VERSION ""

NS_ :

BS_:

BU_: TCM_Diesel ECM_Diesel BECMB_EPM TCM ECM Generic_BCM GWM _delete APIM BCM DCDC_VQM PAM TSTR PCM

BO_ 753 Vehicle_Stat_HS1: 8 GWM
 SG_ Em_D_Stat_UB : 54|1@0+ (1,0) [0|1] "SED"  BCM
 SG_ Em_D_Stat : 40|2@0+ (1,0) [0|3] "SED"  BCM
 SG_ TrlrAidEnbl_D_Stat_UB : 62|1@0+ (1,0) [0|1] "SED"  PCM
 SG_ TrlrAidEnbl_D_Stat : 58|3@0+ (1,0) [0|7] "SED"  ECM_Diesel,ECM,PCM
 SG_ SeatOccDrv_B_Stat_UB : 34|1@0+ (1,0) [0|1] "SED" Vector__XXX
 SG_ SeatOccDrv_B_Stat : 35|1@0+ (1,0) [0|1] "SED" Vector__XXX
 SG_ TrlrAidSetup_D_Rq_UB : 59|1@0+ (1,0) [0|1] "SED"  PAM
 SG_ TrlrAidSetup_D_Rq : 61|2@0+ (1,0) [0|3] "SED"  PAM
 SG_ TurnLampRrOut_B_Stat_UB : 36|1@0+ (1,0) [0|1] "SED"  BCM
 SG_ TurnLampRrOut_B_Stat : 37|1@0+ (1,0) [0|1] "SED"  BCM
 SG_ TurnLampRlOut_B_Stat_UB : 38|1@0+ (1,0) [0|1] "SED"  BCM
 SG_ TurnLampRlOut_B_Stat : 39|1@0+ (1,0) [0|1] "SED"  BCM
 SG_ CnvtTopPos_Up_Stat_UB : 24|1@0+ (1,0) [0|1] "SED"  BCM
 SG_ IsaOffst_D_Rq_UB : 63|1@0+ (1,0) [0|1] "SED" Vector__XXX
 SG_ GlvBoxRleas_No_Actl : 31|3@0+ (1,0) [0|7] "unitless"  BCM
 SG_ GlvBoxRleas_No_Actl_UB : 28|1@0+ (1,0) [0|1] "SED"  BCM
 SG_ ValetMode_D_Stat_UB : 20|1@0+ (1,0) [0|1] "SED"  BCM
 SG_ RollCodeValet_UB : 21|1@0+ (1,0) [0|1] "SED"  BCM
 SG_ ApaMdeStat_D_RqDrv_UB : 16|1@0+ (1,0) [0|1] "SED"  PAM
 SG_ SlMde_D_Rq : 49|2@0+ (1,0) [0|3] "SED" Vector__XXX
 SG_ IsaOffst_D_Rq : 53|4@0+ (1,0) [0|15] "SED" Vector__XXX
 SG_ ApaMdeStat_D_RqDrv : 19|3@0+ (1,0) [0|7] "SED"  PAM
 SG_ ValetMode_D_Stat : 23|2@0+ (1,0) [0|3] "SED"  BCM
 SG_ RollCodeValet : 7|16@0+ (1,0) [0|65535] "Unitless"  BCM
 SG_ CnvtTopPos_Up_Stat : 25|1@0+ (1,0) [0|1] "SED"  BCM
 SG_ CnvtTopPos_Dn_Stat_UB : 26|1@0+ (1,0) [0|1] "SED"  BCM
 SG_ CnvtTopPos_Dn_Stat : 27|1@0+ (1,0) [0|1] "SED"  BCM

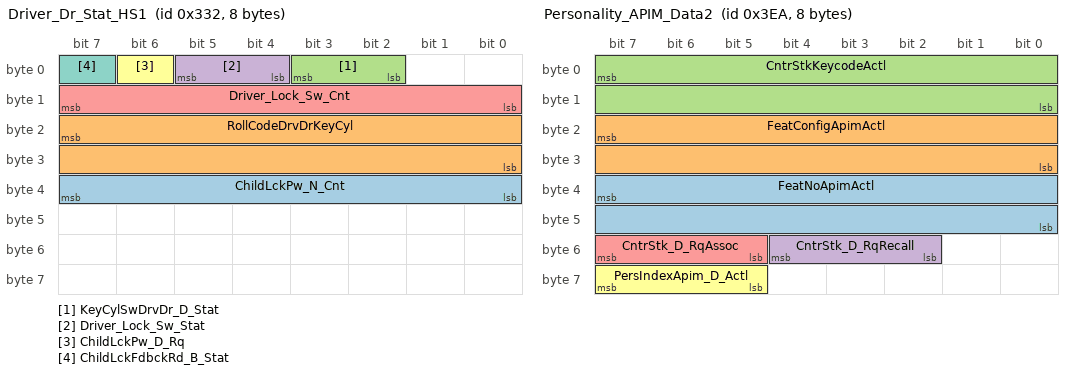
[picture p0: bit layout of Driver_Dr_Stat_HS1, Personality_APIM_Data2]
BO_ 818 Driver_Dr_Stat_HS1: 8 GWM
 SG_ ChildLckPw_N_Cnt : 39|8@0+ (1,0) [0|255] "unitless"  BCM
 SG_ RollCodeDrvDrKeyCyl : 23|16@0+ (1,0) [0|65535] "Unitless"  BCM
 SG_ KeyCylSwDrvDr_D_Stat : 3|2@0+ (1,0) [0|3] "SED"  BCM
 SG_ Driver_Lock_Sw_Stat : 5|2@0+ (1,0) [0|3] "SED"  BCM
 SG_ Driver_Lock_Sw_Cnt : 15|8@0+ (1,0) [0|255] "Cnt"  BCM
 SG_ ChildLckPw_D_Rq : 6|1@0+ (1,0) [0|1] "SED"  BCM
 SG_ ChildLckFdbckRd_B_Stat : 7|1@0+ (1,0) [0|1] "SED"  BCM

BO_ 817 Locking_Systems_2: 8 BCM
 SG_ ChildLckMde_B_Stat : 56|1@0+ (1,0) [0|1] "SED"  GWM
 SG_ VehLckInd_D_Rq : 58|2@0+ (1,0) [0|3] "SED"  GWM
 SG_ DrTgateOpen_B_Rq : 59|1@0+ (1,0) [0|1] "SED"  GWM
 SG_ DrTgateExtSwMde_B_Stat : 32|1@0+ (1,0) [0|1] "SED"  GWM
 SG_ Remote_Device_Feedback : 50|3@0+ (1,0) [0|7] "SED"  GWM
 SG_ Veh_Lock_Requestor : 55|5@0+ (1,0) [0|31] "SED"  GWM
 SG_ R_Pwr_Sliding_Dr_Rqst : 36|1@0+ (1,0) [0|1] "SED"  GWM
 SG_ Power_Liftgate_Rqst : 0|1@0+ (1,0) [0|1] "SED"  GWM
 SG_ Veh_Lock_EvNum : 47|8@0+ (1,0) [0|255] "unitless"  GWM
 SG_ Power_Decklid_Rqst : 1|1@0+ (1,0) [0|1] "SED"  GWM
 SG_ L_Pwr_Sliding_Dr_Rqst : 3|1@0+ (1,0) [0|1] "SED"  GWM
 SG_ Keyfob_Pad_Msg_Count : 15|8@0+ (1,0) [0|255] "Counts"  GWM
 SG_ Veh_Lock_Sub_Id : 63|4@0+ (1,0) [0|15] "SED"  GWM
 SG_ Veh_Lock_Status : 34|2@0+ (1,0) [0|3] "SED"  GWM
 SG_ ChildLck_D_Dsply : 7|2@0+ (1,0) [0|3] "SED"  GWM
 SG_ WindowLockout_B_Stat : 35|1@0+ (1,0) [0|1] "SED"  GWM
 SG_ RollCodeUnlock : 23|16@0+ (1,0) [0|65535] "Unitless"  GWM
 SG_ Lockmsgtxt_D_Rq : 39|3@0+ (1,0) [0|7] "SED"  GWM
 SG_ FobComm_D_Stat : 5|2@0+ (1,0) [0|3] "SED"  GWM
 SG_ LockInhibit : 2|1@0+ (1,0) [0|1] "SED"  GWM

BO_ 1002 Personality_APIM_Data2: 8 APIM
 SG_ FeatNoApimActl : 39|16@0+ (1,0) [0|65535] "Number"  GWM
 SG_ FeatConfigApimActl : 23|16@0+ (1,0) [0|65535] "Number"  GWM
 SG_ CntrStkKeycodeActl : 7|16@0+ (1,0) [0|65535] "Undefined"  GWM,BCM
 SG_ CntrStk_D_RqRecall : 52|3@0+ (1,0) [0|7] "SED"  GWM,BCM
 SG_ CntrStk_D_RqAssoc : 55|3@0+ (1,0) [0|7] "SED"  GWM,BCM
 SG_ PersIndexApim_D_Actl : 63|3@0+ (1,0) [0|7] "SED"  GWM

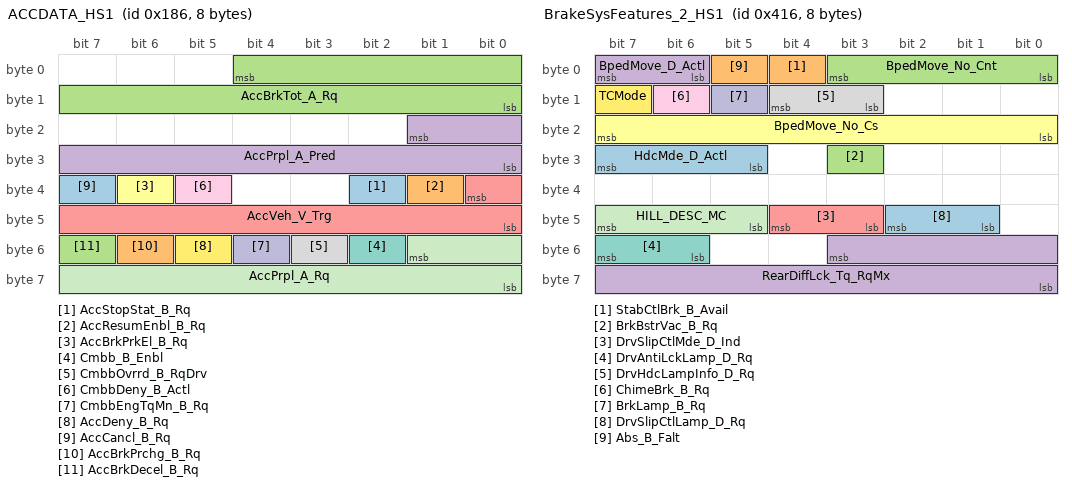
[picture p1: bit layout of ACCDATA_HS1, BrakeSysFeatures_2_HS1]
BO_ 390 ACCDATA_HS1: 8 GWM
 SG_ AccStopStat_B_Rq : 34|1@0+ (1,0) [0|1] "SED"  ECM,ECM_Diesel,PCM
 SG_ AccResumEnbl_B_Rq : 33|1@0+ (1,0) [0|1] "SED"  ECM,ECM_Diesel,PCM
 SG_ AccBrkTot_A_Rq : 4|13@0+ (0.0039,-20) [-20|11.9449] "m/s^2" Vector__XXX
 SG_ AccPrpl_A_Pred : 17|10@0+ (0.01,-5) [-5|5.23] "m/s^2"  ECM_Diesel,ECM,PCM
 SG_ AccVeh_V_Trg : 32|9@0+ (0.5,0) [0|255.5] "kph"  TCM_Diesel,ECM_Diesel,TCM,ECM,PCM
 SG_ AccBrkPrkEl_B_Rq : 38|1@0+ (1,0) [0|1] "SED" Vector__XXX
 SG_ Cmbb_B_Enbl : 50|1@0+ (1,0) [0|1] "SED" Vector__XXX
 SG_ CmbbOvrrd_B_RqDrv : 51|1@0+ (1,0) [0|1] "SED" Vector__XXX
 SG_ CmbbDeny_B_Actl : 37|1@0+ (1,0) [0|1] "SED" Vector__XXX
 SG_ CmbbEngTqMn_B_Rq : 52|1@0+ (1,0) [0|1] "SED"  ECM,ECM_Diesel,PCM
 SG_ AccPrpl_A_Rq : 49|10@0+ (0.01,-5) [-5|5.23] "m/s^2"  ECM_Diesel,ECM,PCM
 SG_ AccDeny_B_Rq : 53|1@0+ (1,0) [0|1] "SED"  ECM_Diesel,ECM,PCM
 SG_ AccCancl_B_Rq : 39|1@0+ (1,0) [0|1] "SED"  ECM_Diesel,ECM,PCM
 SG_ AccBrkPrchg_B_Rq : 54|1@0+ (1,0) [0|1] "SED" Vector__XXX
 SG_ AccBrkDecel_B_Rq : 55|1@0+ (1,0) [0|1] "SED" Vector__XXX

BO_ 1046 BrakeSysFeatures_2_HS1: 8 GWM
 SG_ HdcMde_D_Actl : 31|3@0+ (1,0) [0|7] "SED"  ECM
 SG_ StabCtlBrk_B_Avail : 4|1@0+ (1,0) [0|1] "SED" Vector__XXX
 SG_ BrkBstrVac_B_Rq : 27|1@0+ (1,0) [0|1] "Discrete"  ECM_Diesel,PCM
 SG_ RearDiffLck_Tq_RqMx : 51|12@0+ (1,0) [0|4095] "Nm"  ECM_Diesel
 SG_ DrvSlipCtlMde_D_Ind : 44|2@0+ (1,0) [0|3] "SED"  ECM_Diesel,ECM,PCM,PAM
 SG_ BpedMove_No_Cs : 23|8@0+ (1,0) [0|255] "Unitless"  ECM_Diesel,ECM,PCM
 SG_ DrvAntiLckLamp_D_Rq : 55|2@0+ (1,0) [0|3] "SED"  ECM_Diesel,PAM
 SG_ DrvHdcLampInfo_D_Rq : 12|2@0+ (1,0) [0|3] "SED" Vector__XXX
 SG_ ChimeBrk_B_Rq : 14|1@0+ (1,0) [0|1] "SED" Vector__XXX
 SG_ BrkLamp_B_Rq : 13|1@0+ (1,0) [0|1] "SED"  ECM_Diesel
 SG_ HILL_DESC_MC : 47|3@0+ (1,0) [0|7] "SED" Vector__XXX
 SG_ TCMode : 15|1@0+ (1,0) [0|1] "SED"  ECM_Diesel,ECM,PAM,PCM
 SG_ DrvSlipCtlLamp_D_Rq : 42|2@0+ (1,0) [0|3] "SED"  ECM_Diesel,ECM,PCM,PAM
 SG_ Abs_B_Falt : 5|1@0+ (1,0) [0|1] "SED"  ECM_Diesel,ECM,PCM
 SG_ BpedMove_No_Cnt : 3|4@0+ (1,0) [0|15] "Unitless"  ECM_Diesel,ECM,PCM
 SG_ BpedMove_D_Actl : 7|2@0+ (1,0) [0|3] "SED"  ECM_Diesel,ECM,PCM

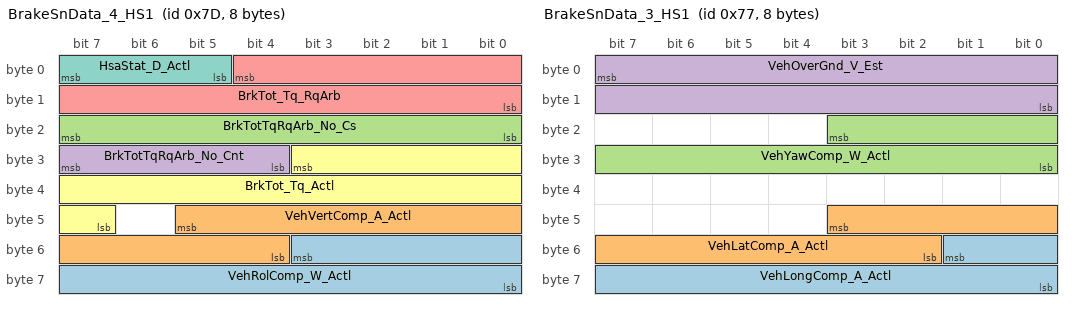
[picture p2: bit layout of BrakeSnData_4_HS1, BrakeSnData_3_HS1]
BO_ 125 BrakeSnData_4_HS1: 8 GWM
 SG_ VehRolComp_W_Actl : 51|12@0+ (0.03663,-75) [-75|74.92659] "degrees/sec" Vector__XXX
 SG_ VehVertComp_A_Actl : 45|10@0+ (0.035,-17.9) [-17.9|17.835] "m/s^2" Vector__XXX
 SG_ BrkTotTqRqArb_No_Cs : 23|8@0+ (1,0) [0|255] "Unitless"  ECM_Diesel,PCM,ECM
 SG_ BrkTotTqRqArb_No_Cnt : 31|4@0+ (1,0) [0|15] "Unitless"  ECM_Diesel,PCM,ECM
 SG_ BrkTot_Tq_RqArb : 4|13@0+ (4,0) [0|32756] "Nm"  TCM_Diesel,ECM_Diesel,TCM,ECM,PCM
 SG_ BrkTot_Tq_Actl : 27|13@0+ (4,0) [0|32756] "Nm"  ECM_Diesel,ECM,PCM
 SG_ HsaStat_D_Actl : 7|3@0+ (1,0) [0|7] "SED"  ECM_Diesel,ECM,PCM

BO_ 119 BrakeSnData_3_HS1: 8 GWM
 SG_ VehLongComp_A_Actl : 49|10@0+ (0.035,-17.9) [-17.9|17.835] "m/s^2"  TCM_Diesel,ECM_Diesel,TCM,ECM,PCM
 SG_ VehLatComp_A_Actl : 43|10@0+ (0.035,-17.9) [-17.9|17.835] "m/s^2"  TCM_Diesel,ECM_Diesel,TCM,ECM,PCM
 SG_ VehYawComp_W_Actl : 19|12@0+ (0.03663,-75) [-75|74.92659] "deg/s"  TCM_Diesel,ECM_Diesel,TCM,ECM,PAM,PCM
 SG_ VehOverGnd_V_Est : 7|16@0+ (0.01,0) [0|655.33] "kph"  BCM

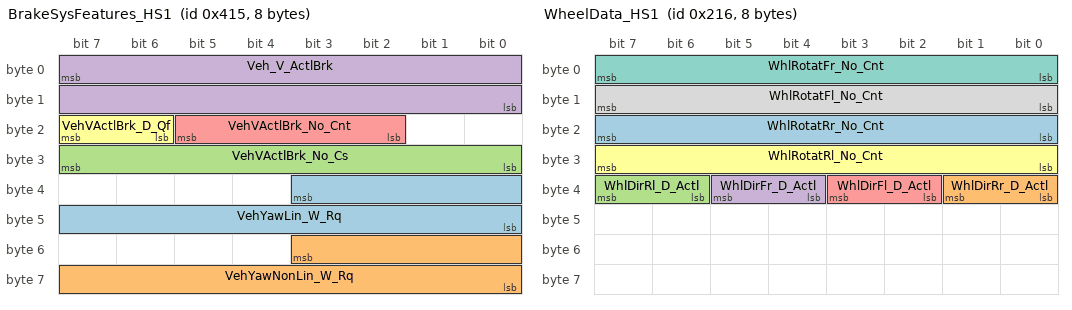
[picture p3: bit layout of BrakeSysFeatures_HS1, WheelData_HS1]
BO_ 1045 BrakeSysFeatures_HS1: 8 GWM
 SG_ VehYawLin_W_Rq : 35|12@0+ (0.03663,-75) [-75|74.92659] "deg/s" Vector__XXX
 SG_ VehYawNonLin_W_Rq : 51|12@0+ (0.03663,-75) [-75|74.92659] "deg/s" Vector__XXX
 SG_ VehVActlBrk_No_Cs : 31|8@0+ (1,0) [0|255] "Unitless"  TCM,TCM_Diesel,ECM_Diesel,ECM,PCM,BCM
 SG_ Veh_V_ActlBrk : 7|16@0+ (0.01,0) [0|655.35] "kph"  TCM,TCM_Diesel,ECM_Diesel,ECM,PCM,PAM,BCM
 SG_ VehVActlBrk_No_Cnt : 21|4@0+ (1,0) [0|15] "Unitless"  TCM,TCM_Diesel,ECM_Diesel,ECM,PCM,BCM
 SG_ VehVActlBrk_D_Qf : 23|2@0+ (1,0) [0|3] "SED"  TCM,TCM_Diesel,ECM_Diesel,ECM,PCM,PAM,BCM

BO_ 534 WheelData_HS1: 8 GWM
 SG_ WhlRotatRr_No_Cnt : 23|8@0+ (1,0) [0|255] "Unitless"  BCM,PAM
 SG_ WhlDirRr_D_Actl : 33|2@0+ (1,0) [0|3] "SED"  PAM
 SG_ WhlDirRl_D_Actl : 39|2@0+ (1,0) [0|3] "SED"  PAM
 SG_ WhlDirFr_D_Actl : 37|2@0+ (1,0) [0|3] "SED"  PAM
 SG_ WhlDirFl_D_Actl : 35|2@0+ (1,0) [0|3] "SED"  PAM
 SG_ WhlRotatRl_No_Cnt : 31|8@0+ (1,0) [0|255] "Unitless"  BCM,PAM
 SG_ WhlRotatFr_No_Cnt : 7|8@0+ (1,0) [0|255] "Unitless"  BCM,PAM
 SG_ WhlRotatFl_No_Cnt : 15|8@0+ (1,0) [0|255] "Unitless"  BCM,PAM

BO_ 531 DesiredTorqBrk_HS1: 8 GWM
 SG_ AccStopActv_B_ActlBrk : 22|1@0+ (1,0) [0|1] "SED"  ECM,ECM_Diesel,PCM
 SG_ TracCtlPtActv_B_Actl : 31|1@0+ (1,0) [0|1] "SED"  TCM_Diesel,ECM_Diesel,TCM,ECM,PCM,PAM
 SG_ StabCtlBrkActv_B_Actl : 23|1@0+ (1,0) [0|1] "SED"  TCM_Diesel,ECM_Diesel,TCM,ECM,PCM,PAM
 SG_ CmbbBrkPrchg_B_Actl : 59|1@0+ (1,0) [0|1] "SED" Vector__XXX
 SG_ CmbbBrkDecel_B_Actl : 58|1@0+ (1,0) [0|1] "SED" Vector__XXX
 SG_ CmbbBaSensInc_B_Actl : 57|1@0+ (1,0) [0|1] "SED" Vector__XXX
 SG_ AccBrkWarm_B_Actl : 63|1@0+ (1,0) [0|1] "SED" Vector__XXX
 SG_ AccBrkTotTqMn_B_Actl : 62|1@0+ (1,0) [0|1] "SED" Vector__XXX
 SG_ AccBrkPrchgActv_B_Actl : 61|1@0+ (1,0) [0|1] "SED" Vector__XXX
 SG_ AccBrkDis_B_Actl : 44|1@0+ (1,0) [0|1] "SED" Vector__XXX
 SG_ AccBrkDeny_B_Actl : 42|1@0+ (1,0) [0|1] "SED"  ECM_Diesel,ECM,PCM
 SG_ AccBrkActv_B_Actl : 43|1@0+ (1,0) [0|1] "SED"  ECM_Diesel
 SG_ PrplDrgCtlActv_B_Actl : 46|1@0+ (1,0) [0|1] "SED"  TCM_Diesel,ECM_Diesel,TCM,ECM,PCM
 SG_ PrplWhlTot_Tq_RqMx : 7|16@0+ (4,-131072) [-131072|131068] "Nm"  ECM_Diesel,ECM,PCM
 SG_ AbsActv_B_Actl : 45|1@0+ (1,0) [0|1] "SED"  TCM_Diesel,ECM_Diesel,TCM,ECM,PCM,PAM
 SG_ CmbbBrkDis_B_Actl : 56|1@0+ (1,0) [0|1] "SED" Vector__XXX
 SG_ CmbbDeny_B_ActlBrk : 60|1@0+ (1,0) [0|1] "SED"  ECM,ECM_Diesel,PCM
 SG_ CcDis_B_Cmd : 47|1@0+ (1,0) [0|1] "SED"  ECM_Diesel,ECM,PCM
 SG_ VehLongOvrGnd_A_Est : 41|10@0+ (0.035,-17.9) [-17.9|17.835] "m/s^2" Vector__XXX
 SG_ PrkBrkStatus : 26|3@0+ (1,0) [0|7] "SED"  TCM,TCM_Diesel,ECM_Diesel,ECM,BCM,PCM

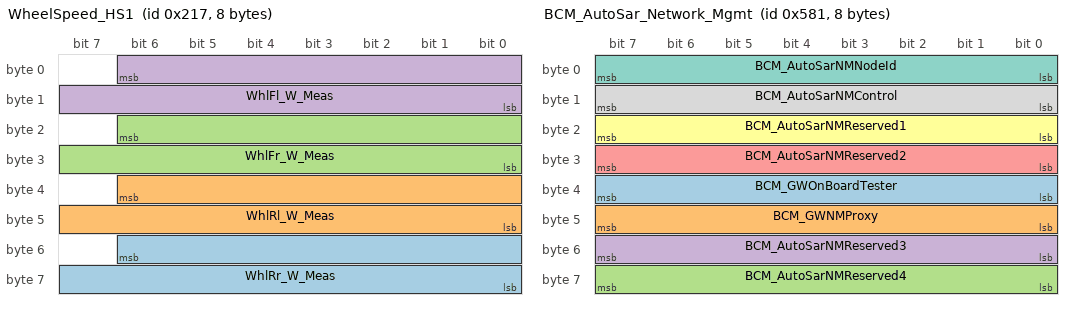
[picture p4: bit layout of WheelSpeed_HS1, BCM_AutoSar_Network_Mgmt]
BO_ 535 WheelSpeed_HS1: 8 GWM
 SG_ WhlRr_W_Meas : 54|15@0+ (0.01,0) [0|327.65] "rad/s"  TCM_Diesel,ECM_Diesel,TCM,ECM,PAM,BCM,PCM
 SG_ WhlRl_W_Meas : 38|15@0+ (0.01,0) [0|327.65] "rad/s"  TCM_Diesel,ECM_Diesel,TCM,ECM,BCM,PCM,PAM
 SG_ WhlFr_W_Meas : 22|15@0+ (0.01,0) [0|327.65] "rad/s"  TCM_Diesel,ECM_Diesel,TCM,ECM,BCM,PCM,PAM
 SG_ WhlFl_W_Meas : 6|15@0+ (0.01,0) [0|327.65] "rad/s"  TCM_Diesel,ECM_Diesel,TCM,ECM,BCM,PCM,PAM

BO_ 1409 BCM_AutoSar_Network_Mgmt: 8 BCM
 SG_ BCM_GWOnBoardTester : 39|8@0+ (1,0) [0|255] "unitless"  APIM,BECMB_EPM,ECM,ECM_Diesel,GWM,PCM,TCM,TCM_Diesel
 SG_ BCM_GWNMProxy : 47|8@0+ (1,0) [0|255] "unitless"  APIM,BECMB_EPM,ECM,ECM_Diesel,GWM,PCM,TCM,TCM_Diesel
 SG_ BCM_AutoSarNMReserved4 : 63|8@0+ (1,0) [0|255] "unitless"  APIM,BECMB_EPM,ECM,ECM_Diesel,GWM,PCM,TCM,TCM_Diesel
 SG_ BCM_AutoSarNMReserved3 : 55|8@0+ (1,0) [0|255] "unitless"  APIM,BECMB_EPM,ECM,ECM_Diesel,GWM,PCM,TCM,TCM_Diesel
 SG_ BCM_AutoSarNMReserved2 : 31|8@0+ (1,0) [0|255] "unitless"  APIM,BECMB_EPM,ECM,ECM_Diesel,GWM,PCM,TCM,TCM_Diesel
 SG_ BCM_AutoSarNMReserved1 : 23|8@0+ (1,0) [0|255] "unitless"  APIM,BECMB_EPM,ECM,ECM_Diesel,GWM,PCM,TCM,TCM_Diesel
 SG_ BCM_AutoSarNMNodeId : 7|8@0+ (1,0) [0|255] "unitless"  APIM,BECMB_EPM,ECM,ECM_Diesel,GWM,PCM,TCM,TCM_Diesel
 SG_ BCM_AutoSarNMControl : 15|8@0+ (1,0) [0|255] "unitless"  APIM,BECMB_EPM,ECM,ECM_Diesel,GWM,PCM,TCM,TCM_Diesel

BO_ 1846 TesterPhysicalReqPAM: 8 TSTR
 SG_ TesterPhysicalReqPAM : 7|64@0+ (1,0) [0|1.84467E+019] "unitless"  PAM

BO_ 1854 TesterPhysicalResPAM: 8 PAM
 SG_ TesterPhysicalResPAM : 7|64@0+ (1,0) [0|1.84467E+019] "unitless"  TSTR

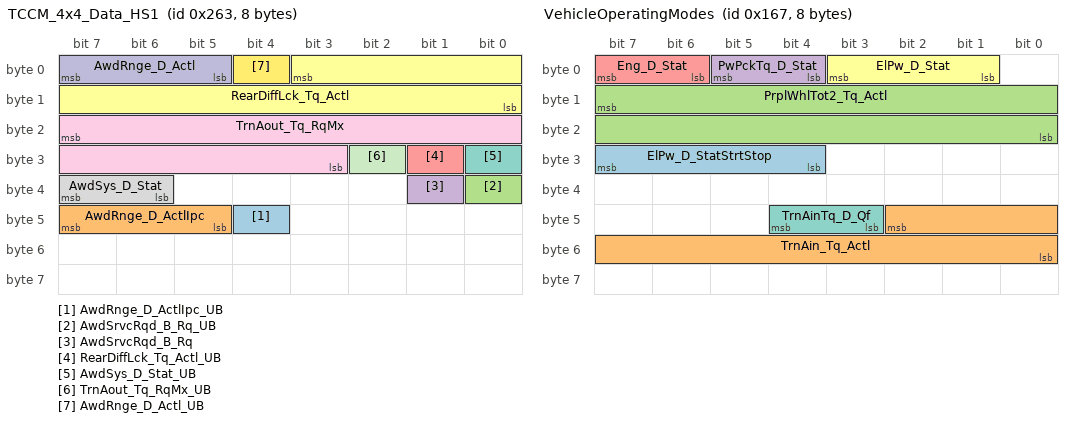
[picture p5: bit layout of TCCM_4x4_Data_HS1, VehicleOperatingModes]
BO_ 611 TCCM_4x4_Data_HS1: 8 GWM
 SG_ AwdRnge_D_ActlIpc_UB : 44|1@0+ (1,0) [0|1] "SED" Vector__XXX
 SG_ AwdRnge_D_ActlIpc : 47|3@0+ (1,0) [0|7] "SED"  ECM_Diesel
 SG_ AwdSrvcRqd_B_Rq_UB : 32|1@0+ (1,0) [0|1] "SED"  PCM,TCM_Diesel,TCM
 SG_ AwdSrvcRqd_B_Rq : 33|1@0+ (1,0) [0|1] "SED"  TCM_Diesel,TCM,PCM
 SG_ RearDiffLck_Tq_Actl_UB : 25|1@0+ (1,0) [0|1] "SED"  ECM_Diesel,ECM,PCM
 SG_ RearDiffLck_Tq_Actl : 3|12@0+ (1,0) [0|4093] "Nm"  ECM_Diesel,ECM,PCM
 SG_ AwdSys_D_Stat_UB : 24|1@0+ (1,0) [0|1] "SED" Vector__XXX
 SG_ AwdSys_D_Stat : 39|2@0+ (1,0) [0|3] "SED"  ECM_Diesel,ECM,PCM
 SG_ TrnAout_Tq_RqMx : 23|13@0+ (1,-1250) [-1250|6941] "Nm"  ECM_Diesel,ECM,PCM
 SG_ AwdRnge_D_Actl : 7|3@0+ (1,0) [0|7] "SED"  TCM_Diesel,ECM_Diesel,TCM,ECM,PCM
 SG_ TrnAout_Tq_RqMx_UB : 26|1@0+ (1,0) [0|1] "SED" Vector__XXX
 SG_ AwdRnge_D_Actl_UB : 4|1@0+ (1,0) [0|1] "SED"  TCM_Diesel,ECM_Diesel,TCM,ECM,PCM

BO_ 1109 eCall_Info_HS1: 8 APIM
 SG_ eCallConfirmation : 7|3@0+ (1,0) [0|7] "SED"  GWM,BCM

BO_ 359 VehicleOperatingModes: 8 PCM
 SG_ ElPw_D_StatStrtStop : 31|4@0+ (1,0) [0|15] "SED"  GWM
 SG_ TrnAin_Tq_Actl : 42|11@0+ (1,-500) [-500|1547] "Nm"  GWM
 SG_ PrplWhlTot2_Tq_Actl : 15|16@0+ (4,-131072) [-131072|131060] "Nm"  GWM
 SG_ PwPckTq_D_Stat : 5|2@0+ (1,0) [0|3] "SED"  TCM,TCM_Diesel,PAM,BCM,GWM
 SG_ Eng_D_Stat : 7|2@0+ (1,0) [0|3] "SED"  DCDC_VQM,BCM,GWM
 SG_ ElPw_D_Stat : 3|3@0+ (1,0) [0|7] "SED"  TCM,TCM_Diesel,PAM,BCM,GWM
 SG_ TrnAinTq_D_Qf : 44|2@0+ (1,0) [0|3] "SED"  GWM

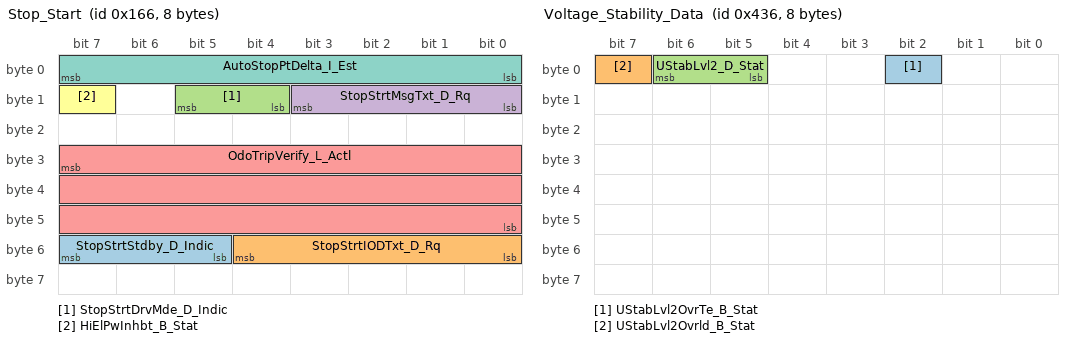
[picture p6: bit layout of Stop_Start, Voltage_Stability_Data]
BO_ 358 Stop_Start: 8 PCM
 SG_ StopStrtStdby_D_Indic : 55|3@0+ (1,0) [0|7] "SED"  GWM
 SG_ StopStrtIODTxt_D_Rq : 52|5@0+ (1,0) [0|31] "SED"  GWM
 SG_ StopStrtDrvMde_D_Indic : 13|2@0+ (1,0) [0|3] "SED"  BCM,GWM
 SG_ StopStrtMsgTxt_D_Rq : 11|4@0+ (1,0) [0|15] "SED"  GWM
 SG_ OdoTripVerify_L_Actl : 31|24@0+ (0.1,0) [0|1677721.4] "km"  GWM
 SG_ HiElPwInhbt_B_Stat : 15|1@0+ (1,0) [0|1] "SED"  GWM
 SG_ AutoStopPtDelta_I_Est : 7|8@0+ (1,-127) [-127|127] "Amps"  GWM,BCM

BO_ 1078 Voltage_Stability_Data: 8 DCDC_VQM
 SG_ UStabLvl2OvrTe_B_Stat : 2|1@0+ (1,0) [0|1] "SED"  ECM_Diesel,ECM,PCM
 SG_ UStabLvl2Ovrld_B_Stat : 7|1@0+ (1,0) [0|1] "SED"  ECM_Diesel,ECM,PCM
 SG_ UStabLvl2_D_Stat : 6|2@0+ (1,0) [0|3] "SED"  ECM_Diesel,ECM,PCM

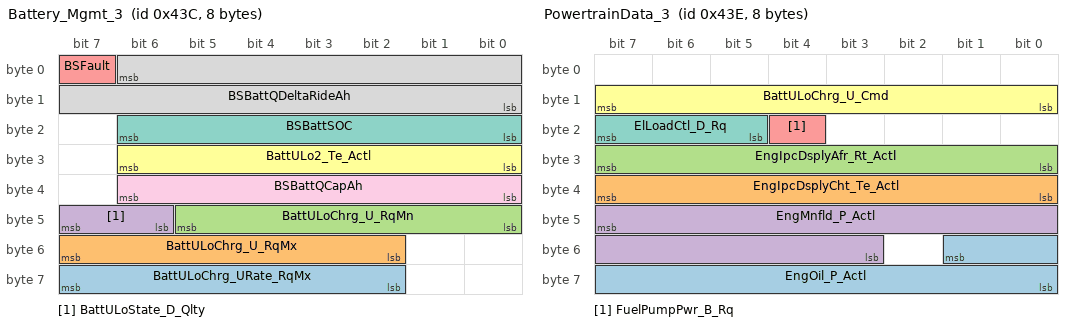
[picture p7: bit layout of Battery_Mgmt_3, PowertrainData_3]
BO_ 1084 Battery_Mgmt_3: 8 BCM
 SG_ BattULoChrg_URate_RqMx : 63|6@0+ (0.1,0) [0|6.3] "volts/second"  ECM_Diesel,ECM,PCM
 SG_ BattULoChrg_U_RqMx : 55|6@0+ (0.1,10.6) [10.6|16.9] "volt"  ECM_Diesel,ECM,PCM
 SG_ BattULoChrg_U_RqMn : 45|6@0+ (0.1,10.6) [10.6|16.9] "volt"  ECM_Diesel,ECM,PCM
 SG_ BattULoState_D_Qlty : 47|2@0+ (1,0) [0|3] "SED"  ECM_Diesel,ECM,GWM,PCM
 SG_ BSFault : 7|1@0+ (1,0) [0|1] "SED"  ECM_Diesel,ECM,PCM
 SG_ BattULo2_Te_Actl : 30|7@0+ (1,-40) [-40|86] "degC"  ECM_Diesel,ECM,PCM
 SG_ BSBattSOC : 22|7@0+ (1,0) [0|127] "%"  ECM_Diesel,ECM,GWM,PCM
 SG_ BSBattQDeltaRideAh : 6|15@0+ (0.0078125,-100) [-100|155.9921875] "ampere*hour"  ECM_Diesel,ECM,PCM
 SG_ BSBattQCapAh : 38|7@0+ (1,0) [0|127] "ampere*hour"  ECM_Diesel,ECM,PCM

BO_ 1086 PowertrainData_3: 8 PCM
 SG_ EngOil_P_Actl : 49|10@0+ (1,0) [0|1023] "kilopascal"  GWM
 SG_ EngIpcDsplyCht_Te_Actl : 39|8@0+ (1,-60) [-60|195] "degC"  GWM
 SG_ EngIpcDsplyAfr_Rt_Actl : 31|8@0+ (0.1,0) [0|25.5] "unitless"  GWM
 SG_ EngMnfld_P_Actl : 47|13@0+ (0.1,-206.8) [-206.8|612.3] "kilopascal"  GWM
 SG_ FuelPumpPwr_B_Rq : 20|1@0+ (1,0) [0|1] "SED"  GWM,BCM
 SG_ BattULoChrg_U_Cmd : 15|8@0+ (0.025,10.6) [10.6|16.975] "volt"  GWM,BCM
 SG_ ElLoadCtl_D_Rq : 23|3@0+ (1,0) [0|7] "SED"  GWM,BCM

BO_TX_BU_ 359 : ECM_Diesel,ECM,PCM;
BO_TX_BU_ 358 : ECM_Diesel,ECM,PCM;
BO_TX_BU_ 1086 : ECM_Diesel,ECM,PCM;
CM_ SG_ 753 TurnLampRrOut_B_Stat "Signal not transmitted on vehicles without a BCMB module.";
CM_ SG_ 753 TurnLampRlOut_B_Stat "Signal not transmitted on vehicles without a BCMB module.";
CM_ SG_ 753 CnvtTopPos_Up_Stat "Signal not transmitted on vehicles without convertible tops.";
CM_ SG_ 753 CnvtTopPos_Dn_Stat "Signal not transmitted on vehicles without convertible tops.";
CM_ SG_ 390 AccStopStat_B_Rq "ABSGenSigTimeoutTime=1000";
CM_ SG_ 390 AccBrkTot_A_Rq "ABSGenSigTimeoutTime=1000";
CM_ SG_ 390 AccBrkPrkEl_B_Rq "ABSGenSigTimeoutTime=1000";
CM_ SG_ 390 AccPrpl_A_Rq "PCMGenSigTimeoutTime=1000";
CM_ SG_ 390 AccBrkPrchg_B_Rq "ABSGenSigTimeoutTime=1000";
CM_ SG_ 390 AccBrkDecel_B_Rq "ABSGenSigTimeoutTime=1000";
CM_ SG_ 1046 DrvAntiLckLamp_D_Rq "update value table v8.34, not align w/GSDB, need etracker.  ABS & IPC implemented as updated.";
CM_ SG_ 1046 TCMode "Signal data set to 0x0 for ABS only vehicle option content";
CM_ SG_ 1046 BpedMove_D_Actl "CCMGenSigTimeoutTime=1000";
CM_ BO_ 531 "IC is NOT to use data in this message for displays, Used data from 415 instead.";
CM_ SG_ 531 VehLongOvrGnd_A_Est "CCMGenSigTimeoutTime=1000";
CM_ SG_ 1409 BCM_GWOnBoardTester "Signal not transmitted on gas, diesel and HEV.  Only supported on PHEV.";
CM_ SG_ 1409 BCM_GWNMProxy "Signal not transmitted on gas, diesel and HEV.  Only supported on PHEV.";
CM_ SG_ 1409 BCM_AutoSarNMReserved4 "Signal not transmitted on gas, diesel and HEV.  Only supported on PHEV.";
CM_ SG_ 1409 BCM_AutoSarNMReserved3 "Signal not transmitted on gas, diesel and HEV.  Only supported on PHEV.";
CM_ SG_ 1409 BCM_AutoSarNMReserved2 "Signal not transmitted on gas, diesel and HEV.  Only supported on PHEV.";
CM_ SG_ 1409 BCM_AutoSarNMReserved1 "Signal not transmitted on gas, diesel and HEV.  Only supported on PHEV.";
CM_ SG_ 1409 BCM_AutoSarNMNodeId "Signal not transmitted on gas, diesel and HEV.  Only supported on PHEV.";
CM_ SG_ 1409 BCM_AutoSarNMControl "Signal not transmitted on gas, diesel and HEV.  Only supported on PHEV.";
CM_ SG_ 611 AwdSrvcRqd_B_Rq "Signal not transmitted on programs that do not have AWD.";
CM_ SG_ 359 TrnAin_Tq_Actl "Signal not transmitted on HEV variances.";
CM_ SG_ 359 TrnAinTq_D_Qf "Signal not transmitted on HEV variances.";
CM_ SG_ 358 HiElPwInhbt_B_Stat "Signal not transmitted on HEV programs";
CM_ SG_ 358 AutoStopPtDelta_I_Est "Signal not transmitted on vehicles that do not have autostop/stop-start feature.";
CM_ SG_ 1086 EngOil_P_Actl "Tx by ECM_G only on P552
";
CM_ SG_ 1086 EngIpcDsplyCht_Te_Actl "ECM gas Tx, PCM and ECM_Diesel does not transmit
";
CM_ SG_ 1086 EngIpcDsplyAfr_Rt_Actl "Not transmitted by PCM or ECM Diesel";
CM_ SG_ 1086 EngMnfld_P_Actl "
";
CM_ SG_ 1086 ElLoadCtl_D_Rq "Signal not transmitted on HEV variants.";
BA_DEF_ SG_  "U_UP375_MY19_Gas_Rx" ENUM  "No","Yes";
BA_DEF_ SG_  "U_UP375_MY19_Diesel_Rx" ENUM  "No","Yes";
BA_DEF_ SG_  "U_CD4_MY19_Diesel_Rx" ENUM  "No","Yes";
BA_DEF_ SG_  "U_CD4_MY19_Gas_Rx" ENUM  "No","Yes";
BA_DEF_ SG_  "U_CD4_MY19_Hev_Rx" ENUM  "No","Yes";
BA_DEF_ SG_  "U_CD4_MY19_Phev_Rx" ENUM  "No","Yes";
BA_DEF_ SG_  "U_V36X_MY19_Rx" ENUM  "No","Yes";
BA_DEF_ SG_  "U_V36X_MY18_5_Gas_Tx" ENUM  "No","Yes";
BA_DEF_ SG_  "U_V36X_MY18_5_Hev_Tx" ENUM  "No","Yes";
BA_DEF_ SG_  "U_V363E_N_MY19_5_20_Gas_Rx" ENUM  "No","Yes";
BA_DEF_ SG_  "U_V363E_N_MY19_5_20_Diesel_Rx" ENUM  "No","Yes";
BA_DEF_ SG_  "U_V36X_MY19_5_Diesel_Tx" ENUM  "No","Yes";
BA_DEF_ SG_  "U_V363E_N_MY19_5_20_Gas_Tx" ENUM  "No","Yes";
BA_DEF_ SG_  "U_V363E_N_MY19_5_20_Diesel_Tx" ENUM  "No","Yes";
BA_DEF_ SG_  "U_S550_MY18_Gas_Rx" ENUM  "No","Yes";
BA_DEF_ SG_  "U_V408_MY18_Gas_Rx" ENUM  "No","Yes";
BA_DEF_ SG_  "U_V408_MY18_Diesel_Rx" ENUM  "No","Yes";
BA_DEF_ SG_  "U_P552_MY18_5_Gas_Rx" ENUM  "No","Yes";
BA_DEF_ SG_  "U_P552_MY18_5_Diesel_Rx" ENUM  "No","Yes";
BA_DEF_ SG_  "U_U502_MY17_Gas_Tx" ENUM  "No","Yes";
BA_DEF_ SG_  "U_CD4_MY18_Diesel_Tx" ENUM  "No","Yes";
BA_DEF_ SG_  "U_CD4_MY18_Gas_Tx" ENUM  "No","Yes";
BA_DEF_ SG_  "U_CD4_MY18_Hev_Tx" ENUM  "No","Yes";
BA_DEF_ SG_  "U_CD4_MY18_Phev_Tx" ENUM  "No","Yes";
BA_DEF_ SG_  "U_S550_MY18_Gas_Tx" ENUM  "No","Yes";
BA_DEF_ SG_  "U_V408_MY18_Gas_Tx" ENUM  "No","Yes";
BA_DEF_ SG_  "U_V408_MY18_Diesel_Tx" ENUM  "No","Yes";
BA_DEF_ SG_  "U_V36X_MY18_5_Diesel_Tx" ENUM  "No","Yes";
BA_DEF_ SG_  "U_P552_MY18_5_Gas_Tx" ENUM  "No","Yes";
BA_DEF_ SG_  "U_P552_MY18_5_Diesel_Tx" ENUM  "No","Yes";
BA_DEF_ SG_  "U_P552_MY18_Gas_Rx" ENUM  "No","Yes";
BA_DEF_ SG_  "U_U55x_MY18_Gas_Rx" ENUM  "No","Yes";
BA_DEF_ SG_  "U_P552_MY18_Gas_Tx" ENUM  "No","Yes";
BA_DEF_ SG_  "U_U55x_MY18_Gas_Tx" ENUM  "No","Yes";
BA_DEF_ BO_  "FrameGatewayNetwork" STRING ;
BA_DEF_ SG_  "U_C489_MY17_Gas_Rx" ENUM  "No","Yes";
BA_DEF_ SG_  "U_CD43_MY17_Gas_Rx" ENUM  "No","Yes";
BA_DEF_ SG_  "U_B515_MCA_MY17_Diesel_Rx" ENUM  "No","Yes";
BA_DEF_ SG_  "U_CD43_MY17_Gas_Tx" ENUM  "No","Yes";
BA_DEF_ SG_  "U_P552_MY17_Gas_Tx" ENUM  "No","Yes";
BA_DEF_ SG_  "U_CD4_MY17_Diesel_Rx" ENUM  "No","Yes";
BA_DEF_ SG_  "U_CD4_MY17_Gas_Rx" ENUM  "No","Yes";
BA_DEF_ SG_  "U_CD4_MY17_Hev_Rx" ENUM  "No","Yes";
BA_DEF_ SG_  "U_CD4_MY17_Phev_Rx" ENUM  "No","Yes";
BA_DEF_ SG_  "U_CD42_MY16_Diesel_Rx" ENUM  "No","Yes";
BA_DEF_ SG_  "U_CD42_MY16_Gas_Rx" ENUM  "No","Yes";
BA_DEF_ SG_  "U_CD4_MY17_Gas_Tx" ENUM  "No","Yes";
BA_DEF_ SG_  "U_C489_MY16_Gas_Tx" ENUM  "No","Yes";
BA_DEF_ SG_  "U_CD42_MY16_Diesel_Tx" ENUM  "No","Yes";
BA_DEF_ SG_  "U_CD42_MY16_Gas_Tx" ENUM  "No","Yes";
BA_DEF_ SG_  "U_CD42_MY15_Diesel_Rx" ENUM  "No","Yes";
BA_DEF_ SG_  "U_U502_MY16_Gas_Rx" ENUM  "No","Yes";
BA_DEF_ SG_  "U_P558_MY17_Gas_Rx" ENUM  "No","Yes";
BA_DEF_ SG_  "U_P558_MY17_Diesel_Rx" ENUM  "No","Yes";
BA_DEF_ SG_  "U_V36X_MY16_5_Diesel_Rx" ENUM  "No","Yes";
BA_DEF_ SG_  "U_CD42_MY15_Diesel_Tx" ENUM  "No","Yes";
BA_DEF_ SG_  "U_U502_MY16_Gas_Tx" ENUM  "No","Yes";
BA_DEF_ SG_  "U_P558_MY17_Gas_Tx" ENUM  "No","Yes";
BA_DEF_ SG_  "U_P558_MY17_Diesel_Tx" ENUM  "No","Yes";
BA_DEF_ SG_  "GenSigTimeoutTime_TCM" INT 0 100000;
BA_DEF_ SG_  "GenSigTimeoutTime_ECM" INT 0 100000;
BA_DEF_ SG_  "GenSigTimeoutTime_ECM_HEV" INT 0 100000;
BA_DEF_ SG_  "GenSigTimeoutTime_PCM" INT 0 100000;
BA_DEF_ BO_  "FrameGatewayMS1" HEX 0 1407;
BA_DEF_ BO_  "FrameGatewayHS2" HEX 0 1407;
BA_DEF_ BO_  "NetworkInitialization" ENUM  "No","Yes";
BA_DEF_ BO_  "FrameGatewayId" HEX 0 1407;
BA_DEF_ BO_  "GenMsgStartDelayTime" INT 0 10000;
BA_DEF_ BO_  "GenMsgDelayTime" INT 0 1000;
BA_DEF_ BO_  "GenMsgCycleTime" INT 0 100000;
BA_DEF_ BO_  "GenMsgSendType" ENUM  "FixedPeriodic","Event","EnabledPeriodic","NotUsed","NotUsed","EventPeriodic","NotUsed","NotUsed","NoMsgSendType";
BA_DEF_ SG_  "U_CD4_MY14_Phev_Tx" ENUM  "No","Yes";
BA_DEF_ SG_  "U_CD4_MY14_Hev_Tx" ENUM  "No","Yes";
BA_DEF_ SG_  "U_CD4_MY14_Gas_Tx" ENUM  "No","Yes";
BA_DEF_ SG_  "U_CD4_MY14_Diesel_Tx" ENUM  "No","Yes";
BA_DEF_ SG_  "U_CD43_MY16_Gas_Tx" ENUM  "No","Yes";
BA_DEF_ SG_  "U_UP375_MY15_Diesel_Tx" ENUM  "No","Yes";
BA_DEF_ SG_  "U_UP375_MY15_Gas_Tx" ENUM  "No","Yes";
BA_DEF_ SG_  "U_U502_MY15_Gas_Tx" ENUM  "No","Yes";
BA_DEF_ SG_  "U_C489_MY14_Gas_Tx" ENUM  "No","Yes";
BA_DEF_ SG_  "U_S550_MY15_Gas_Tx" ENUM  "No","Yes";
BA_DEF_ SG_  "U_P552_MY15_Gas_Tx" ENUM  "No","Yes";
BA_DEF_ SG_  "U_CD42_MY14_Gas_Tx" ENUM  "No","Yes";
BA_DEF_ SG_  "U_CD42_MY14_Diesel_Tx" ENUM  "No","Yes";
BA_DEF_ SG_  "U_CD4_MY13_Phev_Tx" ENUM  "No","Yes";
BA_DEF_ SG_  "U_CD4_MY13_Hev_Tx" ENUM  "No","Yes";
BA_DEF_ SG_  "U_CD4_MY13_Gas_Tx" ENUM  "No","Yes";
BA_DEF_ SG_  "U_CD4_MY13_Diesel_Tx" ENUM  "No","Yes";
BA_DEF_ SG_  "U_CD4_MY14_Phev_Rx" ENUM  "No","Yes";
BA_DEF_ SG_  "U_CD4_MY14_Hev_Rx" ENUM  "No","Yes";
BA_DEF_ SG_  "U_CD4_MY14_Gas_Rx" ENUM  "No","Yes";
BA_DEF_ SG_  "U_CD4_MY14_Diesel_Rx" ENUM  "No","Yes";
BA_DEF_ SG_  "U_CD43_MY16_Gas_Rx" ENUM  "No","Yes";
BA_DEF_ SG_  "U_UP375_MY15_Diesel_Rx" ENUM  "No","Yes";
BA_DEF_ SG_  "U_UP375_MY15_Gas_Rx" ENUM  "No","Yes";
BA_DEF_ SG_  "U_B479_MY15_Gas_Rx" ENUM  "No","Yes";
BA_DEF_ SG_  "U_U502_MY15_Gas_Rx" ENUM  "No","Yes";
BA_DEF_ SG_  "U_C489_MY14_Gas_Rx" ENUM  "No","Yes";
BA_DEF_ SG_  "U_S550_MY15_Gas_Rx" ENUM  "No","Yes";
BA_DEF_ SG_  "U_P552_MY15_Gas_Rx" ENUM  "No","Yes";
BA_DEF_ SG_  "U_CD42_MY14_Gas_Rx" ENUM  "No","Yes";
BA_DEF_ SG_  "U_CD42_MY14_Diesel_Rx" ENUM  "No","Yes";
BA_DEF_ SG_  "U_CD4_MY13_Phev_Rx" ENUM  "No","Yes";
BA_DEF_ SG_  "U_CD4_MY13_Hev_Rx" ENUM  "No","Yes";
BA_DEF_ SG_  "U_CD4_MY13_Gas_Rx" ENUM  "No","Yes";
BA_DEF_ SG_  "U_CD4_MY13_Diesel_Rx" ENUM  "No","Yes";
BA_DEF_ SG_  "ContentDependant" ENUM  "No","Yes";
BA_DEF_ SG_  "GenSigStartValue" INT 0 1000000000;
BA_DEF_ SG_  "CrossOver_InfoCAN" ENUM  "No","Yes";
BA_DEF_ SG_  "WakeupSignal" ENUM  "No","Yes";
BA_DEF_ SG_  "GenSigSendType" ENUM  "Cyclic","OnWrite","vector_leerstring","OnChange","vector_leerstring","IfActive","vector_leerstring","NoSigSendType";
BA_DEF_ BO_  "NmAsrMessage" ENUM  "No","Yes";
BA_DEF_ BO_  "DiagRequest" ENUM  "No","Yes";
BA_DEF_ BO_  "DiagResponse" ENUM  "No","Yes";
BA_DEF_ BO_  "GenMsgILSupport" ENUM  "No","Yes";
BA_DEF_DEF_  "U_UP375_MY19_Gas_Rx" "No";
BA_DEF_DEF_  "U_UP375_MY19_Diesel_Rx" "No";
BA_DEF_DEF_  "U_CD4_MY19_Diesel_Rx" "No";
BA_DEF_DEF_  "U_CD4_MY19_Gas_Rx" "No";
BA_DEF_DEF_  "U_CD4_MY19_Hev_Rx" "No";
BA_DEF_DEF_  "U_CD4_MY19_Phev_Rx" "No";
BA_DEF_DEF_  "U_V36X_MY19_Rx" "No";
BA_DEF_DEF_  "U_V36X_MY18_5_Gas_Tx" "No";
BA_DEF_DEF_  "U_V36X_MY18_5_Hev_Tx" "No";
BA_DEF_DEF_  "U_V363E_N_MY19_5_20_Gas_Rx" "No";
BA_DEF_DEF_  "U_V363E_N_MY19_5_20_Diesel_Rx" "No";
BA_DEF_DEF_  "U_V36X_MY19_5_Diesel_Tx" "No";
BA_DEF_DEF_  "U_V363E_N_MY19_5_20_Gas_Tx" "No";
BA_DEF_DEF_  "U_V363E_N_MY19_5_20_Diesel_Tx" "No";
BA_DEF_DEF_  "U_S550_MY18_Gas_Rx" "No";
BA_DEF_DEF_  "U_V408_MY18_Gas_Rx" "No";
BA_DEF_DEF_  "U_V408_MY18_Diesel_Rx" "No";
BA_DEF_DEF_  "U_P552_MY18_5_Gas_Rx" "No";
BA_DEF_DEF_  "U_P552_MY18_5_Diesel_Rx" "No";
BA_DEF_DEF_  "U_U502_MY17_Gas_Tx" "No";
BA_DEF_DEF_  "U_CD4_MY18_Diesel_Tx" "No";
BA_DEF_DEF_  "U_CD4_MY18_Gas_Tx" "No";
BA_DEF_DEF_  "U_CD4_MY18_Hev_Tx" "No";
BA_DEF_DEF_  "U_CD4_MY18_Phev_Tx" "No";
BA_DEF_DEF_  "U_S550_MY18_Gas_Tx" "No";
BA_DEF_DEF_  "U_V408_MY18_Gas_Tx" "No";
BA_DEF_DEF_  "U_V408_MY18_Diesel_Tx" "No";
BA_DEF_DEF_  "U_V36X_MY18_5_Diesel_Tx" "No";
BA_DEF_DEF_  "U_P552_MY18_5_Gas_Tx" "No";
BA_DEF_DEF_  "U_P552_MY18_5_Diesel_Tx" "No";
BA_DEF_DEF_  "U_P552_MY18_Gas_Rx" "No";
BA_DEF_DEF_  "U_U55x_MY18_Gas_Rx" "No";
BA_DEF_DEF_  "U_P552_MY18_Gas_Tx" "No";
BA_DEF_DEF_  "U_U55x_MY18_Gas_Tx" "No";
BA_DEF_DEF_  "FrameGatewayNetwork" "NONE";
BA_DEF_DEF_  "U_C489_MY17_Gas_Rx" "No";
BA_DEF_DEF_  "U_CD43_MY17_Gas_Rx" "No";
BA_DEF_DEF_  "U_B515_MCA_MY17_Diesel_Rx" "No";
BA_DEF_DEF_  "U_CD43_MY17_Gas_Tx" "No";
BA_DEF_DEF_  "U_P552_MY17_Gas_Tx" "No";
BA_DEF_DEF_  "U_CD4_MY17_Diesel_Rx" "No";
BA_DEF_DEF_  "U_CD4_MY17_Gas_Rx" "No";
BA_DEF_DEF_  "U_CD4_MY17_Hev_Rx" "No";
BA_DEF_DEF_  "U_CD4_MY17_Phev_Rx" "No";
BA_DEF_DEF_  "U_CD42_MY16_Diesel_Rx" "No";
BA_DEF_DEF_  "U_CD42_MY16_Gas_Rx" "No";
BA_DEF_DEF_  "U_CD4_MY17_Gas_Tx" "No";
BA_DEF_DEF_  "U_C489_MY16_Gas_Tx" "No";
BA_DEF_DEF_  "U_CD42_MY16_Diesel_Tx" "No";
BA_DEF_DEF_  "U_CD42_MY16_Gas_Tx" "No";
BA_DEF_DEF_  "U_CD42_MY15_Diesel_Rx" "No";
BA_DEF_DEF_  "U_U502_MY16_Gas_Rx" "No";
BA_DEF_DEF_  "U_P558_MY17_Gas_Rx" "No";
BA_DEF_DEF_  "U_P558_MY17_Diesel_Rx" "No";
BA_DEF_DEF_  "U_V36X_MY16_5_Diesel_Rx" "No";
BA_DEF_DEF_  "U_CD42_MY15_Diesel_Tx" "No";
BA_DEF_DEF_  "U_U502_MY16_Gas_Tx" "No";
BA_DEF_DEF_  "U_P558_MY17_Gas_Tx" "No";
BA_DEF_DEF_  "U_P558_MY17_Diesel_Tx" "No";
BA_DEF_DEF_  "GenSigTimeoutTime_TCM" 5000;
BA_DEF_DEF_  "GenSigTimeoutTime_ECM" 5000;
BA_DEF_DEF_  "GenSigTimeoutTime_ECM_HEV" 5000;
BA_DEF_DEF_  "GenSigTimeoutTime_PCM" 5000;
BA_DEF_DEF_  "FrameGatewayMS1" 0;
BA_DEF_DEF_  "FrameGatewayHS2" 0;
BA_DEF_DEF_  "NetworkInitialization" "No";
BA_DEF_DEF_  "FrameGatewayId" 0;
BA_DEF_DEF_  "GenMsgStartDelayTime" 0;
BA_DEF_DEF_  "GenMsgDelayTime" 20;
BA_DEF_DEF_  "GenMsgCycleTime" 0;
BA_DEF_DEF_  "GenMsgSendType" "NoMsgSendType";
BA_DEF_DEF_  "U_CD4_MY14_Phev_Tx" "No";
BA_DEF_DEF_  "U_CD4_MY14_Hev_Tx" "No";
BA_DEF_DEF_  "U_CD4_MY14_Gas_Tx" "No";
BA_DEF_DEF_  "U_CD4_MY14_Diesel_Tx" "No";
BA_DEF_DEF_  "U_CD43_MY16_Gas_Tx" "No";
BA_DEF_DEF_  "U_UP375_MY15_Diesel_Tx" "No";
BA_DEF_DEF_  "U_UP375_MY15_Gas_Tx" "No";
BA_DEF_DEF_  "U_U502_MY15_Gas_Tx" "No";
BA_DEF_DEF_  "U_C489_MY14_Gas_Tx" "No";
BA_DEF_DEF_  "U_S550_MY15_Gas_Tx" "No";
BA_DEF_DEF_  "U_P552_MY15_Gas_Tx" "No";
BA_DEF_DEF_  "U_CD42_MY14_Gas_Tx" "No";
BA_DEF_DEF_  "U_CD42_MY14_Diesel_Tx" "No";
BA_DEF_DEF_  "U_CD4_MY13_Phev_Tx" "No";
BA_DEF_DEF_  "U_CD4_MY13_Hev_Tx" "No";
BA_DEF_DEF_  "U_CD4_MY13_Gas_Tx" "No";
BA_DEF_DEF_  "U_CD4_MY13_Diesel_Tx" "No";
BA_DEF_DEF_  "U_CD4_MY14_Phev_Rx" "No";
BA_DEF_DEF_  "U_CD4_MY14_Hev_Rx" "No";
BA_DEF_DEF_  "U_CD4_MY14_Gas_Rx" "No";
BA_DEF_DEF_  "U_CD4_MY14_Diesel_Rx" "No";
BA_DEF_DEF_  "U_CD43_MY16_Gas_Rx" "No";
BA_DEF_DEF_  "U_UP375_MY15_Diesel_Rx" "No";
BA_DEF_DEF_  "U_UP375_MY15_Gas_Rx" "No";
BA_DEF_DEF_  "U_B479_MY15_Gas_Rx" "No";
BA_DEF_DEF_  "U_U502_MY15_Gas_Rx" "No";
BA_DEF_DEF_  "U_C489_MY14_Gas_Rx" "No";
BA_DEF_DEF_  "U_S550_MY15_Gas_Rx" "No";
BA_DEF_DEF_  "U_P552_MY15_Gas_Rx" "No";
BA_DEF_DEF_  "U_CD42_MY14_Gas_Rx" "No";
BA_DEF_DEF_  "U_CD42_MY14_Diesel_Rx" "No";
BA_DEF_DEF_  "U_CD4_MY13_Phev_Rx" "No";
BA_DEF_DEF_  "U_CD4_MY13_Hev_Rx" "No";
BA_DEF_DEF_  "U_CD4_MY13_Gas_Rx" "No";
BA_DEF_DEF_  "U_CD4_MY13_Diesel_Rx" "No";
BA_DEF_DEF_  "ContentDependant" "No";
BA_DEF_DEF_  "GenSigStartValue" 0;
BA_DEF_DEF_  "CrossOver_InfoCAN" "No";
BA_DEF_DEF_  "WakeupSignal" "No";
BA_DEF_DEF_  "GenSigSendType" "NoSigSendType";
BA_DEF_DEF_  "NmAsrMessage" "No";
BA_DEF_DEF_  "DiagRequest" "No";
BA_DEF_DEF_  "DiagResponse" "No";
BA_DEF_DEF_  "GenMsgILSupport" "Yes";
BA_ "NetworkInitialization" BO_ 753 1;
BA_ "GenMsgSendType" BO_ 753 5;
BA_ "GenMsgCycleTime" BO_ 753 1000;
BA_ "FrameGatewayNetwork" BO_ 818 "MS1_CAN";
BA_ "FrameGatewayId" BO_ 818 818;
BA_ "FrameGatewayMS1" BO_ 818 818;
BA_ "GenMsgSendType" BO_ 817 5;
BA_ "GenMsgCycleTime" BO_ 817 1000;
BA_ "GenMsgStartDelayTime" BO_ 817 250;
BA_ "NetworkInitialization" BO_ 817 1;
BA_ "GenMsgSendType" BO_ 1002 5;
BA_ "GenMsgCycleTime" BO_ 1002 1000;
BA_ "NetworkInitialization" BO_ 390 1;
BA_ "FrameGatewayNetwork" BO_ 390 "HS2_CAN";
BA_ "GenMsgDelayTime" BO_ 390 10;
BA_ "FrameGatewayId" BO_ 390 390;
BA_ "FrameGatewayHS2" BO_ 390 390;
BA_ "FrameGatewayNetwork" BO_ 1046 "HS2_CAN";
BA_ "FrameGatewayId" BO_ 1046 1046;
BA_ "FrameGatewayHS2" BO_ 1046 1046;
BA_ "NetworkInitialization" BO_ 1046 1;
BA_ "FrameGatewayNetwork" BO_ 125 "HS2_CAN";
BA_ "GenMsgDelayTime" BO_ 125 10;
BA_ "FrameGatewayId" BO_ 125 125;
BA_ "FrameGatewayHS2" BO_ 125 125;
BA_ "FrameGatewayNetwork" BO_ 119 "HS2_CAN";
BA_ "GenMsgDelayTime" BO_ 119 10;
BA_ "FrameGatewayId" BO_ 119 119;
BA_ "FrameGatewayHS2" BO_ 119 119;
BA_ "NetworkInitialization" BO_ 1045 1;
BA_ "FrameGatewayNetwork" BO_ 1045 "HS2_CAN";
BA_ "FrameGatewayId" BO_ 1045 1045;
BA_ "FrameGatewayHS2" BO_ 1045 1045;
BA_ "FrameGatewayNetwork" BO_ 534 "HS2_CAN";
BA_ "GenMsgDelayTime" BO_ 534 10;
BA_ "FrameGatewayId" BO_ 534 534;
BA_ "FrameGatewayHS2" BO_ 534 534;
BA_ "FrameGatewayNetwork" BO_ 531 "HS2_CAN";
BA_ "NetworkInitialization" BO_ 531 1;
BA_ "GenMsgDelayTime" BO_ 531 10;
BA_ "FrameGatewayId" BO_ 531 531;
BA_ "FrameGatewayHS2" BO_ 531 531;
BA_ "FrameGatewayNetwork" BO_ 535 "HS2_CAN";
BA_ "GenMsgDelayTime" BO_ 535 5;
BA_ "FrameGatewayId" BO_ 535 535;
BA_ "FrameGatewayHS2" BO_ 535 535;
BA_ "GenMsgILSupport" BO_ 1409 0;
BA_ "NmAsrMessage" BO_ 1409 1;
BA_ "GenMsgSendType" BO_ 1409 0;
BA_ "GenMsgCycleTime" BO_ 1409 1000;
BA_ "GenMsgILSupport" BO_ 1846 0;
BA_ "DiagRequest" BO_ 1846 1;
BA_ "GenMsgSendType" BO_ 1846 1;
BA_ "GenMsgDelayTime" BO_ 1846 0;
BA_ "GenMsgILSupport" BO_ 1854 0;
BA_ "DiagResponse" BO_ 1854 1;
BA_ "GenMsgSendType" BO_ 1854 1;
BA_ "GenMsgDelayTime" BO_ 1854 0;
BA_ "GenMsgSendType" BO_ 611 0;
BA_ "GenMsgCycleTime" BO_ 611 100;
BA_ "NetworkInitialization" BO_ 611 1;
BA_ "GenMsgSendType" BO_ 1109 5;
BA_ "GenMsgCycleTime" BO_ 1109 100;
BA_ "GenMsgSendType" BO_ 359 0;
BA_ "GenMsgCycleTime" BO_ 359 10;
BA_ "GenMsgDelayTime" BO_ 359 0;
BA_ "GenMsgSendType" BO_ 358 0;
BA_ "GenMsgCycleTime" BO_ 358 100;
BA_ "GenMsgSendType" BO_ 1078 0;
BA_ "GenMsgCycleTime" BO_ 1078 100;
BA_ "GenMsgSendType" BO_ 1084 0;
BA_ "GenMsgCycleTime" BO_ 1084 1000;
BA_ "GenMsgSendType" BO_ 1086 0;
BA_ "GenMsgCycleTime" BO_ 1086 50;
BA_ "NetworkInitialization" BO_ 1086 1;
BA_ "U_V363E_N_MY19_5_20_Diesel_Rx" SG_ 753 Em_D_Stat_UB 1;
BA_ "U_V363E_N_MY19_5_20_Gas_Rx" SG_ 753 Em_D_Stat_UB 1;
BA_ "U_P552_MY18_5_Diesel_Rx" SG_ 753 Em_D_Stat_UB 1;
BA_ "U_P552_MY18_5_Gas_Rx" SG_ 753 Em_D_Stat_UB 1;
BA_ "U_V36X_MY19_Rx" SG_ 753 Em_D_Stat_UB 1;
BA_ "U_V408_MY18_Diesel_Rx" SG_ 753 Em_D_Stat_UB 1;
BA_ "U_V408_MY18_Gas_Rx" SG_ 753 Em_D_Stat_UB 1;
BA_ "U_S550_MY18_Gas_Rx" SG_ 753 Em_D_Stat_UB 1;
BA_ "U_CD4_MY19_Phev_Rx" SG_ 753 Em_D_Stat_UB 1;
BA_ "U_CD4_MY19_Hev_Rx" SG_ 753 Em_D_Stat_UB 1;
BA_ "U_CD4_MY19_Gas_Rx" SG_ 753 Em_D_Stat_UB 1;
BA_ "U_CD4_MY19_Diesel_Rx" SG_ 753 Em_D_Stat_UB 1;
BA_ "U_U55x_MY18_Gas_Rx" SG_ 753 Em_D_Stat_UB 1;
BA_ "U_V363E_N_MY19_5_20_Diesel_Rx" SG_ 753 Em_D_Stat 1;
BA_ "U_V363E_N_MY19_5_20_Gas_Rx" SG_ 753 Em_D_Stat 1;
BA_ "U_P552_MY18_5_Diesel_Rx" SG_ 753 Em_D_Stat 1;
BA_ "U_P552_MY18_5_Gas_Rx" SG_ 753 Em_D_Stat 1;
BA_ "U_V36X_MY19_Rx" SG_ 753 Em_D_Stat 1;
BA_ "U_V408_MY18_Diesel_Rx" SG_ 753 Em_D_Stat 1;
BA_ "U_V408_MY18_Gas_Rx" SG_ 753 Em_D_Stat 1;
BA_ "U_S550_MY18_Gas_Rx" SG_ 753 Em_D_Stat 1;
BA_ "U_CD4_MY19_Phev_Rx" SG_ 753 Em_D_Stat 1;
BA_ "U_CD4_MY19_Hev_Rx" SG_ 753 Em_D_Stat 1;
BA_ "U_CD4_MY19_Gas_Rx" SG_ 753 Em_D_Stat 1;
BA_ "U_CD4_MY19_Diesel_Rx" SG_ 753 Em_D_Stat 1;
BA_ "U_U55x_MY18_Gas_Rx" SG_ 753 Em_D_Stat 1;
BA_ "GenSigSendType" SG_ 753 Em_D_Stat 3;
BA_ "GenSigSendType" SG_ 753 TrlrAidEnbl_D_Stat 3;
BA_ "GenSigSendType" SG_ 753 SeatOccDrv_B_Stat 3;
BA_ "GenSigSendType" SG_ 753 TrlrAidSetup_D_Rq 3;
BA_ "U_P552_MY15_Gas_Rx" SG_ 753 TurnLampRrOut_B_Stat_UB 1;
BA_ "U_S550_MY15_Gas_Rx" SG_ 753 TurnLampRrOut_B_Stat_UB 1;
BA_ "U_C489_MY14_Gas_Rx" SG_ 753 TurnLampRrOut_B_Stat_UB 1;
BA_ "U_CD43_MY16_Gas_Rx" SG_ 753 TurnLampRrOut_B_Stat_UB 1;
BA_ "WakeupSignal" SG_ 753 TurnLampRrOut_B_Stat 1;
BA_ "ContentDependant" SG_ 753 TurnLampRrOut_B_Stat 1;
BA_ "GenSigSendType" SG_ 753 TurnLampRrOut_B_Stat 3;
BA_ "U_P552_MY15_Gas_Rx" SG_ 753 TurnLampRrOut_B_Stat 1;
BA_ "U_S550_MY15_Gas_Rx" SG_ 753 TurnLampRrOut_B_Stat 1;
BA_ "U_C489_MY14_Gas_Rx" SG_ 753 TurnLampRrOut_B_Stat 1;
BA_ "U_CD43_MY16_Gas_Rx" SG_ 753 TurnLampRrOut_B_Stat 1;
BA_ "U_P552_MY15_Gas_Rx" SG_ 753 TurnLampRlOut_B_Stat_UB 1;
BA_ "U_S550_MY15_Gas_Rx" SG_ 753 TurnLampRlOut_B_Stat_UB 1;
BA_ "U_C489_MY14_Gas_Rx" SG_ 753 TurnLampRlOut_B_Stat_UB 1;
BA_ "U_CD43_MY16_Gas_Rx" SG_ 753 TurnLampRlOut_B_Stat_UB 1;
BA_ "WakeupSignal" SG_ 753 TurnLampRlOut_B_Stat 1;
BA_ "ContentDependant" SG_ 753 TurnLampRlOut_B_Stat 1;
BA_ "GenSigSendType" SG_ 753 TurnLampRlOut_B_Stat 3;
BA_ "U_P552_MY15_Gas_Rx" SG_ 753 TurnLampRlOut_B_Stat 1;
BA_ "U_S550_MY15_Gas_Rx" SG_ 753 TurnLampRlOut_B_Stat 1;
BA_ "U_C489_MY14_Gas_Rx" SG_ 753 TurnLampRlOut_B_Stat 1;
BA_ "U_CD43_MY16_Gas_Rx" SG_ 753 TurnLampRlOut_B_Stat 1;
BA_ "U_P552_MY15_Gas_Rx" SG_ 753 CnvtTopPos_Up_Stat_UB 1;
BA_ "U_S550_MY15_Gas_Rx" SG_ 753 CnvtTopPos_Up_Stat_UB 1;
BA_ "U_C489_MY14_Gas_Rx" SG_ 753 CnvtTopPos_Up_Stat_UB 1;
BA_ "U_CD43_MY16_Gas_Rx" SG_ 753 CnvtTopPos_Up_Stat_UB 1;
BA_ "WakeupSignal" SG_ 753 GlvBoxRleas_No_Actl 1;
BA_ "GenSigSendType" SG_ 753 GlvBoxRleas_No_Actl 3;
BA_ "U_CD42_MY14_Diesel_Rx" SG_ 753 GlvBoxRleas_No_Actl 1;
BA_ "U_CD42_MY14_Gas_Rx" SG_ 753 GlvBoxRleas_No_Actl 1;
BA_ "U_P552_MY15_Gas_Rx" SG_ 753 GlvBoxRleas_No_Actl 1;
BA_ "U_S550_MY15_Gas_Rx" SG_ 753 GlvBoxRleas_No_Actl 1;
BA_ "U_C489_MY14_Gas_Rx" SG_ 753 GlvBoxRleas_No_Actl 1;
BA_ "U_U502_MY15_Gas_Rx" SG_ 753 GlvBoxRleas_No_Actl 1;
BA_ "U_UP375_MY15_Gas_Rx" SG_ 753 GlvBoxRleas_No_Actl 1;
BA_ "U_UP375_MY15_Diesel_Rx" SG_ 753 GlvBoxRleas_No_Actl 1;
BA_ "U_CD43_MY16_Gas_Rx" SG_ 753 GlvBoxRleas_No_Actl 1;
BA_ "U_CD4_MY14_Diesel_Rx" SG_ 753 GlvBoxRleas_No_Actl 1;
BA_ "U_CD4_MY14_Gas_Rx" SG_ 753 GlvBoxRleas_No_Actl 1;
BA_ "U_CD4_MY14_Hev_Rx" SG_ 753 GlvBoxRleas_No_Actl 1;
BA_ "U_CD4_MY14_Phev_Rx" SG_ 753 GlvBoxRleas_No_Actl 1;
BA_ "U_CD42_MY14_Diesel_Rx" SG_ 753 GlvBoxRleas_No_Actl_UB 1;
BA_ "U_CD42_MY14_Gas_Rx" SG_ 753 GlvBoxRleas_No_Actl_UB 1;
BA_ "U_P552_MY15_Gas_Rx" SG_ 753 GlvBoxRleas_No_Actl_UB 1;
BA_ "U_S550_MY15_Gas_Rx" SG_ 753 GlvBoxRleas_No_Actl_UB 1;
BA_ "U_C489_MY14_Gas_Rx" SG_ 753 GlvBoxRleas_No_Actl_UB 1;
BA_ "U_U502_MY15_Gas_Rx" SG_ 753 GlvBoxRleas_No_Actl_UB 1;
BA_ "U_UP375_MY15_Gas_Rx" SG_ 753 GlvBoxRleas_No_Actl_UB 1;
BA_ "U_UP375_MY15_Diesel_Rx" SG_ 753 GlvBoxRleas_No_Actl_UB 1;
BA_ "U_CD43_MY16_Gas_Rx" SG_ 753 GlvBoxRleas_No_Actl_UB 1;
BA_ "U_CD4_MY14_Diesel_Rx" SG_ 753 GlvBoxRleas_No_Actl_UB 1;
BA_ "U_CD4_MY14_Gas_Rx" SG_ 753 GlvBoxRleas_No_Actl_UB 1;
BA_ "U_CD4_MY14_Hev_Rx" SG_ 753 GlvBoxRleas_No_Actl_UB 1;
BA_ "U_CD4_MY14_Phev_Rx" SG_ 753 GlvBoxRleas_No_Actl_UB 1;
BA_ "U_CD4_MY13_Diesel_Rx" SG_ 753 ValetMode_D_Stat_UB 1;
BA_ "U_CD4_MY13_Gas_Rx" SG_ 753 ValetMode_D_Stat_UB 1;
BA_ "U_CD4_MY13_Hev_Rx" SG_ 753 ValetMode_D_Stat_UB 1;
BA_ "U_CD4_MY13_Phev_Rx" SG_ 753 ValetMode_D_Stat_UB 1;
BA_ "U_CD42_MY14_Diesel_Rx" SG_ 753 ValetMode_D_Stat_UB 1;
BA_ "U_CD42_MY14_Gas_Rx" SG_ 753 ValetMode_D_Stat_UB 1;
BA_ "U_P552_MY15_Gas_Rx" SG_ 753 ValetMode_D_Stat_UB 1;
BA_ "U_S550_MY15_Gas_Rx" SG_ 753 ValetMode_D_Stat_UB 1;
BA_ "U_C489_MY14_Gas_Rx" SG_ 753 ValetMode_D_Stat_UB 1;
BA_ "U_U502_MY15_Gas_Rx" SG_ 753 ValetMode_D_Stat_UB 1;
BA_ "U_UP375_MY15_Gas_Rx" SG_ 753 ValetMode_D_Stat_UB 1;
BA_ "U_UP375_MY15_Diesel_Rx" SG_ 753 ValetMode_D_Stat_UB 1;
BA_ "U_CD43_MY16_Gas_Rx" SG_ 753 ValetMode_D_Stat_UB 1;
BA_ "U_CD4_MY14_Diesel_Rx" SG_ 753 ValetMode_D_Stat_UB 1;
BA_ "U_CD4_MY14_Gas_Rx" SG_ 753 ValetMode_D_Stat_UB 1;
BA_ "U_CD4_MY14_Hev_Rx" SG_ 753 ValetMode_D_Stat_UB 1;
BA_ "U_CD4_MY14_Phev_Rx" SG_ 753 ValetMode_D_Stat_UB 1;
BA_ "U_CD4_MY13_Diesel_Rx" SG_ 753 RollCodeValet_UB 1;
BA_ "U_CD4_MY13_Gas_Rx" SG_ 753 RollCodeValet_UB 1;
BA_ "U_CD4_MY13_Hev_Rx" SG_ 753 RollCodeValet_UB 1;
BA_ "U_CD4_MY13_Phev_Rx" SG_ 753 RollCodeValet_UB 1;
BA_ "U_CD42_MY14_Diesel_Rx" SG_ 753 RollCodeValet_UB 1;
BA_ "U_CD42_MY14_Gas_Rx" SG_ 753 RollCodeValet_UB 1;
BA_ "U_P552_MY15_Gas_Rx" SG_ 753 RollCodeValet_UB 1;
BA_ "U_S550_MY15_Gas_Rx" SG_ 753 RollCodeValet_UB 1;
BA_ "U_C489_MY14_Gas_Rx" SG_ 753 RollCodeValet_UB 1;
BA_ "U_U502_MY15_Gas_Rx" SG_ 753 RollCodeValet_UB 1;
BA_ "U_UP375_MY15_Gas_Rx" SG_ 753 RollCodeValet_UB 1;
BA_ "U_UP375_MY15_Diesel_Rx" SG_ 753 RollCodeValet_UB 1;
BA_ "U_CD43_MY16_Gas_Rx" SG_ 753 RollCodeValet_UB 1;
BA_ "U_CD4_MY14_Diesel_Rx" SG_ 753 RollCodeValet_UB 1;
BA_ "U_CD4_MY14_Gas_Rx" SG_ 753 RollCodeValet_UB 1;
BA_ "U_CD4_MY14_Hev_Rx" SG_ 753 RollCodeValet_UB 1;
BA_ "U_CD4_MY14_Phev_Rx" SG_ 753 RollCodeValet_UB 1;
BA_ "U_CD42_MY14_Diesel_Rx" SG_ 753 ApaMdeStat_D_RqDrv_UB 1;
BA_ "U_CD42_MY14_Gas_Rx" SG_ 753 ApaMdeStat_D_RqDrv_UB 1;
BA_ "U_P552_MY15_Gas_Rx" SG_ 753 ApaMdeStat_D_RqDrv_UB 1;
BA_ "U_C489_MY14_Gas_Rx" SG_ 753 ApaMdeStat_D_RqDrv_UB 1;
BA_ "U_U502_MY15_Gas_Rx" SG_ 753 ApaMdeStat_D_RqDrv_UB 1;
BA_ "U_UP375_MY15_Gas_Rx" SG_ 753 ApaMdeStat_D_RqDrv_UB 1;
BA_ "U_UP375_MY15_Diesel_Rx" SG_ 753 ApaMdeStat_D_RqDrv_UB 1;
BA_ "U_CD43_MY16_Gas_Rx" SG_ 753 ApaMdeStat_D_RqDrv_UB 1;
BA_ "GenSigStartValue" SG_ 753 SlMde_D_Rq 2;
BA_ "GenSigSendType" SG_ 753 SlMde_D_Rq 3;
BA_ "GenSigStartValue" SG_ 753 IsaOffst_D_Rq 14;
BA_ "GenSigSendType" SG_ 753 IsaOffst_D_Rq 3;
BA_ "CrossOver_InfoCAN" SG_ 753 ApaMdeStat_D_RqDrv 1;
BA_ "GenSigSendType" SG_ 753 ApaMdeStat_D_RqDrv 3;
BA_ "U_CD4_MY13_Diesel_Rx" SG_ 753 ApaMdeStat_D_RqDrv 1;
BA_ "U_CD4_MY13_Gas_Rx" SG_ 753 ApaMdeStat_D_RqDrv 1;
BA_ "U_CD4_MY13_Hev_Rx" SG_ 753 ApaMdeStat_D_RqDrv 1;
BA_ "U_CD4_MY13_Phev_Rx" SG_ 753 ApaMdeStat_D_RqDrv 1;
BA_ "U_CD42_MY14_Diesel_Rx" SG_ 753 ApaMdeStat_D_RqDrv 1;
BA_ "U_CD42_MY14_Gas_Rx" SG_ 753 ApaMdeStat_D_RqDrv 1;
BA_ "U_P552_MY15_Gas_Rx" SG_ 753 ApaMdeStat_D_RqDrv 1;
BA_ "U_C489_MY14_Gas_Rx" SG_ 753 ApaMdeStat_D_RqDrv 1;
BA_ "U_U502_MY15_Gas_Rx" SG_ 753 ApaMdeStat_D_RqDrv 1;
BA_ "U_UP375_MY15_Gas_Rx" SG_ 753 ApaMdeStat_D_RqDrv 1;
BA_ "U_UP375_MY15_Diesel_Rx" SG_ 753 ApaMdeStat_D_RqDrv 1;
BA_ "U_CD43_MY16_Gas_Rx" SG_ 753 ApaMdeStat_D_RqDrv 1;
BA_ "U_CD4_MY14_Diesel_Rx" SG_ 753 ApaMdeStat_D_RqDrv 1;
BA_ "U_CD4_MY14_Gas_Rx" SG_ 753 ApaMdeStat_D_RqDrv 1;
BA_ "U_CD4_MY14_Hev_Rx" SG_ 753 ApaMdeStat_D_RqDrv 1;
BA_ "U_CD4_MY14_Phev_Rx" SG_ 753 ApaMdeStat_D_RqDrv 1;
BA_ "CrossOver_InfoCAN" SG_ 753 ValetMode_D_Stat 1;
BA_ "GenSigSendType" SG_ 753 ValetMode_D_Stat 3;
BA_ "U_CD4_MY13_Diesel_Rx" SG_ 753 ValetMode_D_Stat 1;
BA_ "U_CD4_MY13_Gas_Rx" SG_ 753 ValetMode_D_Stat 1;
BA_ "U_CD4_MY13_Hev_Rx" SG_ 753 ValetMode_D_Stat 1;
BA_ "U_CD4_MY13_Phev_Rx" SG_ 753 ValetMode_D_Stat 1;
BA_ "U_CD42_MY14_Diesel_Rx" SG_ 753 ValetMode_D_Stat 1;
BA_ "U_CD42_MY14_Gas_Rx" SG_ 753 ValetMode_D_Stat 1;
BA_ "U_P552_MY15_Gas_Rx" SG_ 753 ValetMode_D_Stat 1;
BA_ "U_S550_MY15_Gas_Rx" SG_ 753 ValetMode_D_Stat 1;
BA_ "U_C489_MY14_Gas_Rx" SG_ 753 ValetMode_D_Stat 1;
BA_ "U_U502_MY15_Gas_Rx" SG_ 753 ValetMode_D_Stat 1;
BA_ "U_UP375_MY15_Gas_Rx" SG_ 753 ValetMode_D_Stat 1;
BA_ "U_UP375_MY15_Diesel_Rx" SG_ 753 ValetMode_D_Stat 1;
BA_ "U_CD43_MY16_Gas_Rx" SG_ 753 ValetMode_D_Stat 1;
BA_ "U_CD4_MY14_Diesel_Rx" SG_ 753 ValetMode_D_Stat 1;
BA_ "U_CD4_MY14_Gas_Rx" SG_ 753 ValetMode_D_Stat 1;
BA_ "U_CD4_MY14_Hev_Rx" SG_ 753 ValetMode_D_Stat 1;
BA_ "U_CD4_MY14_Phev_Rx" SG_ 753 ValetMode_D_Stat 1;
BA_ "CrossOver_InfoCAN" SG_ 753 RollCodeValet 1;
BA_ "GenSigSendType" SG_ 753 RollCodeValet 3;
BA_ "U_CD4_MY13_Diesel_Rx" SG_ 753 RollCodeValet 1;
BA_ "U_CD4_MY13_Gas_Rx" SG_ 753 RollCodeValet 1;
BA_ "U_CD4_MY13_Hev_Rx" SG_ 753 RollCodeValet 1;
BA_ "U_CD4_MY13_Phev_Rx" SG_ 753 RollCodeValet 1;
BA_ "U_CD42_MY14_Diesel_Rx" SG_ 753 RollCodeValet 1;
BA_ "U_CD42_MY14_Gas_Rx" SG_ 753 RollCodeValet 1;
BA_ "U_P552_MY15_Gas_Rx" SG_ 753 RollCodeValet 1;
BA_ "U_S550_MY15_Gas_Rx" SG_ 753 RollCodeValet 1;
BA_ "U_C489_MY14_Gas_Rx" SG_ 753 RollCodeValet 1;
BA_ "U_U502_MY15_Gas_Rx" SG_ 753 RollCodeValet 1;
BA_ "U_UP375_MY15_Gas_Rx" SG_ 753 RollCodeValet 1;
BA_ "U_UP375_MY15_Diesel_Rx" SG_ 753 RollCodeValet 1;
BA_ "U_CD43_MY16_Gas_Rx" SG_ 753 RollCodeValet 1;
BA_ "U_CD4_MY14_Diesel_Rx" SG_ 753 RollCodeValet 1;
BA_ "U_CD4_MY14_Gas_Rx" SG_ 753 RollCodeValet 1;
BA_ "U_CD4_MY14_Hev_Rx" SG_ 753 RollCodeValet 1;
BA_ "U_CD4_MY14_Phev_Rx" SG_ 753 RollCodeValet 1;
BA_ "WakeupSignal" SG_ 753 CnvtTopPos_Up_Stat 1;
BA_ "ContentDependant" SG_ 753 CnvtTopPos_Up_Stat 1;
BA_ "GenSigSendType" SG_ 753 CnvtTopPos_Up_Stat 3;
BA_ "U_P552_MY15_Gas_Rx" SG_ 753 CnvtTopPos_Up_Stat 1;
BA_ "U_S550_MY15_Gas_Rx" SG_ 753 CnvtTopPos_Up_Stat 1;
BA_ "U_C489_MY14_Gas_Rx" SG_ 753 CnvtTopPos_Up_Stat 1;
BA_ "U_CD43_MY16_Gas_Rx" SG_ 753 CnvtTopPos_Up_Stat 1;
BA_ "U_P552_MY15_Gas_Rx" SG_ 753 CnvtTopPos_Dn_Stat_UB 1;
BA_ "U_S550_MY15_Gas_Rx" SG_ 753 CnvtTopPos_Dn_Stat_UB 1;
BA_ "U_C489_MY14_Gas_Rx" SG_ 753 CnvtTopPos_Dn_Stat_UB 1;
BA_ "U_CD43_MY16_Gas_Rx" SG_ 753 CnvtTopPos_Dn_Stat_UB 1;
BA_ "WakeupSignal" SG_ 753 CnvtTopPos_Dn_Stat 1;
BA_ "ContentDependant" SG_ 753 CnvtTopPos_Dn_Stat 1;
BA_ "GenSigSendType" SG_ 753 CnvtTopPos_Dn_Stat 3;
BA_ "U_P552_MY15_Gas_Rx" SG_ 753 CnvtTopPos_Dn_Stat 1;
BA_ "U_S550_MY15_Gas_Rx" SG_ 753 CnvtTopPos_Dn_Stat 1;
BA_ "U_C489_MY14_Gas_Rx" SG_ 753 CnvtTopPos_Dn_Stat 1;
BA_ "U_CD43_MY16_Gas_Rx" SG_ 753 CnvtTopPos_Dn_Stat 1;
BA_ "WakeupSignal" SG_ 818 ChildLckPw_N_Cnt 1;
BA_ "U_CD4_MY13_Diesel_Rx" SG_ 818 ChildLckPw_N_Cnt 1;
BA_ "U_CD4_MY13_Gas_Rx" SG_ 818 ChildLckPw_N_Cnt 1;
BA_ "U_CD4_MY13_Hev_Rx" SG_ 818 ChildLckPw_N_Cnt 1;
BA_ "U_CD4_MY13_Phev_Rx" SG_ 818 ChildLckPw_N_Cnt 1;
BA_ "U_CD42_MY14_Diesel_Rx" SG_ 818 ChildLckPw_N_Cnt 1;
BA_ "U_CD42_MY14_Gas_Rx" SG_ 818 ChildLckPw_N_Cnt 1;
BA_ "U_P552_MY15_Gas_Rx" SG_ 818 ChildLckPw_N_Cnt 1;
BA_ "U_S550_MY15_Gas_Rx" SG_ 818 ChildLckPw_N_Cnt 1;
BA_ "U_C489_MY14_Gas_Rx" SG_ 818 ChildLckPw_N_Cnt 1;
BA_ "U_U502_MY15_Gas_Rx" SG_ 818 ChildLckPw_N_Cnt 1;
BA_ "U_UP375_MY15_Gas_Rx" SG_ 818 ChildLckPw_N_Cnt 1;
BA_ "U_UP375_MY15_Diesel_Rx" SG_ 818 ChildLckPw_N_Cnt 1;
BA_ "U_CD43_MY16_Gas_Rx" SG_ 818 ChildLckPw_N_Cnt 1;
BA_ "U_CD4_MY14_Diesel_Rx" SG_ 818 ChildLckPw_N_Cnt 1;
BA_ "U_CD4_MY14_Gas_Rx" SG_ 818 ChildLckPw_N_Cnt 1;
BA_ "U_CD4_MY14_Hev_Rx" SG_ 818 ChildLckPw_N_Cnt 1;
BA_ "U_CD4_MY14_Phev_Rx" SG_ 818 ChildLckPw_N_Cnt 1;
BA_ "U_CD4_MY13_Diesel_Rx" SG_ 818 RollCodeDrvDrKeyCyl 1;
BA_ "U_CD4_MY13_Gas_Rx" SG_ 818 RollCodeDrvDrKeyCyl 1;
BA_ "U_CD4_MY13_Hev_Rx" SG_ 818 RollCodeDrvDrKeyCyl 1;
BA_ "U_CD4_MY13_Phev_Rx" SG_ 818 RollCodeDrvDrKeyCyl 1;
BA_ "U_CD42_MY14_Diesel_Rx" SG_ 818 RollCodeDrvDrKeyCyl 1;
BA_ "U_CD42_MY14_Gas_Rx" SG_ 818 RollCodeDrvDrKeyCyl 1;
BA_ "U_P552_MY15_Gas_Rx" SG_ 818 RollCodeDrvDrKeyCyl 1;
BA_ "U_S550_MY15_Gas_Rx" SG_ 818 RollCodeDrvDrKeyCyl 1;
BA_ "U_C489_MY14_Gas_Rx" SG_ 818 RollCodeDrvDrKeyCyl 1;
BA_ "U_U502_MY15_Gas_Rx" SG_ 818 RollCodeDrvDrKeyCyl 1;
BA_ "U_UP375_MY15_Gas_Rx" SG_ 818 RollCodeDrvDrKeyCyl 1;
BA_ "U_UP375_MY15_Diesel_Rx" SG_ 818 RollCodeDrvDrKeyCyl 1;
BA_ "U_CD43_MY16_Gas_Rx" SG_ 818 RollCodeDrvDrKeyCyl 1;
BA_ "U_CD4_MY14_Diesel_Rx" SG_ 818 RollCodeDrvDrKeyCyl 1;
BA_ "U_CD4_MY14_Gas_Rx" SG_ 818 RollCodeDrvDrKeyCyl 1;
BA_ "U_CD4_MY14_Hev_Rx" SG_ 818 RollCodeDrvDrKeyCyl 1;
BA_ "U_CD4_MY14_Phev_Rx" SG_ 818 RollCodeDrvDrKeyCyl 1;
BA_ "WakeupSignal" SG_ 818 KeyCylSwDrvDr_D_Stat 1;
BA_ "U_CD4_MY13_Diesel_Rx" SG_ 818 KeyCylSwDrvDr_D_Stat 1;
BA_ "U_CD4_MY13_Gas_Rx" SG_ 818 KeyCylSwDrvDr_D_Stat 1;
BA_ "U_CD4_MY13_Hev_Rx" SG_ 818 KeyCylSwDrvDr_D_Stat 1;
BA_ "U_CD4_MY13_Phev_Rx" SG_ 818 KeyCylSwDrvDr_D_Stat 1;
BA_ "U_CD42_MY14_Diesel_Rx" SG_ 818 KeyCylSwDrvDr_D_Stat 1;
BA_ "U_CD42_MY14_Gas_Rx" SG_ 818 KeyCylSwDrvDr_D_Stat 1;
BA_ "U_P552_MY15_Gas_Rx" SG_ 818 KeyCylSwDrvDr_D_Stat 1;
BA_ "U_S550_MY15_Gas_Rx" SG_ 818 KeyCylSwDrvDr_D_Stat 1;
BA_ "U_C489_MY14_Gas_Rx" SG_ 818 KeyCylSwDrvDr_D_Stat 1;
BA_ "U_U502_MY15_Gas_Rx" SG_ 818 KeyCylSwDrvDr_D_Stat 1;
BA_ "U_UP375_MY15_Gas_Rx" SG_ 818 KeyCylSwDrvDr_D_Stat 1;
BA_ "U_UP375_MY15_Diesel_Rx" SG_ 818 KeyCylSwDrvDr_D_Stat 1;
BA_ "U_CD43_MY16_Gas_Rx" SG_ 818 KeyCylSwDrvDr_D_Stat 1;
BA_ "U_CD4_MY14_Diesel_Rx" SG_ 818 KeyCylSwDrvDr_D_Stat 1;
BA_ "U_CD4_MY14_Gas_Rx" SG_ 818 KeyCylSwDrvDr_D_Stat 1;
BA_ "U_CD4_MY14_Hev_Rx" SG_ 818 KeyCylSwDrvDr_D_Stat 1;
BA_ "U_CD4_MY14_Phev_Rx" SG_ 818 KeyCylSwDrvDr_D_Stat 1;
BA_ "WakeupSignal" SG_ 818 Driver_Lock_Sw_Stat 1;
BA_ "U_CD4_MY13_Diesel_Rx" SG_ 818 Driver_Lock_Sw_Stat 1;
BA_ "U_CD4_MY13_Gas_Rx" SG_ 818 Driver_Lock_Sw_Stat 1;
BA_ "U_CD4_MY13_Hev_Rx" SG_ 818 Driver_Lock_Sw_Stat 1;
BA_ "U_CD4_MY13_Phev_Rx" SG_ 818 Driver_Lock_Sw_Stat 1;
BA_ "U_CD42_MY14_Diesel_Rx" SG_ 818 Driver_Lock_Sw_Stat 1;
BA_ "U_CD42_MY14_Gas_Rx" SG_ 818 Driver_Lock_Sw_Stat 1;
BA_ "U_P552_MY15_Gas_Rx" SG_ 818 Driver_Lock_Sw_Stat 1;
BA_ "U_S550_MY15_Gas_Rx" SG_ 818 Driver_Lock_Sw_Stat 1;
BA_ "U_C489_MY14_Gas_Rx" SG_ 818 Driver_Lock_Sw_Stat 1;
BA_ "U_U502_MY15_Gas_Rx" SG_ 818 Driver_Lock_Sw_Stat 1;
BA_ "U_UP375_MY15_Gas_Rx" SG_ 818 Driver_Lock_Sw_Stat 1;
BA_ "U_UP375_MY15_Diesel_Rx" SG_ 818 Driver_Lock_Sw_Stat 1;
BA_ "U_CD43_MY16_Gas_Rx" SG_ 818 Driver_Lock_Sw_Stat 1;
BA_ "U_CD4_MY14_Diesel_Rx" SG_ 818 Driver_Lock_Sw_Stat 1;
BA_ "U_CD4_MY14_Gas_Rx" SG_ 818 Driver_Lock_Sw_Stat 1;
BA_ "U_CD4_MY14_Hev_Rx" SG_ 818 Driver_Lock_Sw_Stat 1;
BA_ "U_CD4_MY14_Phev_Rx" SG_ 818 Driver_Lock_Sw_Stat 1;
BA_ "WakeupSignal" SG_ 818 Driver_Lock_Sw_Cnt 1;
BA_ "U_CD4_MY13_Diesel_Rx" SG_ 818 Driver_Lock_Sw_Cnt 1;
BA_ "U_CD4_MY13_Gas_Rx" SG_ 818 Driver_Lock_Sw_Cnt 1;
BA_ "U_CD4_MY13_Hev_Rx" SG_ 818 Driver_Lock_Sw_Cnt 1;
BA_ "U_CD4_MY13_Phev_Rx" SG_ 818 Driver_Lock_Sw_Cnt 1;
BA_ "U_CD42_MY14_Diesel_Rx" SG_ 818 Driver_Lock_Sw_Cnt 1;
BA_ "U_CD42_MY14_Gas_Rx" SG_ 818 Driver_Lock_Sw_Cnt 1;
BA_ "U_P552_MY15_Gas_Rx" SG_ 818 Driver_Lock_Sw_Cnt 1;
BA_ "U_S550_MY15_Gas_Rx" SG_ 818 Driver_Lock_Sw_Cnt 1;
BA_ "U_C489_MY14_Gas_Rx" SG_ 818 Driver_Lock_Sw_Cnt 1;
BA_ "U_U502_MY15_Gas_Rx" SG_ 818 Driver_Lock_Sw_Cnt 1;
BA_ "U_UP375_MY15_Gas_Rx" SG_ 818 Driver_Lock_Sw_Cnt 1;
BA_ "U_UP375_MY15_Diesel_Rx" SG_ 818 Driver_Lock_Sw_Cnt 1;
BA_ "U_CD43_MY16_Gas_Rx" SG_ 818 Driver_Lock_Sw_Cnt 1;
BA_ "U_CD4_MY14_Diesel_Rx" SG_ 818 Driver_Lock_Sw_Cnt 1;
BA_ "U_CD4_MY14_Gas_Rx" SG_ 818 Driver_Lock_Sw_Cnt 1;
BA_ "U_CD4_MY14_Hev_Rx" SG_ 818 Driver_Lock_Sw_Cnt 1;
BA_ "U_CD4_MY14_Phev_Rx" SG_ 818 Driver_Lock_Sw_Cnt 1;
BA_ "WakeupSignal" SG_ 818 ChildLckPw_D_Rq 1;
BA_ "U_CD4_MY13_Diesel_Rx" SG_ 818 ChildLckPw_D_Rq 1;
BA_ "U_CD4_MY13_Gas_Rx" SG_ 818 ChildLckPw_D_Rq 1;
BA_ "U_CD4_MY13_Hev_Rx" SG_ 818 ChildLckPw_D_Rq 1;
BA_ "U_CD4_MY13_Phev_Rx" SG_ 818 ChildLckPw_D_Rq 1;
BA_ "U_CD42_MY14_Diesel_Rx" SG_ 818 ChildLckPw_D_Rq 1;
BA_ "U_CD42_MY14_Gas_Rx" SG_ 818 ChildLckPw_D_Rq 1;
BA_ "U_P552_MY15_Gas_Rx" SG_ 818 ChildLckPw_D_Rq 1;
BA_ "U_S550_MY15_Gas_Rx" SG_ 818 ChildLckPw_D_Rq 1;
BA_ "U_C489_MY14_Gas_Rx" SG_ 818 ChildLckPw_D_Rq 1;
BA_ "U_U502_MY15_Gas_Rx" SG_ 818 ChildLckPw_D_Rq 1;
BA_ "U_UP375_MY15_Gas_Rx" SG_ 818 ChildLckPw_D_Rq 1;
BA_ "U_UP375_MY15_Diesel_Rx" SG_ 818 ChildLckPw_D_Rq 1;
BA_ "U_CD43_MY16_Gas_Rx" SG_ 818 ChildLckPw_D_Rq 1;
BA_ "U_CD4_MY14_Diesel_Rx" SG_ 818 ChildLckPw_D_Rq 1;
BA_ "U_CD4_MY14_Gas_Rx" SG_ 818 ChildLckPw_D_Rq 1;
BA_ "U_CD4_MY14_Hev_Rx" SG_ 818 ChildLckPw_D_Rq 1;
BA_ "U_CD4_MY14_Phev_Rx" SG_ 818 ChildLckPw_D_Rq 1;
BA_ "WakeupSignal" SG_ 818 ChildLckFdbckRd_B_Stat 1;
BA_ "U_CD4_MY13_Diesel_Rx" SG_ 818 ChildLckFdbckRd_B_Stat 1;
BA_ "U_CD4_MY13_Gas_Rx" SG_ 818 ChildLckFdbckRd_B_Stat 1;
BA_ "U_CD4_MY13_Hev_Rx" SG_ 818 ChildLckFdbckRd_B_Stat 1;
BA_ "U_CD4_MY13_Phev_Rx" SG_ 818 ChildLckFdbckRd_B_Stat 1;
BA_ "U_CD42_MY14_Diesel_Rx" SG_ 818 ChildLckFdbckRd_B_Stat 1;
BA_ "U_CD42_MY14_Gas_Rx" SG_ 818 ChildLckFdbckRd_B_Stat 1;
BA_ "U_P552_MY15_Gas_Rx" SG_ 818 ChildLckFdbckRd_B_Stat 1;
BA_ "U_S550_MY15_Gas_Rx" SG_ 818 ChildLckFdbckRd_B_Stat 1;
BA_ "U_C489_MY14_Gas_Rx" SG_ 818 ChildLckFdbckRd_B_Stat 1;
BA_ "U_U502_MY15_Gas_Rx" SG_ 818 ChildLckFdbckRd_B_Stat 1;
BA_ "U_UP375_MY15_Gas_Rx" SG_ 818 ChildLckFdbckRd_B_Stat 1;
BA_ "U_UP375_MY15_Diesel_Rx" SG_ 818 ChildLckFdbckRd_B_Stat 1;
BA_ "U_CD43_MY16_Gas_Rx" SG_ 818 ChildLckFdbckRd_B_Stat 1;
BA_ "U_CD4_MY14_Diesel_Rx" SG_ 818 ChildLckFdbckRd_B_Stat 1;
BA_ "U_CD4_MY14_Gas_Rx" SG_ 818 ChildLckFdbckRd_B_Stat 1;
BA_ "U_CD4_MY14_Hev_Rx" SG_ 818 ChildLckFdbckRd_B_Stat 1;
BA_ "U_CD4_MY14_Phev_Rx" SG_ 818 ChildLckFdbckRd_B_Stat 1;
BA_ "U_V36X_MY18_5_Hev_Tx" SG_ 817 ChildLckMde_B_Stat 1;
BA_ "U_V36X_MY18_5_Gas_Tx" SG_ 817 ChildLckMde_B_Stat 1;
BA_ "U_V363E_N_MY19_5_20_Diesel_Tx" SG_ 817 ChildLckMde_B_Stat 1;
BA_ "U_V363E_N_MY19_5_20_Gas_Tx" SG_ 817 ChildLckMde_B_Stat 1;
BA_ "U_V36X_MY19_5_Diesel_Tx" SG_ 817 ChildLckMde_B_Stat 1;
BA_ "U_P552_MY18_5_Diesel_Tx" SG_ 817 ChildLckMde_B_Stat 1;
BA_ "U_P552_MY18_5_Gas_Tx" SG_ 817 ChildLckMde_B_Stat 1;
BA_ "U_V36X_MY18_5_Diesel_Tx" SG_ 817 ChildLckMde_B_Stat 1;
BA_ "U_V408_MY18_Diesel_Tx" SG_ 817 ChildLckMde_B_Stat 1;
BA_ "U_V408_MY18_Gas_Tx" SG_ 817 ChildLckMde_B_Stat 1;
BA_ "U_S550_MY18_Gas_Tx" SG_ 817 ChildLckMde_B_Stat 1;
BA_ "U_CD4_MY18_Phev_Tx" SG_ 817 ChildLckMde_B_Stat 1;
BA_ "U_CD4_MY18_Hev_Tx" SG_ 817 ChildLckMde_B_Stat 1;
BA_ "U_CD4_MY18_Gas_Tx" SG_ 817 ChildLckMde_B_Stat 1;
BA_ "U_CD4_MY18_Diesel_Tx" SG_ 817 ChildLckMde_B_Stat 1;
BA_ "U_U502_MY17_Gas_Tx" SG_ 817 ChildLckMde_B_Stat 1;
BA_ "U_U55x_MY18_Gas_Tx" SG_ 817 ChildLckMde_B_Stat 1;
BA_ "U_P552_MY18_Gas_Tx" SG_ 817 ChildLckMde_B_Stat 1;
BA_ "U_P552_MY17_Gas_Tx" SG_ 817 ChildLckMde_B_Stat 1;
BA_ "U_CD43_MY17_Gas_Tx" SG_ 817 ChildLckMde_B_Stat 1;
BA_ "U_P558_MY17_Diesel_Tx" SG_ 817 ChildLckMde_B_Stat 1;
BA_ "U_P558_MY17_Gas_Tx" SG_ 817 ChildLckMde_B_Stat 1;
BA_ "WakeupSignal" SG_ 817 ChildLckMde_B_Stat 1;
BA_ "GenSigSendType" SG_ 817 ChildLckMde_B_Stat 3;
BA_ "GenSigSendType" SG_ 817 VehLckInd_D_Rq 3;
BA_ "U_P552_MY15_Gas_Tx" SG_ 817 VehLckInd_D_Rq 1;
BA_ "U_S550_MY15_Gas_Tx" SG_ 817 VehLckInd_D_Rq 1;
BA_ "U_C489_MY14_Gas_Tx" SG_ 817 VehLckInd_D_Rq 1;
BA_ "U_CD43_MY16_Gas_Tx" SG_ 817 VehLckInd_D_Rq 1;
BA_ "U_CD4_MY14_Diesel_Tx" SG_ 817 VehLckInd_D_Rq 1;
BA_ "U_CD4_MY14_Gas_Tx" SG_ 817 VehLckInd_D_Rq 1;
BA_ "U_CD4_MY14_Hev_Tx" SG_ 817 VehLckInd_D_Rq 1;
BA_ "U_CD4_MY14_Phev_Tx" SG_ 817 VehLckInd_D_Rq 1;
BA_ "WakeupSignal" SG_ 817 DrTgateOpen_B_Rq 1;
BA_ "GenSigSendType" SG_ 817 DrTgateOpen_B_Rq 3;
BA_ "U_CD4_MY13_Diesel_Tx" SG_ 817 DrTgateOpen_B_Rq 1;
BA_ "U_CD4_MY13_Gas_Tx" SG_ 817 DrTgateOpen_B_Rq 1;
BA_ "U_CD4_MY13_Hev_Tx" SG_ 817 DrTgateOpen_B_Rq 1;
BA_ "U_CD4_MY13_Phev_Tx" SG_ 817 DrTgateOpen_B_Rq 1;
BA_ "U_CD42_MY14_Diesel_Tx" SG_ 817 DrTgateOpen_B_Rq 1;
BA_ "U_CD42_MY14_Gas_Tx" SG_ 817 DrTgateOpen_B_Rq 1;
BA_ "U_P552_MY15_Gas_Tx" SG_ 817 DrTgateOpen_B_Rq 1;
BA_ "U_S550_MY15_Gas_Tx" SG_ 817 DrTgateOpen_B_Rq 1;
BA_ "U_C489_MY14_Gas_Tx" SG_ 817 DrTgateOpen_B_Rq 1;
BA_ "U_U502_MY15_Gas_Tx" SG_ 817 DrTgateOpen_B_Rq 1;
BA_ "U_UP375_MY15_Gas_Tx" SG_ 817 DrTgateOpen_B_Rq 1;
BA_ "U_UP375_MY15_Diesel_Tx" SG_ 817 DrTgateOpen_B_Rq 1;
BA_ "U_CD43_MY16_Gas_Tx" SG_ 817 DrTgateOpen_B_Rq 1;
BA_ "U_CD4_MY14_Diesel_Tx" SG_ 817 DrTgateOpen_B_Rq 1;
BA_ "U_CD4_MY14_Gas_Tx" SG_ 817 DrTgateOpen_B_Rq 1;
BA_ "U_CD4_MY14_Hev_Tx" SG_ 817 DrTgateOpen_B_Rq 1;
BA_ "U_CD4_MY14_Phev_Tx" SG_ 817 DrTgateOpen_B_Rq 1;
BA_ "WakeupSignal" SG_ 817 DrTgateExtSwMde_B_Stat 1;
BA_ "GenSigSendType" SG_ 817 DrTgateExtSwMde_B_Stat 3;
BA_ "U_CD4_MY13_Diesel_Rx" SG_ 817 DrTgateExtSwMde_B_Stat 1;
BA_ "U_CD4_MY13_Gas_Rx" SG_ 817 DrTgateExtSwMde_B_Stat 1;
BA_ "U_CD4_MY13_Hev_Rx" SG_ 817 DrTgateExtSwMde_B_Stat 1;
BA_ "U_CD4_MY13_Phev_Rx" SG_ 817 DrTgateExtSwMde_B_Stat 1;
BA_ "U_CD42_MY14_Diesel_Rx" SG_ 817 DrTgateExtSwMde_B_Stat 1;
BA_ "U_CD42_MY14_Gas_Rx" SG_ 817 DrTgateExtSwMde_B_Stat 1;
BA_ "U_P552_MY15_Gas_Rx" SG_ 817 DrTgateExtSwMde_B_Stat 1;
BA_ "U_S550_MY15_Gas_Rx" SG_ 817 DrTgateExtSwMde_B_Stat 1;
BA_ "U_C489_MY14_Gas_Rx" SG_ 817 DrTgateExtSwMde_B_Stat 1;
BA_ "U_U502_MY15_Gas_Rx" SG_ 817 DrTgateExtSwMde_B_Stat 1;
BA_ "U_B479_MY15_Gas_Rx" SG_ 817 DrTgateExtSwMde_B_Stat 1;
BA_ "U_UP375_MY15_Gas_Rx" SG_ 817 DrTgateExtSwMde_B_Stat 1;
BA_ "U_UP375_MY15_Diesel_Rx" SG_ 817 DrTgateExtSwMde_B_Stat 1;
BA_ "U_CD4_MY13_Diesel_Tx" SG_ 817 DrTgateExtSwMde_B_Stat 1;
BA_ "U_CD4_MY13_Gas_Tx" SG_ 817 DrTgateExtSwMde_B_Stat 1;
BA_ "U_CD4_MY13_Hev_Tx" SG_ 817 DrTgateExtSwMde_B_Stat 1;
BA_ "U_CD4_MY13_Phev_Tx" SG_ 817 DrTgateExtSwMde_B_Stat 1;
BA_ "U_CD42_MY14_Diesel_Tx" SG_ 817 DrTgateExtSwMde_B_Stat 1;
BA_ "U_CD42_MY14_Gas_Tx" SG_ 817 DrTgateExtSwMde_B_Stat 1;
BA_ "U_P552_MY15_Gas_Tx" SG_ 817 DrTgateExtSwMde_B_Stat 1;
BA_ "U_S550_MY15_Gas_Tx" SG_ 817 DrTgateExtSwMde_B_Stat 1;
BA_ "U_C489_MY14_Gas_Tx" SG_ 817 DrTgateExtSwMde_B_Stat 1;
BA_ "U_U502_MY15_Gas_Tx" SG_ 817 DrTgateExtSwMde_B_Stat 1;
BA_ "U_UP375_MY15_Gas_Tx" SG_ 817 DrTgateExtSwMde_B_Stat 1;
BA_ "U_UP375_MY15_Diesel_Tx" SG_ 817 DrTgateExtSwMde_B_Stat 1;
BA_ "U_CD43_MY16_Gas_Tx" SG_ 817 DrTgateExtSwMde_B_Stat 1;
BA_ "U_CD4_MY14_Diesel_Tx" SG_ 817 DrTgateExtSwMde_B_Stat 1;
BA_ "U_CD4_MY14_Gas_Tx" SG_ 817 DrTgateExtSwMde_B_Stat 1;
BA_ "U_CD4_MY14_Hev_Tx" SG_ 817 DrTgateExtSwMde_B_Stat 1;
BA_ "U_CD4_MY14_Phev_Tx" SG_ 817 DrTgateExtSwMde_B_Stat 1;
BA_ "WakeupSignal" SG_ 817 Remote_Device_Feedback 1;
BA_ "GenSigSendType" SG_ 817 Remote_Device_Feedback 3;
BA_ "U_CD4_MY13_Diesel_Tx" SG_ 817 Remote_Device_Feedback 1;
BA_ "U_CD4_MY13_Gas_Tx" SG_ 817 Remote_Device_Feedback 1;
BA_ "U_CD4_MY13_Hev_Tx" SG_ 817 Remote_Device_Feedback 1;
BA_ "U_CD4_MY13_Phev_Tx" SG_ 817 Remote_Device_Feedback 1;
BA_ "U_CD42_MY14_Diesel_Tx" SG_ 817 Remote_Device_Feedback 1;
BA_ "U_CD42_MY14_Gas_Tx" SG_ 817 Remote_Device_Feedback 1;
BA_ "U_P552_MY15_Gas_Tx" SG_ 817 Remote_Device_Feedback 1;
BA_ "U_S550_MY15_Gas_Tx" SG_ 817 Remote_Device_Feedback 1;
BA_ "U_C489_MY14_Gas_Tx" SG_ 817 Remote_Device_Feedback 1;
BA_ "U_U502_MY15_Gas_Tx" SG_ 817 Remote_Device_Feedback 1;
BA_ "U_UP375_MY15_Gas_Tx" SG_ 817 Remote_Device_Feedback 1;
BA_ "U_UP375_MY15_Diesel_Tx" SG_ 817 Remote_Device_Feedback 1;
BA_ "U_CD43_MY16_Gas_Tx" SG_ 817 Remote_Device_Feedback 1;
BA_ "U_CD4_MY14_Diesel_Tx" SG_ 817 Remote_Device_Feedback 1;
BA_ "U_CD4_MY14_Gas_Tx" SG_ 817 Remote_Device_Feedback 1;
BA_ "U_CD4_MY14_Hev_Tx" SG_ 817 Remote_Device_Feedback 1;
BA_ "U_CD4_MY14_Phev_Tx" SG_ 817 Remote_Device_Feedback 1;
BA_ "WakeupSignal" SG_ 817 Veh_Lock_Requestor 1;
BA_ "GenSigSendType" SG_ 817 Veh_Lock_Requestor 3;
BA_ "U_CD4_MY13_Diesel_Rx" SG_ 817 Veh_Lock_Requestor 1;
BA_ "U_CD4_MY13_Gas_Rx" SG_ 817 Veh_Lock_Requestor 1;
BA_ "U_CD4_MY13_Hev_Rx" SG_ 817 Veh_Lock_Requestor 1;
BA_ "U_CD4_MY13_Phev_Rx" SG_ 817 Veh_Lock_Requestor 1;
BA_ "U_CD42_MY14_Diesel_Rx" SG_ 817 Veh_Lock_Requestor 1;
BA_ "U_CD42_MY14_Gas_Rx" SG_ 817 Veh_Lock_Requestor 1;
BA_ "U_P552_MY15_Gas_Rx" SG_ 817 Veh_Lock_Requestor 1;
BA_ "U_S550_MY15_Gas_Rx" SG_ 817 Veh_Lock_Requestor 1;
BA_ "U_C489_MY14_Gas_Rx" SG_ 817 Veh_Lock_Requestor 1;
BA_ "U_U502_MY15_Gas_Rx" SG_ 817 Veh_Lock_Requestor 1;
BA_ "U_B479_MY15_Gas_Rx" SG_ 817 Veh_Lock_Requestor 1;
BA_ "U_UP375_MY15_Gas_Rx" SG_ 817 Veh_Lock_Requestor 1;
BA_ "U_UP375_MY15_Diesel_Rx" SG_ 817 Veh_Lock_Requestor 1;
BA_ "U_CD4_MY13_Diesel_Tx" SG_ 817 Veh_Lock_Requestor 1;
BA_ "U_CD4_MY13_Gas_Tx" SG_ 817 Veh_Lock_Requestor 1;
BA_ "U_CD4_MY13_Hev_Tx" SG_ 817 Veh_Lock_Requestor 1;
BA_ "U_CD4_MY13_Phev_Tx" SG_ 817 Veh_Lock_Requestor 1;
BA_ "U_CD42_MY14_Diesel_Tx" SG_ 817 Veh_Lock_Requestor 1;
BA_ "U_CD42_MY14_Gas_Tx" SG_ 817 Veh_Lock_Requestor 1;
BA_ "U_P552_MY15_Gas_Tx" SG_ 817 Veh_Lock_Requestor 1;
BA_ "U_S550_MY15_Gas_Tx" SG_ 817 Veh_Lock_Requestor 1;
BA_ "U_C489_MY14_Gas_Tx" SG_ 817 Veh_Lock_Requestor 1;
BA_ "U_U502_MY15_Gas_Tx" SG_ 817 Veh_Lock_Requestor 1;
BA_ "U_UP375_MY15_Gas_Tx" SG_ 817 Veh_Lock_Requestor 1;
BA_ "U_UP375_MY15_Diesel_Tx" SG_ 817 Veh_Lock_Requestor 1;
BA_ "U_CD43_MY16_Gas_Tx" SG_ 817 Veh_Lock_Requestor 1;
BA_ "U_CD4_MY14_Diesel_Tx" SG_ 817 Veh_Lock_Requestor 1;
BA_ "U_CD4_MY14_Gas_Tx" SG_ 817 Veh_Lock_Requestor 1;
BA_ "U_CD4_MY14_Hev_Tx" SG_ 817 Veh_Lock_Requestor 1;
BA_ "U_CD4_MY14_Phev_Tx" SG_ 817 Veh_Lock_Requestor 1;
BA_ "WakeupSignal" SG_ 817 R_Pwr_Sliding_Dr_Rqst 1;
BA_ "GenSigSendType" SG_ 817 R_Pwr_Sliding_Dr_Rqst 3;
BA_ "U_CD4_MY13_Diesel_Tx" SG_ 817 R_Pwr_Sliding_Dr_Rqst 1;
BA_ "U_CD4_MY13_Gas_Tx" SG_ 817 R_Pwr_Sliding_Dr_Rqst 1;
BA_ "U_CD4_MY13_Hev_Tx" SG_ 817 R_Pwr_Sliding_Dr_Rqst 1;
BA_ "U_CD4_MY13_Phev_Tx" SG_ 817 R_Pwr_Sliding_Dr_Rqst 1;
BA_ "U_CD42_MY14_Diesel_Tx" SG_ 817 R_Pwr_Sliding_Dr_Rqst 1;
BA_ "U_CD42_MY14_Gas_Tx" SG_ 817 R_Pwr_Sliding_Dr_Rqst 1;
BA_ "U_P552_MY15_Gas_Tx" SG_ 817 R_Pwr_Sliding_Dr_Rqst 1;
BA_ "U_S550_MY15_Gas_Tx" SG_ 817 R_Pwr_Sliding_Dr_Rqst 1;
BA_ "U_C489_MY14_Gas_Tx" SG_ 817 R_Pwr_Sliding_Dr_Rqst 1;
BA_ "U_U502_MY15_Gas_Tx" SG_ 817 R_Pwr_Sliding_Dr_Rqst 1;
BA_ "U_UP375_MY15_Gas_Tx" SG_ 817 R_Pwr_Sliding_Dr_Rqst 1;
BA_ "U_UP375_MY15_Diesel_Tx" SG_ 817 R_Pwr_Sliding_Dr_Rqst 1;
BA_ "U_CD43_MY16_Gas_Tx" SG_ 817 R_Pwr_Sliding_Dr_Rqst 1;
BA_ "U_CD4_MY14_Diesel_Tx" SG_ 817 R_Pwr_Sliding_Dr_Rqst 1;
BA_ "U_CD4_MY14_Gas_Tx" SG_ 817 R_Pwr_Sliding_Dr_Rqst 1;
BA_ "U_CD4_MY14_Hev_Tx" SG_ 817 R_Pwr_Sliding_Dr_Rqst 1;
BA_ "U_CD4_MY14_Phev_Tx" SG_ 817 R_Pwr_Sliding_Dr_Rqst 1;
BA_ "WakeupSignal" SG_ 817 Power_Liftgate_Rqst 1;
BA_ "GenSigSendType" SG_ 817 Power_Liftgate_Rqst 3;
BA_ "U_CD4_MY13_Diesel_Rx" SG_ 817 Power_Liftgate_Rqst 1;
BA_ "U_CD4_MY13_Gas_Rx" SG_ 817 Power_Liftgate_Rqst 1;
BA_ "U_CD4_MY13_Hev_Rx" SG_ 817 Power_Liftgate_Rqst 1;
BA_ "U_CD4_MY13_Phev_Rx" SG_ 817 Power_Liftgate_Rqst 1;
BA_ "U_CD42_MY14_Diesel_Rx" SG_ 817 Power_Liftgate_Rqst 1;
BA_ "U_CD42_MY14_Gas_Rx" SG_ 817 Power_Liftgate_Rqst 1;
BA_ "U_P552_MY15_Gas_Rx" SG_ 817 Power_Liftgate_Rqst 1;
BA_ "U_S550_MY15_Gas_Rx" SG_ 817 Power_Liftgate_Rqst 1;
BA_ "U_C489_MY14_Gas_Rx" SG_ 817 Power_Liftgate_Rqst 1;
BA_ "U_U502_MY15_Gas_Rx" SG_ 817 Power_Liftgate_Rqst 1;
BA_ "U_B479_MY15_Gas_Rx" SG_ 817 Power_Liftgate_Rqst 1;
BA_ "U_UP375_MY15_Gas_Rx" SG_ 817 Power_Liftgate_Rqst 1;
BA_ "U_UP375_MY15_Diesel_Rx" SG_ 817 Power_Liftgate_Rqst 1;
BA_ "U_CD4_MY13_Diesel_Tx" SG_ 817 Power_Liftgate_Rqst 1;
BA_ "U_CD4_MY13_Gas_Tx" SG_ 817 Power_Liftgate_Rqst 1;
BA_ "U_CD4_MY13_Hev_Tx" SG_ 817 Power_Liftgate_Rqst 1;
BA_ "U_CD4_MY13_Phev_Tx" SG_ 817 Power_Liftgate_Rqst 1;
BA_ "U_CD42_MY14_Diesel_Tx" SG_ 817 Power_Liftgate_Rqst 1;
BA_ "U_CD42_MY14_Gas_Tx" SG_ 817 Power_Liftgate_Rqst 1;
BA_ "U_P552_MY15_Gas_Tx" SG_ 817 Power_Liftgate_Rqst 1;
BA_ "U_S550_MY15_Gas_Tx" SG_ 817 Power_Liftgate_Rqst 1;
BA_ "U_C489_MY14_Gas_Tx" SG_ 817 Power_Liftgate_Rqst 1;
BA_ "U_U502_MY15_Gas_Tx" SG_ 817 Power_Liftgate_Rqst 1;
BA_ "U_UP375_MY15_Gas_Tx" SG_ 817 Power_Liftgate_Rqst 1;
BA_ "U_UP375_MY15_Diesel_Tx" SG_ 817 Power_Liftgate_Rqst 1;
BA_ "U_CD43_MY16_Gas_Tx" SG_ 817 Power_Liftgate_Rqst 1;
BA_ "U_CD4_MY14_Diesel_Tx" SG_ 817 Power_Liftgate_Rqst 1;
BA_ "U_CD4_MY14_Gas_Tx" SG_ 817 Power_Liftgate_Rqst 1;
BA_ "U_CD4_MY14_Hev_Tx" SG_ 817 Power_Liftgate_Rqst 1;
BA_ "U_CD4_MY14_Phev_Tx" SG_ 817 Power_Liftgate_Rqst 1;
BA_ "WakeupSignal" SG_ 817 Veh_Lock_EvNum 1;
BA_ "GenSigSendType" SG_ 817 Veh_Lock_EvNum 3;
BA_ "U_CD4_MY13_Diesel_Tx" SG_ 817 Veh_Lock_EvNum 1;
BA_ "U_CD4_MY13_Gas_Tx" SG_ 817 Veh_Lock_EvNum 1;
BA_ "U_CD4_MY13_Hev_Tx" SG_ 817 Veh_Lock_EvNum 1;
BA_ "U_CD4_MY13_Phev_Tx" SG_ 817 Veh_Lock_EvNum 1;
BA_ "U_CD42_MY14_Diesel_Tx" SG_ 817 Veh_Lock_EvNum 1;
BA_ "U_CD42_MY14_Gas_Tx" SG_ 817 Veh_Lock_EvNum 1;
BA_ "U_P552_MY15_Gas_Tx" SG_ 817 Veh_Lock_EvNum 1;
BA_ "U_S550_MY15_Gas_Tx" SG_ 817 Veh_Lock_EvNum 1;
BA_ "U_C489_MY14_Gas_Tx" SG_ 817 Veh_Lock_EvNum 1;
BA_ "U_U502_MY15_Gas_Tx" SG_ 817 Veh_Lock_EvNum 1;
BA_ "U_UP375_MY15_Gas_Tx" SG_ 817 Veh_Lock_EvNum 1;
BA_ "U_UP375_MY15_Diesel_Tx" SG_ 817 Veh_Lock_EvNum 1;
BA_ "U_CD43_MY16_Gas_Tx" SG_ 817 Veh_Lock_EvNum 1;
BA_ "U_CD4_MY14_Diesel_Tx" SG_ 817 Veh_Lock_EvNum 1;
BA_ "U_CD4_MY14_Gas_Tx" SG_ 817 Veh_Lock_EvNum 1;
BA_ "U_CD4_MY14_Hev_Tx" SG_ 817 Veh_Lock_EvNum 1;
BA_ "U_CD4_MY14_Phev_Tx" SG_ 817 Veh_Lock_EvNum 1;
BA_ "WakeupSignal" SG_ 817 Power_Decklid_Rqst 1;
BA_ "GenSigSendType" SG_ 817 Power_Decklid_Rqst 3;
BA_ "U_CD4_MY13_Diesel_Rx" SG_ 817 Power_Decklid_Rqst 1;
BA_ "U_CD4_MY13_Gas_Rx" SG_ 817 Power_Decklid_Rqst 1;
BA_ "U_CD4_MY13_Hev_Rx" SG_ 817 Power_Decklid_Rqst 1;
BA_ "U_CD4_MY13_Phev_Rx" SG_ 817 Power_Decklid_Rqst 1;
BA_ "U_CD42_MY14_Diesel_Rx" SG_ 817 Power_Decklid_Rqst 1;
BA_ "U_CD42_MY14_Gas_Rx" SG_ 817 Power_Decklid_Rqst 1;
BA_ "U_P552_MY15_Gas_Rx" SG_ 817 Power_Decklid_Rqst 1;
BA_ "U_S550_MY15_Gas_Rx" SG_ 817 Power_Decklid_Rqst 1;
BA_ "U_C489_MY14_Gas_Rx" SG_ 817 Power_Decklid_Rqst 1;
BA_ "U_U502_MY15_Gas_Rx" SG_ 817 Power_Decklid_Rqst 1;
BA_ "U_B479_MY15_Gas_Rx" SG_ 817 Power_Decklid_Rqst 1;
BA_ "U_UP375_MY15_Gas_Rx" SG_ 817 Power_Decklid_Rqst 1;
BA_ "U_UP375_MY15_Diesel_Rx" SG_ 817 Power_Decklid_Rqst 1;
BA_ "U_CD4_MY13_Diesel_Tx" SG_ 817 Power_Decklid_Rqst 1;
BA_ "U_CD4_MY13_Gas_Tx" SG_ 817 Power_Decklid_Rqst 1;
BA_ "U_CD4_MY13_Hev_Tx" SG_ 817 Power_Decklid_Rqst 1;
BA_ "U_CD4_MY13_Phev_Tx" SG_ 817 Power_Decklid_Rqst 1;
BA_ "U_CD42_MY14_Diesel_Tx" SG_ 817 Power_Decklid_Rqst 1;
BA_ "U_CD42_MY14_Gas_Tx" SG_ 817 Power_Decklid_Rqst 1;
BA_ "U_P552_MY15_Gas_Tx" SG_ 817 Power_Decklid_Rqst 1;
BA_ "U_S550_MY15_Gas_Tx" SG_ 817 Power_Decklid_Rqst 1;
BA_ "U_C489_MY14_Gas_Tx" SG_ 817 Power_Decklid_Rqst 1;
BA_ "U_U502_MY15_Gas_Tx" SG_ 817 Power_Decklid_Rqst 1;
BA_ "U_UP375_MY15_Gas_Tx" SG_ 817 Power_Decklid_Rqst 1;
BA_ "U_UP375_MY15_Diesel_Tx" SG_ 817 Power_Decklid_Rqst 1;
BA_ "U_CD43_MY16_Gas_Tx" SG_ 817 Power_Decklid_Rqst 1;
BA_ "U_CD4_MY14_Diesel_Tx" SG_ 817 Power_Decklid_Rqst 1;
BA_ "U_CD4_MY14_Gas_Tx" SG_ 817 Power_Decklid_Rqst 1;
BA_ "U_CD4_MY14_Hev_Tx" SG_ 817 Power_Decklid_Rqst 1;
BA_ "U_CD4_MY14_Phev_Tx" SG_ 817 Power_Decklid_Rqst 1;
BA_ "WakeupSignal" SG_ 817 L_Pwr_Sliding_Dr_Rqst 1;
BA_ "GenSigSendType" SG_ 817 L_Pwr_Sliding_Dr_Rqst 3;
BA_ "U_CD4_MY13_Diesel_Tx" SG_ 817 L_Pwr_Sliding_Dr_Rqst 1;
BA_ "U_CD4_MY13_Gas_Tx" SG_ 817 L_Pwr_Sliding_Dr_Rqst 1;
BA_ "U_CD4_MY13_Hev_Tx" SG_ 817 L_Pwr_Sliding_Dr_Rqst 1;
BA_ "U_CD4_MY13_Phev_Tx" SG_ 817 L_Pwr_Sliding_Dr_Rqst 1;
BA_ "U_CD42_MY14_Diesel_Tx" SG_ 817 L_Pwr_Sliding_Dr_Rqst 1;
BA_ "U_CD42_MY14_Gas_Tx" SG_ 817 L_Pwr_Sliding_Dr_Rqst 1;
BA_ "U_P552_MY15_Gas_Tx" SG_ 817 L_Pwr_Sliding_Dr_Rqst 1;
BA_ "U_S550_MY15_Gas_Tx" SG_ 817 L_Pwr_Sliding_Dr_Rqst 1;
BA_ "U_C489_MY14_Gas_Tx" SG_ 817 L_Pwr_Sliding_Dr_Rqst 1;
BA_ "U_U502_MY15_Gas_Tx" SG_ 817 L_Pwr_Sliding_Dr_Rqst 1;
BA_ "U_UP375_MY15_Gas_Tx" SG_ 817 L_Pwr_Sliding_Dr_Rqst 1;
BA_ "U_UP375_MY15_Diesel_Tx" SG_ 817 L_Pwr_Sliding_Dr_Rqst 1;
BA_ "U_CD43_MY16_Gas_Tx" SG_ 817 L_Pwr_Sliding_Dr_Rqst 1;
BA_ "U_CD4_MY14_Diesel_Tx" SG_ 817 L_Pwr_Sliding_Dr_Rqst 1;
BA_ "U_CD4_MY14_Gas_Tx" SG_ 817 L_Pwr_Sliding_Dr_Rqst 1;
BA_ "U_CD4_MY14_Hev_Tx" SG_ 817 L_Pwr_Sliding_Dr_Rqst 1;
BA_ "U_CD4_MY14_Phev_Tx" SG_ 817 L_Pwr_Sliding_Dr_Rqst 1;
BA_ "WakeupSignal" SG_ 817 Keyfob_Pad_Msg_Count 1;
BA_ "GenSigSendType" SG_ 817 Keyfob_Pad_Msg_Count 3;
BA_ "U_CD4_MY13_Diesel_Tx" SG_ 817 Keyfob_Pad_Msg_Count 1;
BA_ "U_CD4_MY13_Gas_Tx" SG_ 817 Keyfob_Pad_Msg_Count 1;
BA_ "U_CD4_MY13_Hev_Tx" SG_ 817 Keyfob_Pad_Msg_Count 1;
BA_ "U_CD4_MY13_Phev_Tx" SG_ 817 Keyfob_Pad_Msg_Count 1;
BA_ "U_CD42_MY14_Diesel_Tx" SG_ 817 Keyfob_Pad_Msg_Count 1;
BA_ "U_CD42_MY14_Gas_Tx" SG_ 817 Keyfob_Pad_Msg_Count 1;
BA_ "U_P552_MY15_Gas_Tx" SG_ 817 Keyfob_Pad_Msg_Count 1;
BA_ "U_S550_MY15_Gas_Tx" SG_ 817 Keyfob_Pad_Msg_Count 1;
BA_ "U_C489_MY14_Gas_Tx" SG_ 817 Keyfob_Pad_Msg_Count 1;
BA_ "U_U502_MY15_Gas_Tx" SG_ 817 Keyfob_Pad_Msg_Count 1;
BA_ "U_UP375_MY15_Gas_Tx" SG_ 817 Keyfob_Pad_Msg_Count 1;
BA_ "U_UP375_MY15_Diesel_Tx" SG_ 817 Keyfob_Pad_Msg_Count 1;
BA_ "U_CD43_MY16_Gas_Tx" SG_ 817 Keyfob_Pad_Msg_Count 1;
BA_ "U_CD4_MY14_Diesel_Tx" SG_ 817 Keyfob_Pad_Msg_Count 1;
BA_ "U_CD4_MY14_Gas_Tx" SG_ 817 Keyfob_Pad_Msg_Count 1;
BA_ "U_CD4_MY14_Hev_Tx" SG_ 817 Keyfob_Pad_Msg_Count 1;
BA_ "U_CD4_MY14_Phev_Tx" SG_ 817 Keyfob_Pad_Msg_Count 1;
BA_ "GenSigSendType" SG_ 817 Veh_Lock_Sub_Id 3;
BA_ "U_CD4_MY13_Diesel_Tx" SG_ 817 Veh_Lock_Sub_Id 1;
BA_ "U_CD4_MY13_Gas_Tx" SG_ 817 Veh_Lock_Sub_Id 1;
BA_ "U_CD4_MY13_Hev_Tx" SG_ 817 Veh_Lock_Sub_Id 1;
BA_ "U_CD4_MY13_Phev_Tx" SG_ 817 Veh_Lock_Sub_Id 1;
BA_ "U_CD42_MY14_Diesel_Tx" SG_ 817 Veh_Lock_Sub_Id 1;
BA_ "U_CD42_MY14_Gas_Tx" SG_ 817 Veh_Lock_Sub_Id 1;
BA_ "U_P552_MY15_Gas_Tx" SG_ 817 Veh_Lock_Sub_Id 1;
BA_ "U_S550_MY15_Gas_Tx" SG_ 817 Veh_Lock_Sub_Id 1;
BA_ "U_C489_MY14_Gas_Tx" SG_ 817 Veh_Lock_Sub_Id 1;
BA_ "U_U502_MY15_Gas_Tx" SG_ 817 Veh_Lock_Sub_Id 1;
BA_ "U_UP375_MY15_Gas_Tx" SG_ 817 Veh_Lock_Sub_Id 1;
BA_ "U_UP375_MY15_Diesel_Tx" SG_ 817 Veh_Lock_Sub_Id 1;
BA_ "U_CD43_MY16_Gas_Tx" SG_ 817 Veh_Lock_Sub_Id 1;
BA_ "U_CD4_MY14_Diesel_Tx" SG_ 817 Veh_Lock_Sub_Id 1;
BA_ "U_CD4_MY14_Gas_Tx" SG_ 817 Veh_Lock_Sub_Id 1;
BA_ "U_CD4_MY14_Hev_Tx" SG_ 817 Veh_Lock_Sub_Id 1;
BA_ "U_CD4_MY14_Phev_Tx" SG_ 817 Veh_Lock_Sub_Id 1;
BA_ "WakeupSignal" SG_ 817 Veh_Lock_Status 1;
BA_ "GenSigStartValue" SG_ 817 Veh_Lock_Status 1;
BA_ "GenSigSendType" SG_ 817 Veh_Lock_Status 3;
BA_ "U_CD4_MY13_Diesel_Rx" SG_ 817 Veh_Lock_Status 1;
BA_ "U_CD4_MY13_Gas_Rx" SG_ 817 Veh_Lock_Status 1;
BA_ "U_CD4_MY13_Hev_Rx" SG_ 817 Veh_Lock_Status 1;
BA_ "U_CD4_MY13_Phev_Rx" SG_ 817 Veh_Lock_Status 1;
BA_ "U_CD42_MY14_Diesel_Rx" SG_ 817 Veh_Lock_Status 1;
BA_ "U_CD42_MY14_Gas_Rx" SG_ 817 Veh_Lock_Status 1;
BA_ "U_P552_MY15_Gas_Rx" SG_ 817 Veh_Lock_Status 1;
BA_ "U_S550_MY15_Gas_Rx" SG_ 817 Veh_Lock_Status 1;
BA_ "U_C489_MY14_Gas_Rx" SG_ 817 Veh_Lock_Status 1;
BA_ "U_U502_MY15_Gas_Rx" SG_ 817 Veh_Lock_Status 1;
BA_ "U_B479_MY15_Gas_Rx" SG_ 817 Veh_Lock_Status 1;
BA_ "U_UP375_MY15_Gas_Rx" SG_ 817 Veh_Lock_Status 1;
BA_ "U_UP375_MY15_Diesel_Rx" SG_ 817 Veh_Lock_Status 1;
BA_ "U_CD4_MY13_Diesel_Tx" SG_ 817 Veh_Lock_Status 1;
BA_ "U_CD4_MY13_Gas_Tx" SG_ 817 Veh_Lock_Status 1;
BA_ "U_CD4_MY13_Hev_Tx" SG_ 817 Veh_Lock_Status 1;
BA_ "U_CD4_MY13_Phev_Tx" SG_ 817 Veh_Lock_Status 1;
BA_ "U_CD42_MY14_Diesel_Tx" SG_ 817 Veh_Lock_Status 1;
BA_ "U_CD42_MY14_Gas_Tx" SG_ 817 Veh_Lock_Status 1;
BA_ "U_P552_MY15_Gas_Tx" SG_ 817 Veh_Lock_Status 1;
BA_ "U_S550_MY15_Gas_Tx" SG_ 817 Veh_Lock_Status 1;
BA_ "U_C489_MY14_Gas_Tx" SG_ 817 Veh_Lock_Status 1;
BA_ "U_U502_MY15_Gas_Tx" SG_ 817 Veh_Lock_Status 1;
BA_ "U_UP375_MY15_Gas_Tx" SG_ 817 Veh_Lock_Status 1;
BA_ "U_UP375_MY15_Diesel_Tx" SG_ 817 Veh_Lock_Status 1;
BA_ "U_CD43_MY16_Gas_Tx" SG_ 817 Veh_Lock_Status 1;
BA_ "U_CD4_MY14_Diesel_Tx" SG_ 817 Veh_Lock_Status 1;
BA_ "U_CD4_MY14_Gas_Tx" SG_ 817 Veh_Lock_Status 1;
BA_ "U_CD4_MY14_Hev_Tx" SG_ 817 Veh_Lock_Status 1;
BA_ "U_CD4_MY14_Phev_Tx" SG_ 817 Veh_Lock_Status 1;
BA_ "WakeupSignal" SG_ 817 ChildLck_D_Dsply 1;
BA_ "GenSigStartValue" SG_ 817 ChildLck_D_Dsply 1;
BA_ "GenSigSendType" SG_ 817 ChildLck_D_Dsply 3;
BA_ "U_CD4_MY13_Diesel_Tx" SG_ 817 ChildLck_D_Dsply 1;
BA_ "U_CD4_MY13_Gas_Tx" SG_ 817 ChildLck_D_Dsply 1;
BA_ "U_CD4_MY13_Hev_Tx" SG_ 817 ChildLck_D_Dsply 1;
BA_ "U_CD4_MY13_Phev_Tx" SG_ 817 ChildLck_D_Dsply 1;
BA_ "U_CD42_MY14_Diesel_Tx" SG_ 817 ChildLck_D_Dsply 1;
BA_ "U_CD42_MY14_Gas_Tx" SG_ 817 ChildLck_D_Dsply 1;
BA_ "U_P552_MY15_Gas_Tx" SG_ 817 ChildLck_D_Dsply 1;
BA_ "U_S550_MY15_Gas_Tx" SG_ 817 ChildLck_D_Dsply 1;
BA_ "U_C489_MY14_Gas_Tx" SG_ 817 ChildLck_D_Dsply 1;
BA_ "U_U502_MY15_Gas_Tx" SG_ 817 ChildLck_D_Dsply 1;
BA_ "U_UP375_MY15_Gas_Tx" SG_ 817 ChildLck_D_Dsply 1;
BA_ "U_UP375_MY15_Diesel_Tx" SG_ 817 ChildLck_D_Dsply 1;
BA_ "U_CD43_MY16_Gas_Tx" SG_ 817 ChildLck_D_Dsply 1;
BA_ "U_CD4_MY14_Diesel_Tx" SG_ 817 ChildLck_D_Dsply 1;
BA_ "U_CD4_MY14_Gas_Tx" SG_ 817 ChildLck_D_Dsply 1;
BA_ "U_CD4_MY14_Hev_Tx" SG_ 817 ChildLck_D_Dsply 1;
BA_ "U_CD4_MY14_Phev_Tx" SG_ 817 ChildLck_D_Dsply 1;
BA_ "GenSigSendType" SG_ 817 WindowLockout_B_Stat 3;
BA_ "U_CD4_MY13_Diesel_Tx" SG_ 817 WindowLockout_B_Stat 1;
BA_ "U_CD4_MY13_Gas_Tx" SG_ 817 WindowLockout_B_Stat 1;
BA_ "U_CD4_MY13_Hev_Tx" SG_ 817 WindowLockout_B_Stat 1;
BA_ "U_CD4_MY13_Phev_Tx" SG_ 817 WindowLockout_B_Stat 1;
BA_ "U_CD42_MY14_Diesel_Tx" SG_ 817 WindowLockout_B_Stat 1;
BA_ "U_CD42_MY14_Gas_Tx" SG_ 817 WindowLockout_B_Stat 1;
BA_ "U_P552_MY15_Gas_Tx" SG_ 817 WindowLockout_B_Stat 1;
BA_ "U_S550_MY15_Gas_Tx" SG_ 817 WindowLockout_B_Stat 1;
BA_ "U_C489_MY14_Gas_Tx" SG_ 817 WindowLockout_B_Stat 1;
BA_ "U_U502_MY15_Gas_Tx" SG_ 817 WindowLockout_B_Stat 1;
BA_ "U_UP375_MY15_Gas_Tx" SG_ 817 WindowLockout_B_Stat 1;
BA_ "U_UP375_MY15_Diesel_Tx" SG_ 817 WindowLockout_B_Stat 1;
BA_ "U_CD43_MY16_Gas_Tx" SG_ 817 WindowLockout_B_Stat 1;
BA_ "U_CD4_MY14_Diesel_Tx" SG_ 817 WindowLockout_B_Stat 1;
BA_ "U_CD4_MY14_Gas_Tx" SG_ 817 WindowLockout_B_Stat 1;
BA_ "U_CD4_MY14_Hev_Tx" SG_ 817 WindowLockout_B_Stat 1;
BA_ "U_CD4_MY14_Phev_Tx" SG_ 817 WindowLockout_B_Stat 1;
BA_ "CrossOver_InfoCAN" SG_ 817 RollCodeUnlock 1;
BA_ "GenSigSendType" SG_ 817 RollCodeUnlock 3;
BA_ "U_CD4_MY13_Diesel_Tx" SG_ 817 RollCodeUnlock 1;
BA_ "U_CD4_MY13_Gas_Tx" SG_ 817 RollCodeUnlock 1;
BA_ "U_CD4_MY13_Hev_Tx" SG_ 817 RollCodeUnlock 1;
BA_ "U_CD4_MY13_Phev_Tx" SG_ 817 RollCodeUnlock 1;
BA_ "U_CD42_MY14_Diesel_Tx" SG_ 817 RollCodeUnlock 1;
BA_ "U_CD42_MY14_Gas_Tx" SG_ 817 RollCodeUnlock 1;
BA_ "U_P552_MY15_Gas_Tx" SG_ 817 RollCodeUnlock 1;
BA_ "U_S550_MY15_Gas_Tx" SG_ 817 RollCodeUnlock 1;
BA_ "U_C489_MY14_Gas_Tx" SG_ 817 RollCodeUnlock 1;
BA_ "U_U502_MY15_Gas_Tx" SG_ 817 RollCodeUnlock 1;
BA_ "U_UP375_MY15_Gas_Tx" SG_ 817 RollCodeUnlock 1;
BA_ "U_UP375_MY15_Diesel_Tx" SG_ 817 RollCodeUnlock 1;
BA_ "U_CD43_MY16_Gas_Tx" SG_ 817 RollCodeUnlock 1;
BA_ "U_CD4_MY14_Diesel_Tx" SG_ 817 RollCodeUnlock 1;
BA_ "U_CD4_MY14_Gas_Tx" SG_ 817 RollCodeUnlock 1;
BA_ "U_CD4_MY14_Hev_Tx" SG_ 817 RollCodeUnlock 1;
BA_ "U_CD4_MY14_Phev_Tx" SG_ 817 RollCodeUnlock 1;
BA_ "WakeupSignal" SG_ 817 Lockmsgtxt_D_Rq 1;
BA_ "CrossOver_InfoCAN" SG_ 817 Lockmsgtxt_D_Rq 1;
BA_ "GenSigSendType" SG_ 817 Lockmsgtxt_D_Rq 3;
BA_ "U_CD4_MY13_Diesel_Rx" SG_ 817 Lockmsgtxt_D_Rq 1;
BA_ "U_CD4_MY13_Gas_Rx" SG_ 817 Lockmsgtxt_D_Rq 1;
BA_ "U_CD4_MY13_Hev_Rx" SG_ 817 Lockmsgtxt_D_Rq 1;
BA_ "U_CD4_MY13_Phev_Rx" SG_ 817 Lockmsgtxt_D_Rq 1;
BA_ "U_CD42_MY14_Diesel_Rx" SG_ 817 Lockmsgtxt_D_Rq 1;
BA_ "U_CD42_MY14_Gas_Rx" SG_ 817 Lockmsgtxt_D_Rq 1;
BA_ "U_P552_MY15_Gas_Rx" SG_ 817 Lockmsgtxt_D_Rq 1;
BA_ "U_S550_MY15_Gas_Rx" SG_ 817 Lockmsgtxt_D_Rq 1;
BA_ "U_C489_MY14_Gas_Rx" SG_ 817 Lockmsgtxt_D_Rq 1;
BA_ "U_U502_MY15_Gas_Rx" SG_ 817 Lockmsgtxt_D_Rq 1;
BA_ "U_B479_MY15_Gas_Rx" SG_ 817 Lockmsgtxt_D_Rq 1;
BA_ "U_UP375_MY15_Gas_Rx" SG_ 817 Lockmsgtxt_D_Rq 1;
BA_ "U_UP375_MY15_Diesel_Rx" SG_ 817 Lockmsgtxt_D_Rq 1;
BA_ "U_CD4_MY13_Diesel_Tx" SG_ 817 Lockmsgtxt_D_Rq 1;
BA_ "U_CD4_MY13_Gas_Tx" SG_ 817 Lockmsgtxt_D_Rq 1;
BA_ "U_CD4_MY13_Hev_Tx" SG_ 817 Lockmsgtxt_D_Rq 1;
BA_ "U_CD4_MY13_Phev_Tx" SG_ 817 Lockmsgtxt_D_Rq 1;
BA_ "U_CD42_MY14_Diesel_Tx" SG_ 817 Lockmsgtxt_D_Rq 1;
BA_ "U_CD42_MY14_Gas_Tx" SG_ 817 Lockmsgtxt_D_Rq 1;
BA_ "U_P552_MY15_Gas_Tx" SG_ 817 Lockmsgtxt_D_Rq 1;
BA_ "U_S550_MY15_Gas_Tx" SG_ 817 Lockmsgtxt_D_Rq 1;
BA_ "U_C489_MY14_Gas_Tx" SG_ 817 Lockmsgtxt_D_Rq 1;
BA_ "U_U502_MY15_Gas_Tx" SG_ 817 Lockmsgtxt_D_Rq 1;
BA_ "U_UP375_MY15_Gas_Tx" SG_ 817 Lockmsgtxt_D_Rq 1;
BA_ "U_UP375_MY15_Diesel_Tx" SG_ 817 Lockmsgtxt_D_Rq 1;
BA_ "U_CD43_MY16_Gas_Tx" SG_ 817 Lockmsgtxt_D_Rq 1;
BA_ "U_CD4_MY14_Diesel_Tx" SG_ 817 Lockmsgtxt_D_Rq 1;
BA_ "U_CD4_MY14_Gas_Tx" SG_ 817 Lockmsgtxt_D_Rq 1;
BA_ "U_CD4_MY14_Hev_Tx" SG_ 817 Lockmsgtxt_D_Rq 1;
BA_ "U_CD4_MY14_Phev_Tx" SG_ 817 Lockmsgtxt_D_Rq 1;
BA_ "GenSigSendType" SG_ 817 FobComm_D_Stat 3;
BA_ "U_CD4_MY13_Diesel_Tx" SG_ 817 FobComm_D_Stat 1;
BA_ "U_CD4_MY13_Gas_Tx" SG_ 817 FobComm_D_Stat 1;
BA_ "U_CD4_MY13_Hev_Tx" SG_ 817 FobComm_D_Stat 1;
BA_ "U_CD4_MY13_Phev_Tx" SG_ 817 FobComm_D_Stat 1;
BA_ "U_CD42_MY14_Diesel_Tx" SG_ 817 FobComm_D_Stat 1;
BA_ "U_CD42_MY14_Gas_Tx" SG_ 817 FobComm_D_Stat 1;
BA_ "U_P552_MY15_Gas_Tx" SG_ 817 FobComm_D_Stat 1;
BA_ "U_S550_MY15_Gas_Tx" SG_ 817 FobComm_D_Stat 1;
BA_ "U_C489_MY14_Gas_Tx" SG_ 817 FobComm_D_Stat 1;
BA_ "U_U502_MY15_Gas_Tx" SG_ 817 FobComm_D_Stat 1;
BA_ "U_UP375_MY15_Gas_Tx" SG_ 817 FobComm_D_Stat 1;
BA_ "U_UP375_MY15_Diesel_Tx" SG_ 817 FobComm_D_Stat 1;
BA_ "U_CD43_MY16_Gas_Tx" SG_ 817 FobComm_D_Stat 1;
BA_ "U_CD4_MY14_Diesel_Tx" SG_ 817 FobComm_D_Stat 1;
BA_ "U_CD4_MY14_Gas_Tx" SG_ 817 FobComm_D_Stat 1;
BA_ "U_CD4_MY14_Hev_Tx" SG_ 817 FobComm_D_Stat 1;
BA_ "U_CD4_MY14_Phev_Tx" SG_ 817 FobComm_D_Stat 1;
BA_ "WakeupSignal" SG_ 817 LockInhibit 1;
BA_ "GenSigSendType" SG_ 817 LockInhibit 3;
BA_ "U_CD4_MY13_Diesel_Tx" SG_ 817 LockInhibit 1;
BA_ "U_CD4_MY13_Gas_Tx" SG_ 817 LockInhibit 1;
BA_ "U_CD4_MY13_Hev_Tx" SG_ 817 LockInhibit 1;
BA_ "U_CD4_MY13_Phev_Tx" SG_ 817 LockInhibit 1;
BA_ "U_CD42_MY14_Diesel_Tx" SG_ 817 LockInhibit 1;
BA_ "U_CD42_MY14_Gas_Tx" SG_ 817 LockInhibit 1;
BA_ "U_P552_MY15_Gas_Tx" SG_ 817 LockInhibit 1;
BA_ "U_S550_MY15_Gas_Tx" SG_ 817 LockInhibit 1;
BA_ "U_C489_MY14_Gas_Tx" SG_ 817 LockInhibit 1;
BA_ "U_U502_MY15_Gas_Tx" SG_ 817 LockInhibit 1;
BA_ "U_UP375_MY15_Gas_Tx" SG_ 817 LockInhibit 1;
BA_ "U_UP375_MY15_Diesel_Tx" SG_ 817 LockInhibit 1;
BA_ "U_CD43_MY16_Gas_Tx" SG_ 817 LockInhibit 1;
BA_ "U_CD4_MY14_Diesel_Tx" SG_ 817 LockInhibit 1;
BA_ "U_CD4_MY14_Gas_Tx" SG_ 817 LockInhibit 1;
BA_ "U_CD4_MY14_Hev_Tx" SG_ 817 LockInhibit 1;
BA_ "U_CD4_MY14_Phev_Tx" SG_ 817 LockInhibit 1;
BA_ "CrossOver_InfoCAN" SG_ 1002 FeatNoApimActl 1;
BA_ "GenSigSendType" SG_ 1002 FeatNoApimActl 3;
BA_ "U_CD4_MY13_Diesel_Tx" SG_ 1002 FeatNoApimActl 1;
BA_ "U_CD4_MY13_Gas_Tx" SG_ 1002 FeatNoApimActl 1;
BA_ "U_CD4_MY13_Hev_Tx" SG_ 1002 FeatNoApimActl 1;
BA_ "U_CD4_MY13_Phev_Tx" SG_ 1002 FeatNoApimActl 1;
BA_ "U_CD42_MY14_Diesel_Tx" SG_ 1002 FeatNoApimActl 1;
BA_ "U_CD42_MY14_Gas_Tx" SG_ 1002 FeatNoApimActl 1;
BA_ "U_P552_MY15_Gas_Tx" SG_ 1002 FeatNoApimActl 1;
BA_ "U_S550_MY15_Gas_Tx" SG_ 1002 FeatNoApimActl 1;
BA_ "U_C489_MY14_Gas_Tx" SG_ 1002 FeatNoApimActl 1;
BA_ "U_U502_MY15_Gas_Tx" SG_ 1002 FeatNoApimActl 1;
BA_ "U_CD43_MY16_Gas_Tx" SG_ 1002 FeatNoApimActl 1;
BA_ "U_CD4_MY14_Diesel_Tx" SG_ 1002 FeatNoApimActl 1;
BA_ "U_CD4_MY14_Gas_Tx" SG_ 1002 FeatNoApimActl 1;
BA_ "U_CD4_MY14_Hev_Tx" SG_ 1002 FeatNoApimActl 1;
BA_ "U_CD4_MY14_Phev_Tx" SG_ 1002 FeatNoApimActl 1;
BA_ "CrossOver_InfoCAN" SG_ 1002 FeatConfigApimActl 1;
BA_ "GenSigSendType" SG_ 1002 FeatConfigApimActl 3;
BA_ "U_CD4_MY13_Diesel_Tx" SG_ 1002 FeatConfigApimActl 1;
BA_ "U_CD4_MY13_Gas_Tx" SG_ 1002 FeatConfigApimActl 1;
BA_ "U_CD4_MY13_Hev_Tx" SG_ 1002 FeatConfigApimActl 1;
BA_ "U_CD4_MY13_Phev_Tx" SG_ 1002 FeatConfigApimActl 1;
BA_ "U_CD42_MY14_Diesel_Tx" SG_ 1002 FeatConfigApimActl 1;
BA_ "U_CD42_MY14_Gas_Tx" SG_ 1002 FeatConfigApimActl 1;
BA_ "U_P552_MY15_Gas_Tx" SG_ 1002 FeatConfigApimActl 1;
BA_ "U_S550_MY15_Gas_Tx" SG_ 1002 FeatConfigApimActl 1;
BA_ "U_C489_MY14_Gas_Tx" SG_ 1002 FeatConfigApimActl 1;
BA_ "U_U502_MY15_Gas_Tx" SG_ 1002 FeatConfigApimActl 1;
BA_ "U_CD43_MY16_Gas_Tx" SG_ 1002 FeatConfigApimActl 1;
BA_ "U_CD4_MY14_Diesel_Tx" SG_ 1002 FeatConfigApimActl 1;
BA_ "U_CD4_MY14_Gas_Tx" SG_ 1002 FeatConfigApimActl 1;
BA_ "U_CD4_MY14_Hev_Tx" SG_ 1002 FeatConfigApimActl 1;
BA_ "U_CD4_MY14_Phev_Tx" SG_ 1002 FeatConfigApimActl 1;
BA_ "CrossOver_InfoCAN" SG_ 1002 CntrStkKeycodeActl 1;
BA_ "GenSigSendType" SG_ 1002 CntrStkKeycodeActl 3;
BA_ "U_CD4_MY13_Diesel_Rx" SG_ 1002 CntrStkKeycodeActl 1;
BA_ "U_CD4_MY13_Gas_Rx" SG_ 1002 CntrStkKeycodeActl 1;
BA_ "U_CD4_MY13_Hev_Rx" SG_ 1002 CntrStkKeycodeActl 1;
BA_ "U_CD4_MY13_Phev_Rx" SG_ 1002 CntrStkKeycodeActl 1;
BA_ "U_CD42_MY14_Diesel_Rx" SG_ 1002 CntrStkKeycodeActl 1;
BA_ "U_CD42_MY14_Gas_Rx" SG_ 1002 CntrStkKeycodeActl 1;
BA_ "U_P552_MY15_Gas_Rx" SG_ 1002 CntrStkKeycodeActl 1;
BA_ "U_S550_MY15_Gas_Rx" SG_ 1002 CntrStkKeycodeActl 1;
BA_ "U_C489_MY14_Gas_Rx" SG_ 1002 CntrStkKeycodeActl 1;
BA_ "U_U502_MY15_Gas_Rx" SG_ 1002 CntrStkKeycodeActl 1;
BA_ "U_UP375_MY15_Gas_Rx" SG_ 1002 CntrStkKeycodeActl 1;
BA_ "U_UP375_MY15_Diesel_Rx" SG_ 1002 CntrStkKeycodeActl 1;
BA_ "U_CD43_MY16_Gas_Rx" SG_ 1002 CntrStkKeycodeActl 1;
BA_ "U_CD4_MY14_Diesel_Rx" SG_ 1002 CntrStkKeycodeActl 1;
BA_ "U_CD4_MY14_Gas_Rx" SG_ 1002 CntrStkKeycodeActl 1;
BA_ "U_CD4_MY14_Hev_Rx" SG_ 1002 CntrStkKeycodeActl 1;
BA_ "U_CD4_MY14_Phev_Rx" SG_ 1002 CntrStkKeycodeActl 1;
BA_ "U_CD4_MY13_Diesel_Tx" SG_ 1002 CntrStkKeycodeActl 1;
BA_ "U_CD4_MY13_Gas_Tx" SG_ 1002 CntrStkKeycodeActl 1;
BA_ "U_CD4_MY13_Hev_Tx" SG_ 1002 CntrStkKeycodeActl 1;
BA_ "U_CD4_MY13_Phev_Tx" SG_ 1002 CntrStkKeycodeActl 1;
BA_ "U_CD42_MY14_Diesel_Tx" SG_ 1002 CntrStkKeycodeActl 1;
BA_ "U_CD42_MY14_Gas_Tx" SG_ 1002 CntrStkKeycodeActl 1;
BA_ "U_P552_MY15_Gas_Tx" SG_ 1002 CntrStkKeycodeActl 1;
BA_ "U_S550_MY15_Gas_Tx" SG_ 1002 CntrStkKeycodeActl 1;
BA_ "U_C489_MY14_Gas_Tx" SG_ 1002 CntrStkKeycodeActl 1;
BA_ "U_U502_MY15_Gas_Tx" SG_ 1002 CntrStkKeycodeActl 1;
BA_ "U_CD43_MY16_Gas_Tx" SG_ 1002 CntrStkKeycodeActl 1;
BA_ "U_CD4_MY14_Diesel_Tx" SG_ 1002 CntrStkKeycodeActl 1;
BA_ "U_CD4_MY14_Gas_Tx" SG_ 1002 CntrStkKeycodeActl 1;
BA_ "U_CD4_MY14_Hev_Tx" SG_ 1002 CntrStkKeycodeActl 1;
BA_ "U_CD4_MY14_Phev_Tx" SG_ 1002 CntrStkKeycodeActl 1;
BA_ "CrossOver_InfoCAN" SG_ 1002 CntrStk_D_RqRecall 1;
BA_ "GenSigSendType" SG_ 1002 CntrStk_D_RqRecall 3;
BA_ "U_CD4_MY13_Diesel_Rx" SG_ 1002 CntrStk_D_RqRecall 1;
BA_ "U_CD4_MY13_Gas_Rx" SG_ 1002 CntrStk_D_RqRecall 1;
BA_ "U_CD4_MY13_Hev_Rx" SG_ 1002 CntrStk_D_RqRecall 1;
BA_ "U_CD4_MY13_Phev_Rx" SG_ 1002 CntrStk_D_RqRecall 1;
BA_ "U_CD42_MY14_Diesel_Rx" SG_ 1002 CntrStk_D_RqRecall 1;
BA_ "U_CD42_MY14_Gas_Rx" SG_ 1002 CntrStk_D_RqRecall 1;
BA_ "U_P552_MY15_Gas_Rx" SG_ 1002 CntrStk_D_RqRecall 1;
BA_ "U_S550_MY15_Gas_Rx" SG_ 1002 CntrStk_D_RqRecall 1;
BA_ "U_C489_MY14_Gas_Rx" SG_ 1002 CntrStk_D_RqRecall 1;
BA_ "U_U502_MY15_Gas_Rx" SG_ 1002 CntrStk_D_RqRecall 1;
BA_ "U_UP375_MY15_Gas_Rx" SG_ 1002 CntrStk_D_RqRecall 1;
BA_ "U_UP375_MY15_Diesel_Rx" SG_ 1002 CntrStk_D_RqRecall 1;
BA_ "U_CD43_MY16_Gas_Rx" SG_ 1002 CntrStk_D_RqRecall 1;
BA_ "U_CD4_MY14_Diesel_Rx" SG_ 1002 CntrStk_D_RqRecall 1;
BA_ "U_CD4_MY14_Gas_Rx" SG_ 1002 CntrStk_D_RqRecall 1;
BA_ "U_CD4_MY14_Hev_Rx" SG_ 1002 CntrStk_D_RqRecall 1;
BA_ "U_CD4_MY14_Phev_Rx" SG_ 1002 CntrStk_D_RqRecall 1;
BA_ "U_CD4_MY13_Diesel_Tx" SG_ 1002 CntrStk_D_RqRecall 1;
BA_ "U_CD4_MY13_Gas_Tx" SG_ 1002 CntrStk_D_RqRecall 1;
BA_ "U_CD4_MY13_Hev_Tx" SG_ 1002 CntrStk_D_RqRecall 1;
BA_ "U_CD4_MY13_Phev_Tx" SG_ 1002 CntrStk_D_RqRecall 1;
BA_ "U_CD42_MY14_Diesel_Tx" SG_ 1002 CntrStk_D_RqRecall 1;
BA_ "U_CD42_MY14_Gas_Tx" SG_ 1002 CntrStk_D_RqRecall 1;
BA_ "U_P552_MY15_Gas_Tx" SG_ 1002 CntrStk_D_RqRecall 1;
BA_ "U_S550_MY15_Gas_Tx" SG_ 1002 CntrStk_D_RqRecall 1;
BA_ "U_C489_MY14_Gas_Tx" SG_ 1002 CntrStk_D_RqRecall 1;
BA_ "U_U502_MY15_Gas_Tx" SG_ 1002 CntrStk_D_RqRecall 1;
BA_ "U_CD43_MY16_Gas_Tx" SG_ 1002 CntrStk_D_RqRecall 1;
BA_ "U_CD4_MY14_Diesel_Tx" SG_ 1002 CntrStk_D_RqRecall 1;
BA_ "U_CD4_MY14_Gas_Tx" SG_ 1002 CntrStk_D_RqRecall 1;
BA_ "U_CD4_MY14_Hev_Tx" SG_ 1002 CntrStk_D_RqRecall 1;
BA_ "U_CD4_MY14_Phev_Tx" SG_ 1002 CntrStk_D_RqRecall 1;
BA_ "CrossOver_InfoCAN" SG_ 1002 CntrStk_D_RqAssoc 1;
BA_ "GenSigStartValue" SG_ 1002 CntrStk_D_RqAssoc 3;
BA_ "GenSigSendType" SG_ 1002 CntrStk_D_RqAssoc 3;
BA_ "U_CD4_MY13_Diesel_Rx" SG_ 1002 CntrStk_D_RqAssoc 1;
BA_ "U_CD4_MY13_Gas_Rx" SG_ 1002 CntrStk_D_RqAssoc 1;
BA_ "U_CD4_MY13_Hev_Rx" SG_ 1002 CntrStk_D_RqAssoc 1;
BA_ "U_CD4_MY13_Phev_Rx" SG_ 1002 CntrStk_D_RqAssoc 1;
BA_ "U_CD42_MY14_Diesel_Rx" SG_ 1002 CntrStk_D_RqAssoc 1;
BA_ "U_CD42_MY14_Gas_Rx" SG_ 1002 CntrStk_D_RqAssoc 1;
BA_ "U_P552_MY15_Gas_Rx" SG_ 1002 CntrStk_D_RqAssoc 1;
BA_ "U_S550_MY15_Gas_Rx" SG_ 1002 CntrStk_D_RqAssoc 1;
BA_ "U_C489_MY14_Gas_Rx" SG_ 1002 CntrStk_D_RqAssoc 1;
BA_ "U_U502_MY15_Gas_Rx" SG_ 1002 CntrStk_D_RqAssoc 1;
BA_ "U_UP375_MY15_Gas_Rx" SG_ 1002 CntrStk_D_RqAssoc 1;
BA_ "U_UP375_MY15_Diesel_Rx" SG_ 1002 CntrStk_D_RqAssoc 1;
BA_ "U_CD43_MY16_Gas_Rx" SG_ 1002 CntrStk_D_RqAssoc 1;
BA_ "U_CD4_MY14_Diesel_Rx" SG_ 1002 CntrStk_D_RqAssoc 1;
BA_ "U_CD4_MY14_Gas_Rx" SG_ 1002 CntrStk_D_RqAssoc 1;
BA_ "U_CD4_MY14_Hev_Rx" SG_ 1002 CntrStk_D_RqAssoc 1;
BA_ "U_CD4_MY14_Phev_Rx" SG_ 1002 CntrStk_D_RqAssoc 1;
BA_ "U_CD4_MY13_Diesel_Tx" SG_ 1002 CntrStk_D_RqAssoc 1;
BA_ "U_CD4_MY13_Gas_Tx" SG_ 1002 CntrStk_D_RqAssoc 1;
BA_ "U_CD4_MY13_Hev_Tx" SG_ 1002 CntrStk_D_RqAssoc 1;
BA_ "U_CD4_MY13_Phev_Tx" SG_ 1002 CntrStk_D_RqAssoc 1;
BA_ "U_CD42_MY14_Diesel_Tx" SG_ 1002 CntrStk_D_RqAssoc 1;
BA_ "U_CD42_MY14_Gas_Tx" SG_ 1002 CntrStk_D_RqAssoc 1;
BA_ "U_P552_MY15_Gas_Tx" SG_ 1002 CntrStk_D_RqAssoc 1;
BA_ "U_S550_MY15_Gas_Tx" SG_ 1002 CntrStk_D_RqAssoc 1;
BA_ "U_C489_MY14_Gas_Tx" SG_ 1002 CntrStk_D_RqAssoc 1;
BA_ "U_U502_MY15_Gas_Tx" SG_ 1002 CntrStk_D_RqAssoc 1;
BA_ "U_CD43_MY16_Gas_Tx" SG_ 1002 CntrStk_D_RqAssoc 1;
BA_ "U_CD4_MY14_Diesel_Tx" SG_ 1002 CntrStk_D_RqAssoc 1;
BA_ "U_CD4_MY14_Gas_Tx" SG_ 1002 CntrStk_D_RqAssoc 1;
BA_ "U_CD4_MY14_Hev_Tx" SG_ 1002 CntrStk_D_RqAssoc 1;
BA_ "U_CD4_MY14_Phev_Tx" SG_ 1002 CntrStk_D_RqAssoc 1;
BA_ "CrossOver_InfoCAN" SG_ 1002 PersIndexApim_D_Actl 1;
BA_ "GenSigStartValue" SG_ 1002 PersIndexApim_D_Actl 4;
BA_ "GenSigSendType" SG_ 1002 PersIndexApim_D_Actl 3;
BA_ "U_CD4_MY13_Diesel_Tx" SG_ 1002 PersIndexApim_D_Actl 1;
BA_ "U_CD4_MY13_Gas_Tx" SG_ 1002 PersIndexApim_D_Actl 1;
BA_ "U_CD4_MY13_Hev_Tx" SG_ 1002 PersIndexApim_D_Actl 1;
BA_ "U_CD4_MY13_Phev_Tx" SG_ 1002 PersIndexApim_D_Actl 1;
BA_ "U_CD42_MY14_Diesel_Tx" SG_ 1002 PersIndexApim_D_Actl 1;
BA_ "U_CD42_MY14_Gas_Tx" SG_ 1002 PersIndexApim_D_Actl 1;
BA_ "U_P552_MY15_Gas_Tx" SG_ 1002 PersIndexApim_D_Actl 1;
BA_ "U_S550_MY15_Gas_Tx" SG_ 1002 PersIndexApim_D_Actl 1;
BA_ "U_C489_MY14_Gas_Tx" SG_ 1002 PersIndexApim_D_Actl 1;
BA_ "U_U502_MY15_Gas_Tx" SG_ 1002 PersIndexApim_D_Actl 1;
BA_ "U_CD43_MY16_Gas_Tx" SG_ 1002 PersIndexApim_D_Actl 1;
BA_ "U_CD4_MY14_Diesel_Tx" SG_ 1002 PersIndexApim_D_Actl 1;
BA_ "U_CD4_MY14_Gas_Tx" SG_ 1002 PersIndexApim_D_Actl 1;
BA_ "U_CD4_MY14_Hev_Tx" SG_ 1002 PersIndexApim_D_Actl 1;
BA_ "U_CD4_MY14_Phev_Tx" SG_ 1002 PersIndexApim_D_Actl 1;
BA_ "U_CD4_MY13_Diesel_Rx" SG_ 390 AccStopStat_B_Rq 1;
BA_ "U_CD42_MY15_Diesel_Rx" SG_ 390 AccStopStat_B_Rq 1;
BA_ "U_CD43_MY16_Gas_Rx" SG_ 390 AccStopStat_B_Rq 1;
BA_ "U_CD4_MY14_Diesel_Rx" SG_ 390 AccStopStat_B_Rq 1;
BA_ "U_CD4_MY14_Gas_Rx" SG_ 390 AccStopStat_B_Rq 1;
BA_ "U_CD4_MY14_Hev_Rx" SG_ 390 AccStopStat_B_Rq 1;
BA_ "U_CD4_MY14_Phev_Rx" SG_ 390 AccStopStat_B_Rq 1;
BA_ "U_CD4_MY17_Diesel_Rx" SG_ 390 AccStopStat_B_Rq 1;
BA_ "U_CD4_MY17_Gas_Rx" SG_ 390 AccStopStat_B_Rq 1;
BA_ "U_CD4_MY17_Hev_Rx" SG_ 390 AccStopStat_B_Rq 1;
BA_ "U_CD4_MY17_Phev_Rx" SG_ 390 AccStopStat_B_Rq 1;
BA_ "U_CD42_MY16_Diesel_Rx" SG_ 390 AccStopStat_B_Rq 1;
BA_ "U_CD43_MY17_Gas_Rx" SG_ 390 AccStopStat_B_Rq 1;
BA_ "U_U55x_MY18_Gas_Rx" SG_ 390 AccStopStat_B_Rq 1;
BA_ "GenSigTimeoutTime_ECM" SG_ 390 AccStopStat_B_Rq 1000;
BA_ "GenSigTimeoutTime_PCM" SG_ 390 AccStopStat_B_Rq 1000;
BA_ "GenSigTimeoutTime_ECM_HEV" SG_ 390 AccStopStat_B_Rq 1000;
BA_ "WakeupSignal" SG_ 390 AccResumEnbl_B_Rq 1;
BA_ "U_CD4_MY13_Diesel_Rx" SG_ 390 AccResumEnbl_B_Rq 1;
BA_ "U_CD42_MY15_Diesel_Rx" SG_ 390 AccResumEnbl_B_Rq 1;
BA_ "U_CD43_MY16_Gas_Rx" SG_ 390 AccResumEnbl_B_Rq 1;
BA_ "U_CD4_MY14_Diesel_Rx" SG_ 390 AccResumEnbl_B_Rq 1;
BA_ "U_CD4_MY14_Gas_Rx" SG_ 390 AccResumEnbl_B_Rq 1;
BA_ "U_CD4_MY14_Hev_Rx" SG_ 390 AccResumEnbl_B_Rq 1;
BA_ "U_CD4_MY14_Phev_Rx" SG_ 390 AccResumEnbl_B_Rq 1;
BA_ "U_CD4_MY17_Diesel_Rx" SG_ 390 AccResumEnbl_B_Rq 1;
BA_ "U_CD4_MY17_Gas_Rx" SG_ 390 AccResumEnbl_B_Rq 1;
BA_ "U_CD4_MY17_Hev_Rx" SG_ 390 AccResumEnbl_B_Rq 1;
BA_ "U_CD4_MY17_Phev_Rx" SG_ 390 AccResumEnbl_B_Rq 1;
BA_ "U_CD42_MY16_Diesel_Rx" SG_ 390 AccResumEnbl_B_Rq 1;
BA_ "U_CD43_MY17_Gas_Rx" SG_ 390 AccResumEnbl_B_Rq 1;
BA_ "U_U55x_MY18_Gas_Rx" SG_ 390 AccResumEnbl_B_Rq 1;
BA_ "GenSigStartValue" SG_ 390 AccBrkTot_A_Rq 5129;
BA_ "U_CD4_MY13_Gas_Rx" SG_ 390 AccPrpl_A_Pred 1;
BA_ "U_CD42_MY14_Gas_Rx" SG_ 390 AccPrpl_A_Pred 1;
BA_ "U_P552_MY15_Gas_Rx" SG_ 390 AccPrpl_A_Pred 1;
BA_ "U_S550_MY15_Gas_Rx" SG_ 390 AccPrpl_A_Pred 1;
BA_ "U_C489_MY14_Gas_Rx" SG_ 390 AccPrpl_A_Pred 1;
BA_ "U_U502_MY15_Gas_Rx" SG_ 390 AccPrpl_A_Pred 1;
BA_ "U_UP375_MY15_Gas_Rx" SG_ 390 AccPrpl_A_Pred 1;
BA_ "U_CD43_MY16_Gas_Rx" SG_ 390 AccPrpl_A_Pred 1;
BA_ "U_CD4_MY14_Gas_Rx" SG_ 390 AccPrpl_A_Pred 1;
BA_ "U_CD4_MY13_Gas_Rx" SG_ 390 AccVeh_V_Trg 1;
BA_ "U_CD42_MY14_Gas_Rx" SG_ 390 AccVeh_V_Trg 1;
BA_ "U_P552_MY15_Gas_Rx" SG_ 390 AccVeh_V_Trg 1;
BA_ "U_S550_MY15_Gas_Rx" SG_ 390 AccVeh_V_Trg 1;
BA_ "U_C489_MY14_Gas_Rx" SG_ 390 AccVeh_V_Trg 1;
BA_ "U_U502_MY15_Gas_Rx" SG_ 390 AccVeh_V_Trg 1;
BA_ "U_UP375_MY15_Gas_Rx" SG_ 390 AccVeh_V_Trg 1;
BA_ "U_CD43_MY16_Gas_Rx" SG_ 390 AccVeh_V_Trg 1;
BA_ "U_CD4_MY14_Gas_Rx" SG_ 390 AccVeh_V_Trg 1;
BA_ "GenSigTimeoutTime_TCM" SG_ 390 AccVeh_V_Trg 60;
BA_ "U_CD4_MY13_Gas_Rx" SG_ 390 AccPrpl_A_Rq 1;
BA_ "U_CD42_MY14_Gas_Rx" SG_ 390 AccPrpl_A_Rq 1;
BA_ "U_P552_MY15_Gas_Rx" SG_ 390 AccPrpl_A_Rq 1;
BA_ "U_S550_MY15_Gas_Rx" SG_ 390 AccPrpl_A_Rq 1;
BA_ "U_C489_MY14_Gas_Rx" SG_ 390 AccPrpl_A_Rq 1;
BA_ "U_U502_MY15_Gas_Rx" SG_ 390 AccPrpl_A_Rq 1;
BA_ "U_UP375_MY15_Gas_Rx" SG_ 390 AccPrpl_A_Rq 1;
BA_ "U_CD43_MY16_Gas_Rx" SG_ 390 AccPrpl_A_Rq 1;
BA_ "U_CD4_MY14_Gas_Rx" SG_ 390 AccPrpl_A_Rq 1;
BA_ "GenSigTimeoutTime_PCM" SG_ 390 AccPrpl_A_Rq 1000;
BA_ "U_CD4_MY13_Gas_Rx" SG_ 390 AccDeny_B_Rq 1;
BA_ "U_CD42_MY14_Gas_Rx" SG_ 390 AccDeny_B_Rq 1;
BA_ "U_P552_MY15_Gas_Rx" SG_ 390 AccDeny_B_Rq 1;
BA_ "U_S550_MY15_Gas_Rx" SG_ 390 AccDeny_B_Rq 1;
BA_ "U_C489_MY14_Gas_Rx" SG_ 390 AccDeny_B_Rq 1;
BA_ "U_U502_MY15_Gas_Rx" SG_ 390 AccDeny_B_Rq 1;
BA_ "U_UP375_MY15_Gas_Rx" SG_ 390 AccDeny_B_Rq 1;
BA_ "U_CD43_MY16_Gas_Rx" SG_ 390 AccDeny_B_Rq 1;
BA_ "U_CD4_MY14_Gas_Rx" SG_ 390 AccDeny_B_Rq 1;
BA_ "U_CD4_MY13_Gas_Rx" SG_ 390 AccCancl_B_Rq 1;
BA_ "U_CD42_MY14_Gas_Rx" SG_ 390 AccCancl_B_Rq 1;
BA_ "U_P552_MY15_Gas_Rx" SG_ 390 AccCancl_B_Rq 1;
BA_ "U_S550_MY15_Gas_Rx" SG_ 390 AccCancl_B_Rq 1;
BA_ "U_C489_MY14_Gas_Rx" SG_ 390 AccCancl_B_Rq 1;
BA_ "U_U502_MY15_Gas_Rx" SG_ 390 AccCancl_B_Rq 1;
BA_ "U_UP375_MY15_Gas_Rx" SG_ 390 AccCancl_B_Rq 1;
BA_ "U_CD43_MY16_Gas_Rx" SG_ 390 AccCancl_B_Rq 1;
BA_ "U_CD4_MY14_Gas_Rx" SG_ 390 AccCancl_B_Rq 1;
BA_ "GenSigTimeoutTime_PCM" SG_ 390 AccCancl_B_Rq 1000;
BA_ "U_UP375_MY19_Diesel_Rx" SG_ 1046 HdcMde_D_Actl 1;
BA_ "U_UP375_MY19_Gas_Rx" SG_ 1046 HdcMde_D_Actl 1;
BA_ "U_U502_MY16_Gas_Rx" SG_ 1046 HdcMde_D_Actl 1;
BA_ "CrossOver_InfoCAN" SG_ 1046 HdcMde_D_Actl 1;
BA_ "U_CD42_MY16_Gas_Rx" SG_ 1046 StabCtlBrk_B_Avail 1;
BA_ "U_CD42_MY16_Diesel_Rx" SG_ 1046 StabCtlBrk_B_Avail 1;
BA_ "U_CD4_MY17_Gas_Rx" SG_ 1046 StabCtlBrk_B_Avail 1;
BA_ "U_CD4_MY17_Diesel_Rx" SG_ 1046 StabCtlBrk_B_Avail 1;
BA_ "U_CD4_MY14_Diesel_Rx" SG_ 1046 StabCtlBrk_B_Avail 1;
BA_ "U_CD43_MY16_Gas_Rx" SG_ 1046 StabCtlBrk_B_Avail 1;
BA_ "U_CD42_MY15_Diesel_Rx" SG_ 1046 StabCtlBrk_B_Avail 1;
BA_ "U_CD4_MY13_Diesel_Rx" SG_ 1046 StabCtlBrk_B_Avail 1;
BA_ "GenSigStartValue" SG_ 1046 StabCtlBrk_B_Avail 1;
BA_ "CrossOver_InfoCAN" SG_ 1046 StabCtlBrk_B_Avail 1;
BA_ "CrossOver_InfoCAN" SG_ 1046 BrkBstrVac_B_Rq 1;
BA_ "U_CD4_MY13_Diesel_Rx" SG_ 1046 BrkBstrVac_B_Rq 1;
BA_ "U_CD42_MY15_Diesel_Rx" SG_ 1046 BrkBstrVac_B_Rq 1;
BA_ "U_U502_MY16_Gas_Rx" SG_ 1046 BrkBstrVac_B_Rq 1;
BA_ "U_UP375_MY15_Diesel_Rx" SG_ 1046 BrkBstrVac_B_Rq 1;
BA_ "U_CD4_MY14_Diesel_Rx" SG_ 1046 BrkBstrVac_B_Rq 1;
BA_ "U_CD4_MY14_Gas_Rx" SG_ 1046 BrkBstrVac_B_Rq 1;
BA_ "U_CD4_MY14_Hev_Rx" SG_ 1046 BrkBstrVac_B_Rq 1;
BA_ "U_CD4_MY14_Phev_Rx" SG_ 1046 BrkBstrVac_B_Rq 1;
BA_ "U_CD4_MY17_Diesel_Rx" SG_ 1046 BrkBstrVac_B_Rq 1;
BA_ "U_CD4_MY17_Hev_Rx" SG_ 1046 BrkBstrVac_B_Rq 1;
BA_ "U_CD4_MY17_Phev_Rx" SG_ 1046 BrkBstrVac_B_Rq 1;
BA_ "U_V36X_MY16_5_Diesel_Rx" SG_ 1046 BrkBstrVac_B_Rq 1;
BA_ "U_CD42_MY16_Diesel_Rx" SG_ 1046 BrkBstrVac_B_Rq 1;
BA_ "U_CD42_MY16_Gas_Rx" SG_ 1046 BrkBstrVac_B_Rq 1;
BA_ "U_U55x_MY18_Gas_Rx" SG_ 1046 BrkBstrVac_B_Rq 1;
BA_ "CrossOver_InfoCAN" SG_ 1046 DrvSlipCtlMde_D_Ind 1;
BA_ "U_CD4_MY13_Diesel_Rx" SG_ 1046 DrvSlipCtlMde_D_Ind 1;
BA_ "U_CD4_MY13_Gas_Rx" SG_ 1046 DrvSlipCtlMde_D_Ind 1;
BA_ "U_CD4_MY13_Hev_Rx" SG_ 1046 DrvSlipCtlMde_D_Ind 1;
BA_ "U_CD4_MY13_Phev_Rx" SG_ 1046 DrvSlipCtlMde_D_Ind 1;
BA_ "U_CD42_MY14_Diesel_Rx" SG_ 1046 DrvSlipCtlMde_D_Ind 1;
BA_ "U_CD42_MY14_Gas_Rx" SG_ 1046 DrvSlipCtlMde_D_Ind 1;
BA_ "U_P552_MY15_Gas_Rx" SG_ 1046 DrvSlipCtlMde_D_Ind 1;
BA_ "U_S550_MY15_Gas_Rx" SG_ 1046 DrvSlipCtlMde_D_Ind 1;
BA_ "U_C489_MY14_Gas_Rx" SG_ 1046 DrvSlipCtlMde_D_Ind 1;
BA_ "U_U502_MY15_Gas_Rx" SG_ 1046 DrvSlipCtlMde_D_Ind 1;
BA_ "U_UP375_MY15_Gas_Rx" SG_ 1046 DrvSlipCtlMde_D_Ind 1;
BA_ "U_UP375_MY15_Diesel_Rx" SG_ 1046 DrvSlipCtlMde_D_Ind 1;
BA_ "U_CD43_MY16_Gas_Rx" SG_ 1046 DrvSlipCtlMde_D_Ind 1;
BA_ "U_CD4_MY14_Diesel_Rx" SG_ 1046 DrvSlipCtlMde_D_Ind 1;
BA_ "U_CD4_MY14_Gas_Rx" SG_ 1046 DrvSlipCtlMde_D_Ind 1;
BA_ "U_CD4_MY14_Hev_Rx" SG_ 1046 DrvSlipCtlMde_D_Ind 1;
BA_ "U_CD4_MY14_Phev_Rx" SG_ 1046 DrvSlipCtlMde_D_Ind 1;
BA_ "CrossOver_InfoCAN" SG_ 1046 BpedMove_No_Cs 1;
BA_ "U_CD4_MY13_Gas_Rx" SG_ 1046 BpedMove_No_Cs 1;
BA_ "U_CD42_MY14_Gas_Rx" SG_ 1046 BpedMove_No_Cs 1;
BA_ "U_P552_MY15_Gas_Rx" SG_ 1046 BpedMove_No_Cs 1;
BA_ "U_S550_MY15_Gas_Rx" SG_ 1046 BpedMove_No_Cs 1;
BA_ "U_C489_MY14_Gas_Rx" SG_ 1046 BpedMove_No_Cs 1;
BA_ "U_U502_MY15_Gas_Rx" SG_ 1046 BpedMove_No_Cs 1;
BA_ "U_CD43_MY16_Gas_Rx" SG_ 1046 BpedMove_No_Cs 1;
BA_ "U_CD4_MY14_Gas_Rx" SG_ 1046 BpedMove_No_Cs 1;
BA_ "CrossOver_InfoCAN" SG_ 1046 DrvAntiLckLamp_D_Rq 1;
BA_ "U_CD4_MY13_Diesel_Rx" SG_ 1046 DrvAntiLckLamp_D_Rq 1;
BA_ "U_CD4_MY13_Gas_Rx" SG_ 1046 DrvAntiLckLamp_D_Rq 1;
BA_ "U_CD4_MY13_Hev_Rx" SG_ 1046 DrvAntiLckLamp_D_Rq 1;
BA_ "U_CD4_MY13_Phev_Rx" SG_ 1046 DrvAntiLckLamp_D_Rq 1;
BA_ "U_CD42_MY14_Diesel_Rx" SG_ 1046 DrvAntiLckLamp_D_Rq 1;
BA_ "U_CD42_MY14_Gas_Rx" SG_ 1046 DrvAntiLckLamp_D_Rq 1;
BA_ "U_P552_MY15_Gas_Rx" SG_ 1046 DrvAntiLckLamp_D_Rq 1;
BA_ "U_C489_MY14_Gas_Rx" SG_ 1046 DrvAntiLckLamp_D_Rq 1;
BA_ "U_U502_MY15_Gas_Rx" SG_ 1046 DrvAntiLckLamp_D_Rq 1;
BA_ "U_UP375_MY15_Gas_Rx" SG_ 1046 DrvAntiLckLamp_D_Rq 1;
BA_ "U_UP375_MY15_Diesel_Rx" SG_ 1046 DrvAntiLckLamp_D_Rq 1;
BA_ "U_CD43_MY16_Gas_Rx" SG_ 1046 DrvAntiLckLamp_D_Rq 1;
BA_ "U_CD4_MY14_Diesel_Rx" SG_ 1046 DrvAntiLckLamp_D_Rq 1;
BA_ "U_CD4_MY14_Gas_Rx" SG_ 1046 DrvAntiLckLamp_D_Rq 1;
BA_ "U_CD4_MY14_Hev_Rx" SG_ 1046 DrvAntiLckLamp_D_Rq 1;
BA_ "U_CD4_MY14_Phev_Rx" SG_ 1046 DrvAntiLckLamp_D_Rq 1;
BA_ "CrossOver_InfoCAN" SG_ 1046 DrvHdcLampInfo_D_Rq 1;
BA_ "CrossOver_InfoCAN" SG_ 1046 ChimeBrk_B_Rq 1;
BA_ "CrossOver_InfoCAN" SG_ 1046 BrkLamp_B_Rq 1;
BA_ "CrossOver_InfoCAN" SG_ 1046 HILL_DESC_MC 1;
BA_ "CrossOver_InfoCAN" SG_ 1046 TCMode 1;
BA_ "ContentDependant" SG_ 1046 TCMode 1;
BA_ "U_CD4_MY13_Diesel_Rx" SG_ 1046 TCMode 1;
BA_ "U_CD4_MY13_Gas_Rx" SG_ 1046 TCMode 1;
BA_ "U_CD4_MY13_Hev_Rx" SG_ 1046 TCMode 1;
BA_ "U_CD4_MY13_Phev_Rx" SG_ 1046 TCMode 1;
BA_ "U_CD42_MY14_Diesel_Rx" SG_ 1046 TCMode 1;
BA_ "U_CD42_MY14_Gas_Rx" SG_ 1046 TCMode 1;
BA_ "U_P552_MY15_Gas_Rx" SG_ 1046 TCMode 1;
BA_ "U_C489_MY14_Gas_Rx" SG_ 1046 TCMode 1;
BA_ "U_U502_MY15_Gas_Rx" SG_ 1046 TCMode 1;
BA_ "U_CD43_MY16_Gas_Rx" SG_ 1046 TCMode 1;
BA_ "U_CD4_MY14_Gas_Rx" SG_ 1046 TCMode 1;
BA_ "U_UP375_MY15_Gas_Rx" SG_ 1046 TCMode 1;
BA_ "U_UP375_MY15_Diesel_Rx" SG_ 1046 TCMode 1;
BA_ "U_CD4_MY14_Diesel_Rx" SG_ 1046 TCMode 1;
BA_ "U_CD4_MY14_Hev_Rx" SG_ 1046 TCMode 1;
BA_ "U_CD4_MY14_Phev_Rx" SG_ 1046 TCMode 1;
BA_ "CrossOver_InfoCAN" SG_ 1046 DrvSlipCtlLamp_D_Rq 1;
BA_ "U_CD4_MY13_Diesel_Rx" SG_ 1046 DrvSlipCtlLamp_D_Rq 1;
BA_ "U_CD4_MY13_Gas_Rx" SG_ 1046 DrvSlipCtlLamp_D_Rq 1;
BA_ "U_CD4_MY13_Hev_Rx" SG_ 1046 DrvSlipCtlLamp_D_Rq 1;
BA_ "U_CD4_MY13_Phev_Rx" SG_ 1046 DrvSlipCtlLamp_D_Rq 1;
BA_ "U_CD42_MY14_Diesel_Rx" SG_ 1046 DrvSlipCtlLamp_D_Rq 1;
BA_ "U_CD42_MY14_Gas_Rx" SG_ 1046 DrvSlipCtlLamp_D_Rq 1;
BA_ "U_P552_MY15_Gas_Rx" SG_ 1046 DrvSlipCtlLamp_D_Rq 1;
BA_ "U_C489_MY14_Gas_Rx" SG_ 1046 DrvSlipCtlLamp_D_Rq 1;
BA_ "U_U502_MY15_Gas_Rx" SG_ 1046 DrvSlipCtlLamp_D_Rq 1;
BA_ "U_CD43_MY16_Gas_Rx" SG_ 1046 DrvSlipCtlLamp_D_Rq 1;
BA_ "U_CD4_MY14_Gas_Rx" SG_ 1046 DrvSlipCtlLamp_D_Rq 1;
BA_ "U_UP375_MY15_Gas_Rx" SG_ 1046 DrvSlipCtlLamp_D_Rq 1;
BA_ "U_UP375_MY15_Diesel_Rx" SG_ 1046 DrvSlipCtlLamp_D_Rq 1;
BA_ "U_CD4_MY14_Diesel_Rx" SG_ 1046 DrvSlipCtlLamp_D_Rq 1;
BA_ "U_CD4_MY14_Hev_Rx" SG_ 1046 DrvSlipCtlLamp_D_Rq 1;
BA_ "U_CD4_MY14_Phev_Rx" SG_ 1046 DrvSlipCtlLamp_D_Rq 1;
BA_ "CrossOver_InfoCAN" SG_ 1046 Abs_B_Falt 1;
BA_ "U_CD4_MY13_Gas_Rx" SG_ 1046 Abs_B_Falt 1;
BA_ "U_CD42_MY14_Gas_Rx" SG_ 1046 Abs_B_Falt 1;
BA_ "U_P552_MY15_Gas_Rx" SG_ 1046 Abs_B_Falt 1;
BA_ "U_S550_MY15_Gas_Rx" SG_ 1046 Abs_B_Falt 1;
BA_ "U_C489_MY14_Gas_Rx" SG_ 1046 Abs_B_Falt 1;
BA_ "U_U502_MY15_Gas_Rx" SG_ 1046 Abs_B_Falt 1;
BA_ "U_CD43_MY16_Gas_Rx" SG_ 1046 Abs_B_Falt 1;
BA_ "U_CD4_MY14_Gas_Rx" SG_ 1046 Abs_B_Falt 1;
BA_ "CrossOver_InfoCAN" SG_ 1046 BpedMove_No_Cnt 1;
BA_ "U_CD4_MY13_Gas_Rx" SG_ 1046 BpedMove_No_Cnt 1;
BA_ "U_CD42_MY14_Gas_Rx" SG_ 1046 BpedMove_No_Cnt 1;
BA_ "U_P552_MY15_Gas_Rx" SG_ 1046 BpedMove_No_Cnt 1;
BA_ "U_S550_MY15_Gas_Rx" SG_ 1046 BpedMove_No_Cnt 1;
BA_ "U_C489_MY14_Gas_Rx" SG_ 1046 BpedMove_No_Cnt 1;
BA_ "U_U502_MY15_Gas_Rx" SG_ 1046 BpedMove_No_Cnt 1;
BA_ "U_CD43_MY16_Gas_Rx" SG_ 1046 BpedMove_No_Cnt 1;
BA_ "U_CD4_MY14_Gas_Rx" SG_ 1046 BpedMove_No_Cnt 1;
BA_ "CrossOver_InfoCAN" SG_ 1046 BpedMove_D_Actl 1;
BA_ "U_CD4_MY13_Gas_Rx" SG_ 1046 BpedMove_D_Actl 1;
BA_ "U_CD42_MY14_Gas_Rx" SG_ 1046 BpedMove_D_Actl 1;
BA_ "U_P552_MY15_Gas_Rx" SG_ 1046 BpedMove_D_Actl 1;
BA_ "U_S550_MY15_Gas_Rx" SG_ 1046 BpedMove_D_Actl 1;
BA_ "U_C489_MY14_Gas_Rx" SG_ 1046 BpedMove_D_Actl 1;
BA_ "U_U502_MY15_Gas_Rx" SG_ 1046 BpedMove_D_Actl 1;
BA_ "U_CD43_MY16_Gas_Rx" SG_ 1046 BpedMove_D_Actl 1;
BA_ "U_CD4_MY14_Gas_Rx" SG_ 1046 BpedMove_D_Actl 1;
BA_ "GenSigStartValue" SG_ 125 VehRolComp_W_Actl 4094;
BA_ "GenSigStartValue" SG_ 125 VehVertComp_A_Actl 1022;
BA_ "U_CD4_MY13_Gas_Rx" SG_ 125 BrkTot_Tq_RqArb 1;
BA_ "U_CD42_MY14_Gas_Rx" SG_ 125 BrkTot_Tq_RqArb 1;
BA_ "U_P552_MY15_Gas_Rx" SG_ 125 BrkTot_Tq_RqArb 1;
BA_ "U_S550_MY15_Gas_Rx" SG_ 125 BrkTot_Tq_RqArb 1;
BA_ "U_C489_MY14_Gas_Rx" SG_ 125 BrkTot_Tq_RqArb 1;
BA_ "U_U502_MY15_Gas_Rx" SG_ 125 BrkTot_Tq_RqArb 1;
BA_ "U_CD43_MY16_Gas_Rx" SG_ 125 BrkTot_Tq_RqArb 1;
BA_ "U_CD4_MY14_Gas_Rx" SG_ 125 BrkTot_Tq_RqArb 1;
BA_ "GenSigTimeoutTime_TCM" SG_ 125 BrkTot_Tq_RqArb 60;
BA_ "U_CD4_MY13_Gas_Rx" SG_ 125 BrkTot_Tq_Actl 1;
BA_ "U_CD42_MY14_Gas_Rx" SG_ 125 BrkTot_Tq_Actl 1;
BA_ "U_P552_MY15_Gas_Rx" SG_ 125 BrkTot_Tq_Actl 1;
BA_ "U_S550_MY15_Gas_Rx" SG_ 125 BrkTot_Tq_Actl 1;
BA_ "U_C489_MY14_Gas_Rx" SG_ 125 BrkTot_Tq_Actl 1;
BA_ "U_U502_MY15_Gas_Rx" SG_ 125 BrkTot_Tq_Actl 1;
BA_ "U_CD43_MY16_Gas_Rx" SG_ 125 BrkTot_Tq_Actl 1;
BA_ "U_CD4_MY14_Gas_Rx" SG_ 125 BrkTot_Tq_Actl 1;
BA_ "CrossOver_InfoCAN" SG_ 125 HsaStat_D_Actl 1;
BA_ "U_CD4_MY13_Gas_Rx" SG_ 125 HsaStat_D_Actl 1;
BA_ "U_CD42_MY14_Gas_Rx" SG_ 125 HsaStat_D_Actl 1;
BA_ "U_P552_MY15_Gas_Rx" SG_ 125 HsaStat_D_Actl 1;
BA_ "U_U502_MY15_Gas_Rx" SG_ 125 HsaStat_D_Actl 1;
BA_ "U_CD43_MY16_Gas_Rx" SG_ 125 HsaStat_D_Actl 1;
BA_ "U_CD4_MY14_Gas_Rx" SG_ 125 HsaStat_D_Actl 1;
BA_ "GenSigStartValue" SG_ 119 VehLongComp_A_Actl 1022;
BA_ "U_CD4_MY13_Gas_Rx" SG_ 119 VehLongComp_A_Actl 1;
BA_ "U_CD42_MY14_Gas_Rx" SG_ 119 VehLongComp_A_Actl 1;
BA_ "U_P552_MY15_Gas_Rx" SG_ 119 VehLongComp_A_Actl 1;
BA_ "U_S550_MY15_Gas_Rx" SG_ 119 VehLongComp_A_Actl 1;
BA_ "U_C489_MY14_Gas_Rx" SG_ 119 VehLongComp_A_Actl 1;
BA_ "U_U502_MY15_Gas_Rx" SG_ 119 VehLongComp_A_Actl 1;
BA_ "U_CD43_MY16_Gas_Rx" SG_ 119 VehLongComp_A_Actl 1;
BA_ "U_CD4_MY14_Gas_Rx" SG_ 119 VehLongComp_A_Actl 1;
BA_ "GenSigTimeoutTime_TCM" SG_ 119 VehLongComp_A_Actl 60;
BA_ "GenSigStartValue" SG_ 119 VehLatComp_A_Actl 1022;
BA_ "U_CD4_MY13_Gas_Rx" SG_ 119 VehLatComp_A_Actl 1;
BA_ "U_CD42_MY14_Gas_Rx" SG_ 119 VehLatComp_A_Actl 1;
BA_ "U_P552_MY15_Gas_Rx" SG_ 119 VehLatComp_A_Actl 1;
BA_ "U_S550_MY15_Gas_Rx" SG_ 119 VehLatComp_A_Actl 1;
BA_ "U_C489_MY14_Gas_Rx" SG_ 119 VehLatComp_A_Actl 1;
BA_ "U_U502_MY15_Gas_Rx" SG_ 119 VehLatComp_A_Actl 1;
BA_ "U_CD43_MY16_Gas_Rx" SG_ 119 VehLatComp_A_Actl 1;
BA_ "U_CD4_MY14_Gas_Rx" SG_ 119 VehLatComp_A_Actl 1;
BA_ "GenSigTimeoutTime_TCM" SG_ 119 VehLatComp_A_Actl 60;
BA_ "CrossOver_InfoCAN" SG_ 119 VehYawComp_W_Actl 1;
BA_ "GenSigStartValue" SG_ 119 VehYawComp_W_Actl 4094;
BA_ "U_CD4_MY13_Gas_Rx" SG_ 119 VehYawComp_W_Actl 1;
BA_ "U_CD42_MY14_Diesel_Rx" SG_ 119 VehYawComp_W_Actl 1;
BA_ "U_CD42_MY14_Gas_Rx" SG_ 119 VehYawComp_W_Actl 1;
BA_ "U_P552_MY15_Gas_Rx" SG_ 119 VehYawComp_W_Actl 1;
BA_ "U_S550_MY15_Gas_Rx" SG_ 119 VehYawComp_W_Actl 1;
BA_ "U_C489_MY14_Gas_Rx" SG_ 119 VehYawComp_W_Actl 1;
BA_ "U_U502_MY15_Gas_Rx" SG_ 119 VehYawComp_W_Actl 1;
BA_ "U_CD43_MY16_Gas_Rx" SG_ 119 VehYawComp_W_Actl 1;
BA_ "U_CD4_MY14_Gas_Rx" SG_ 119 VehYawComp_W_Actl 1;
BA_ "U_UP375_MY15_Gas_Rx" SG_ 119 VehYawComp_W_Actl 1;
BA_ "U_UP375_MY15_Diesel_Rx" SG_ 119 VehYawComp_W_Actl 1;
BA_ "GenSigTimeoutTime_TCM" SG_ 119 VehYawComp_W_Actl 60;
BA_ "U_CD4_MY13_Diesel_Rx" SG_ 119 VehOverGnd_V_Est 1;
BA_ "U_CD4_MY13_Gas_Rx" SG_ 119 VehOverGnd_V_Est 1;
BA_ "U_CD4_MY13_Hev_Rx" SG_ 119 VehOverGnd_V_Est 1;
BA_ "U_CD4_MY13_Phev_Rx" SG_ 119 VehOverGnd_V_Est 1;
BA_ "U_CD42_MY14_Diesel_Rx" SG_ 119 VehOverGnd_V_Est 1;
BA_ "U_CD42_MY14_Gas_Rx" SG_ 119 VehOverGnd_V_Est 1;
BA_ "U_P552_MY15_Gas_Rx" SG_ 119 VehOverGnd_V_Est 1;
BA_ "U_S550_MY15_Gas_Rx" SG_ 119 VehOverGnd_V_Est 1;
BA_ "U_C489_MY14_Gas_Rx" SG_ 119 VehOverGnd_V_Est 1;
BA_ "U_U502_MY15_Gas_Rx" SG_ 119 VehOverGnd_V_Est 1;
BA_ "U_UP375_MY15_Gas_Rx" SG_ 119 VehOverGnd_V_Est 1;
BA_ "U_UP375_MY15_Diesel_Rx" SG_ 119 VehOverGnd_V_Est 1;
BA_ "U_CD43_MY16_Gas_Rx" SG_ 119 VehOverGnd_V_Est 1;
BA_ "U_CD4_MY14_Diesel_Rx" SG_ 119 VehOverGnd_V_Est 1;
BA_ "U_CD4_MY14_Gas_Rx" SG_ 119 VehOverGnd_V_Est 1;
BA_ "U_CD4_MY14_Hev_Rx" SG_ 119 VehOverGnd_V_Est 1;
BA_ "U_CD4_MY14_Phev_Rx" SG_ 119 VehOverGnd_V_Est 1;
BA_ "CrossOver_InfoCAN" SG_ 1045 VehYawLin_W_Rq 1;
BA_ "GenSigStartValue" SG_ 1045 VehYawLin_W_Rq 4094;
BA_ "U_CD4_MY13_Diesel_Rx" SG_ 1045 VehYawLin_W_Rq 1;
BA_ "U_CD42_MY15_Diesel_Rx" SG_ 1045 VehYawLin_W_Rq 1;
BA_ "U_U502_MY16_Gas_Rx" SG_ 1045 VehYawLin_W_Rq 1;
BA_ "U_CD43_MY16_Gas_Rx" SG_ 1045 VehYawLin_W_Rq 1;
BA_ "U_CD4_MY14_Diesel_Rx" SG_ 1045 VehYawLin_W_Rq 1;
BA_ "U_CD4_MY14_Gas_Rx" SG_ 1045 VehYawLin_W_Rq 1;
BA_ "U_CD4_MY17_Diesel_Rx" SG_ 1045 VehYawLin_W_Rq 1;
BA_ "U_CD4_MY17_Gas_Rx" SG_ 1045 VehYawLin_W_Rq 1;
BA_ "U_C489_MY17_Gas_Rx" SG_ 1045 VehYawLin_W_Rq 1;
BA_ "U_CD42_MY16_Diesel_Rx" SG_ 1045 VehYawLin_W_Rq 1;
BA_ "U_CD42_MY16_Gas_Rx" SG_ 1045 VehYawLin_W_Rq 1;
BA_ "U_CD43_MY17_Gas_Rx" SG_ 1045 VehYawLin_W_Rq 1;
BA_ "U_B515_MCA_MY17_Diesel_Rx" SG_ 1045 VehYawLin_W_Rq 1;
BA_ "CrossOver_InfoCAN" SG_ 1045 VehYawNonLin_W_Rq 1;
BA_ "GenSigStartValue" SG_ 1045 VehYawNonLin_W_Rq 4094;
BA_ "U_CD4_MY13_Diesel_Rx" SG_ 1045 VehYawNonLin_W_Rq 1;
BA_ "U_CD42_MY15_Diesel_Rx" SG_ 1045 VehYawNonLin_W_Rq 1;
BA_ "U_U502_MY16_Gas_Rx" SG_ 1045 VehYawNonLin_W_Rq 1;
BA_ "U_CD43_MY16_Gas_Rx" SG_ 1045 VehYawNonLin_W_Rq 1;
BA_ "U_CD4_MY14_Diesel_Rx" SG_ 1045 VehYawNonLin_W_Rq 1;
BA_ "U_CD4_MY14_Gas_Rx" SG_ 1045 VehYawNonLin_W_Rq 1;
BA_ "U_CD4_MY17_Diesel_Rx" SG_ 1045 VehYawNonLin_W_Rq 1;
BA_ "U_CD4_MY17_Gas_Rx" SG_ 1045 VehYawNonLin_W_Rq 1;
BA_ "U_C489_MY17_Gas_Rx" SG_ 1045 VehYawNonLin_W_Rq 1;
BA_ "U_CD42_MY16_Diesel_Rx" SG_ 1045 VehYawNonLin_W_Rq 1;
BA_ "U_CD42_MY16_Gas_Rx" SG_ 1045 VehYawNonLin_W_Rq 1;
BA_ "U_CD43_MY17_Gas_Rx" SG_ 1045 VehYawNonLin_W_Rq 1;
BA_ "U_B515_MCA_MY17_Diesel_Rx" SG_ 1045 VehYawNonLin_W_Rq 1;
BA_ "CrossOver_InfoCAN" SG_ 1045 VehVActlBrk_No_Cs 1;
BA_ "U_CD4_MY13_Diesel_Rx" SG_ 1045 VehVActlBrk_No_Cs 1;
BA_ "U_CD4_MY13_Gas_Rx" SG_ 1045 VehVActlBrk_No_Cs 1;
BA_ "U_CD4_MY13_Hev_Rx" SG_ 1045 VehVActlBrk_No_Cs 1;
BA_ "U_CD4_MY13_Phev_Rx" SG_ 1045 VehVActlBrk_No_Cs 1;
BA_ "U_CD42_MY14_Diesel_Rx" SG_ 1045 VehVActlBrk_No_Cs 1;
BA_ "U_CD42_MY14_Gas_Rx" SG_ 1045 VehVActlBrk_No_Cs 1;
BA_ "U_P552_MY15_Gas_Rx" SG_ 1045 VehVActlBrk_No_Cs 1;
BA_ "U_S550_MY15_Gas_Rx" SG_ 1045 VehVActlBrk_No_Cs 1;
BA_ "U_C489_MY14_Gas_Rx" SG_ 1045 VehVActlBrk_No_Cs 1;
BA_ "U_U502_MY15_Gas_Rx" SG_ 1045 VehVActlBrk_No_Cs 1;
BA_ "U_CD43_MY16_Gas_Rx" SG_ 1045 VehVActlBrk_No_Cs 1;
BA_ "U_CD4_MY14_Gas_Rx" SG_ 1045 VehVActlBrk_No_Cs 1;
BA_ "U_UP375_MY15_Gas_Rx" SG_ 1045 VehVActlBrk_No_Cs 1;
BA_ "U_UP375_MY15_Diesel_Rx" SG_ 1045 VehVActlBrk_No_Cs 1;
BA_ "U_CD4_MY14_Diesel_Rx" SG_ 1045 VehVActlBrk_No_Cs 1;
BA_ "U_CD4_MY14_Hev_Rx" SG_ 1045 VehVActlBrk_No_Cs 1;
BA_ "U_CD4_MY14_Phev_Rx" SG_ 1045 VehVActlBrk_No_Cs 1;
BA_ "CrossOver_InfoCAN" SG_ 1045 Veh_V_ActlBrk 1;
BA_ "U_CD4_MY13_Diesel_Rx" SG_ 1045 Veh_V_ActlBrk 1;
BA_ "U_CD4_MY13_Gas_Rx" SG_ 1045 Veh_V_ActlBrk 1;
BA_ "U_CD4_MY13_Hev_Rx" SG_ 1045 Veh_V_ActlBrk 1;
BA_ "U_CD4_MY13_Phev_Rx" SG_ 1045 Veh_V_ActlBrk 1;
BA_ "U_CD42_MY14_Diesel_Rx" SG_ 1045 Veh_V_ActlBrk 1;
BA_ "U_CD42_MY14_Gas_Rx" SG_ 1045 Veh_V_ActlBrk 1;
BA_ "U_P552_MY15_Gas_Rx" SG_ 1045 Veh_V_ActlBrk 1;
BA_ "U_S550_MY15_Gas_Rx" SG_ 1045 Veh_V_ActlBrk 1;
BA_ "U_C489_MY14_Gas_Rx" SG_ 1045 Veh_V_ActlBrk 1;
BA_ "U_U502_MY15_Gas_Rx" SG_ 1045 Veh_V_ActlBrk 1;
BA_ "U_UP375_MY15_Gas_Rx" SG_ 1045 Veh_V_ActlBrk 1;
BA_ "U_UP375_MY15_Diesel_Rx" SG_ 1045 Veh_V_ActlBrk 1;
BA_ "U_CD43_MY16_Gas_Rx" SG_ 1045 Veh_V_ActlBrk 1;
BA_ "U_CD4_MY14_Diesel_Rx" SG_ 1045 Veh_V_ActlBrk 1;
BA_ "U_CD4_MY14_Gas_Rx" SG_ 1045 Veh_V_ActlBrk 1;
BA_ "U_CD4_MY14_Hev_Rx" SG_ 1045 Veh_V_ActlBrk 1;
BA_ "U_CD4_MY14_Phev_Rx" SG_ 1045 Veh_V_ActlBrk 1;
BA_ "CrossOver_InfoCAN" SG_ 1045 VehVActlBrk_No_Cnt 1;
BA_ "U_CD4_MY13_Diesel_Rx" SG_ 1045 VehVActlBrk_No_Cnt 1;
BA_ "U_CD4_MY13_Gas_Rx" SG_ 1045 VehVActlBrk_No_Cnt 1;
BA_ "U_CD4_MY13_Hev_Rx" SG_ 1045 VehVActlBrk_No_Cnt 1;
BA_ "U_CD4_MY13_Phev_Rx" SG_ 1045 VehVActlBrk_No_Cnt 1;
BA_ "U_CD42_MY14_Diesel_Rx" SG_ 1045 VehVActlBrk_No_Cnt 1;
BA_ "U_CD42_MY14_Gas_Rx" SG_ 1045 VehVActlBrk_No_Cnt 1;
BA_ "U_P552_MY15_Gas_Rx" SG_ 1045 VehVActlBrk_No_Cnt 1;
BA_ "U_S550_MY15_Gas_Rx" SG_ 1045 VehVActlBrk_No_Cnt 1;
BA_ "U_C489_MY14_Gas_Rx" SG_ 1045 VehVActlBrk_No_Cnt 1;
BA_ "U_U502_MY15_Gas_Rx" SG_ 1045 VehVActlBrk_No_Cnt 1;
BA_ "U_CD43_MY16_Gas_Rx" SG_ 1045 VehVActlBrk_No_Cnt 1;
BA_ "U_CD4_MY14_Gas_Rx" SG_ 1045 VehVActlBrk_No_Cnt 1;
BA_ "U_UP375_MY15_Gas_Rx" SG_ 1045 VehVActlBrk_No_Cnt 1;
BA_ "U_UP375_MY15_Diesel_Rx" SG_ 1045 VehVActlBrk_No_Cnt 1;
BA_ "U_CD4_MY14_Diesel_Rx" SG_ 1045 VehVActlBrk_No_Cnt 1;
BA_ "U_CD4_MY14_Hev_Rx" SG_ 1045 VehVActlBrk_No_Cnt 1;
BA_ "U_CD4_MY14_Phev_Rx" SG_ 1045 VehVActlBrk_No_Cnt 1;
BA_ "CrossOver_InfoCAN" SG_ 1045 VehVActlBrk_D_Qf 1;
BA_ "U_CD4_MY13_Diesel_Rx" SG_ 1045 VehVActlBrk_D_Qf 1;
BA_ "U_CD4_MY13_Gas_Rx" SG_ 1045 VehVActlBrk_D_Qf 1;
BA_ "U_CD4_MY13_Hev_Rx" SG_ 1045 VehVActlBrk_D_Qf 1;
BA_ "U_CD4_MY13_Phev_Rx" SG_ 1045 VehVActlBrk_D_Qf 1;
BA_ "U_CD42_MY14_Diesel_Rx" SG_ 1045 VehVActlBrk_D_Qf 1;
BA_ "U_CD42_MY14_Gas_Rx" SG_ 1045 VehVActlBrk_D_Qf 1;
BA_ "U_P552_MY15_Gas_Rx" SG_ 1045 VehVActlBrk_D_Qf 1;
BA_ "U_S550_MY15_Gas_Rx" SG_ 1045 VehVActlBrk_D_Qf 1;
BA_ "U_C489_MY14_Gas_Rx" SG_ 1045 VehVActlBrk_D_Qf 1;
BA_ "U_U502_MY15_Gas_Rx" SG_ 1045 VehVActlBrk_D_Qf 1;
BA_ "U_CD43_MY16_Gas_Rx" SG_ 1045 VehVActlBrk_D_Qf 1;
BA_ "U_CD4_MY14_Gas_Rx" SG_ 1045 VehVActlBrk_D_Qf 1;
BA_ "U_UP375_MY15_Gas_Rx" SG_ 1045 VehVActlBrk_D_Qf 1;
BA_ "U_UP375_MY15_Diesel_Rx" SG_ 1045 VehVActlBrk_D_Qf 1;
BA_ "U_CD4_MY14_Diesel_Rx" SG_ 1045 VehVActlBrk_D_Qf 1;
BA_ "U_CD4_MY14_Hev_Rx" SG_ 1045 VehVActlBrk_D_Qf 1;
BA_ "U_CD4_MY14_Phev_Rx" SG_ 1045 VehVActlBrk_D_Qf 1;
BA_ "CrossOver_InfoCAN" SG_ 534 WhlRotatRr_No_Cnt 1;
BA_ "U_CD4_MY13_Diesel_Rx" SG_ 534 WhlRotatRr_No_Cnt 1;
BA_ "U_CD4_MY13_Gas_Rx" SG_ 534 WhlRotatRr_No_Cnt 1;
BA_ "U_CD4_MY13_Hev_Rx" SG_ 534 WhlRotatRr_No_Cnt 1;
BA_ "U_CD4_MY13_Phev_Rx" SG_ 534 WhlRotatRr_No_Cnt 1;
BA_ "U_CD42_MY14_Diesel_Rx" SG_ 534 WhlRotatRr_No_Cnt 1;
BA_ "U_CD42_MY14_Gas_Rx" SG_ 534 WhlRotatRr_No_Cnt 1;
BA_ "U_P552_MY15_Gas_Rx" SG_ 534 WhlRotatRr_No_Cnt 1;
BA_ "U_C489_MY14_Gas_Rx" SG_ 534 WhlRotatRr_No_Cnt 1;
BA_ "U_U502_MY15_Gas_Rx" SG_ 534 WhlRotatRr_No_Cnt 1;
BA_ "U_UP375_MY15_Gas_Rx" SG_ 534 WhlRotatRr_No_Cnt 1;
BA_ "U_UP375_MY15_Diesel_Rx" SG_ 534 WhlRotatRr_No_Cnt 1;
BA_ "U_CD43_MY16_Gas_Rx" SG_ 534 WhlRotatRr_No_Cnt 1;
BA_ "U_CD4_MY14_Diesel_Rx" SG_ 534 WhlRotatRr_No_Cnt 1;
BA_ "U_CD4_MY14_Gas_Rx" SG_ 534 WhlRotatRr_No_Cnt 1;
BA_ "U_CD4_MY14_Hev_Rx" SG_ 534 WhlRotatRr_No_Cnt 1;
BA_ "U_CD4_MY14_Phev_Rx" SG_ 534 WhlRotatRr_No_Cnt 1;
BA_ "CrossOver_InfoCAN" SG_ 534 WhlDirRr_D_Actl 1;
BA_ "CrossOver_InfoCAN" SG_ 534 WhlDirRl_D_Actl 1;
BA_ "CrossOver_InfoCAN" SG_ 534 WhlDirFr_D_Actl 1;
BA_ "U_P552_MY15_Gas_Rx" SG_ 534 WhlDirFr_D_Actl 1;
BA_ "CrossOver_InfoCAN" SG_ 534 WhlDirFl_D_Actl 1;
BA_ "U_P552_MY15_Gas_Rx" SG_ 534 WhlDirFl_D_Actl 1;
BA_ "CrossOver_InfoCAN" SG_ 534 WhlRotatRl_No_Cnt 1;
BA_ "U_CD4_MY13_Diesel_Rx" SG_ 534 WhlRotatRl_No_Cnt 1;
BA_ "U_CD4_MY13_Gas_Rx" SG_ 534 WhlRotatRl_No_Cnt 1;
BA_ "U_CD4_MY13_Hev_Rx" SG_ 534 WhlRotatRl_No_Cnt 1;
BA_ "U_CD4_MY13_Phev_Rx" SG_ 534 WhlRotatRl_No_Cnt 1;
BA_ "U_CD42_MY14_Diesel_Rx" SG_ 534 WhlRotatRl_No_Cnt 1;
BA_ "U_CD42_MY14_Gas_Rx" SG_ 534 WhlRotatRl_No_Cnt 1;
BA_ "U_P552_MY15_Gas_Rx" SG_ 534 WhlRotatRl_No_Cnt 1;
BA_ "U_C489_MY14_Gas_Rx" SG_ 534 WhlRotatRl_No_Cnt 1;
BA_ "U_U502_MY15_Gas_Rx" SG_ 534 WhlRotatRl_No_Cnt 1;
BA_ "U_UP375_MY15_Gas_Rx" SG_ 534 WhlRotatRl_No_Cnt 1;
BA_ "U_UP375_MY15_Diesel_Rx" SG_ 534 WhlRotatRl_No_Cnt 1;
BA_ "U_CD43_MY16_Gas_Rx" SG_ 534 WhlRotatRl_No_Cnt 1;
BA_ "U_CD4_MY14_Diesel_Rx" SG_ 534 WhlRotatRl_No_Cnt 1;
BA_ "U_CD4_MY14_Gas_Rx" SG_ 534 WhlRotatRl_No_Cnt 1;
BA_ "U_CD4_MY14_Hev_Rx" SG_ 534 WhlRotatRl_No_Cnt 1;
BA_ "U_CD4_MY14_Phev_Rx" SG_ 534 WhlRotatRl_No_Cnt 1;
BA_ "CrossOver_InfoCAN" SG_ 534 WhlRotatFr_No_Cnt 1;
BA_ "U_CD4_MY13_Diesel_Rx" SG_ 534 WhlRotatFr_No_Cnt 1;
BA_ "U_CD4_MY13_Gas_Rx" SG_ 534 WhlRotatFr_No_Cnt 1;
BA_ "U_CD4_MY13_Hev_Rx" SG_ 534 WhlRotatFr_No_Cnt 1;
BA_ "U_CD4_MY13_Phev_Rx" SG_ 534 WhlRotatFr_No_Cnt 1;
BA_ "U_CD42_MY14_Diesel_Rx" SG_ 534 WhlRotatFr_No_Cnt 1;
BA_ "U_CD42_MY14_Gas_Rx" SG_ 534 WhlRotatFr_No_Cnt 1;
BA_ "U_P552_MY15_Gas_Rx" SG_ 534 WhlRotatFr_No_Cnt 1;
BA_ "U_C489_MY14_Gas_Rx" SG_ 534 WhlRotatFr_No_Cnt 1;
BA_ "U_U502_MY15_Gas_Rx" SG_ 534 WhlRotatFr_No_Cnt 1;
BA_ "U_UP375_MY15_Gas_Rx" SG_ 534 WhlRotatFr_No_Cnt 1;
BA_ "U_UP375_MY15_Diesel_Rx" SG_ 534 WhlRotatFr_No_Cnt 1;
BA_ "U_CD43_MY16_Gas_Rx" SG_ 534 WhlRotatFr_No_Cnt 1;
BA_ "U_CD4_MY14_Diesel_Rx" SG_ 534 WhlRotatFr_No_Cnt 1;
BA_ "U_CD4_MY14_Gas_Rx" SG_ 534 WhlRotatFr_No_Cnt 1;
BA_ "U_CD4_MY14_Hev_Rx" SG_ 534 WhlRotatFr_No_Cnt 1;
BA_ "U_CD4_MY14_Phev_Rx" SG_ 534 WhlRotatFr_No_Cnt 1;
BA_ "CrossOver_InfoCAN" SG_ 534 WhlRotatFl_No_Cnt 1;
BA_ "U_CD4_MY13_Diesel_Rx" SG_ 534 WhlRotatFl_No_Cnt 1;
BA_ "U_CD4_MY13_Gas_Rx" SG_ 534 WhlRotatFl_No_Cnt 1;
BA_ "U_CD4_MY13_Hev_Rx" SG_ 534 WhlRotatFl_No_Cnt 1;
BA_ "U_CD4_MY13_Phev_Rx" SG_ 534 WhlRotatFl_No_Cnt 1;
BA_ "U_CD42_MY14_Diesel_Rx" SG_ 534 WhlRotatFl_No_Cnt 1;
BA_ "U_CD42_MY14_Gas_Rx" SG_ 534 WhlRotatFl_No_Cnt 1;
BA_ "U_P552_MY15_Gas_Rx" SG_ 534 WhlRotatFl_No_Cnt 1;
BA_ "U_C489_MY14_Gas_Rx" SG_ 534 WhlRotatFl_No_Cnt 1;
BA_ "U_U502_MY15_Gas_Rx" SG_ 534 WhlRotatFl_No_Cnt 1;
BA_ "U_UP375_MY15_Gas_Rx" SG_ 534 WhlRotatFl_No_Cnt 1;
BA_ "U_UP375_MY15_Diesel_Rx" SG_ 534 WhlRotatFl_No_Cnt 1;
BA_ "U_CD43_MY16_Gas_Rx" SG_ 534 WhlRotatFl_No_Cnt 1;
BA_ "U_CD4_MY14_Diesel_Rx" SG_ 534 WhlRotatFl_No_Cnt 1;
BA_ "U_CD4_MY14_Gas_Rx" SG_ 534 WhlRotatFl_No_Cnt 1;
BA_ "U_CD4_MY14_Hev_Rx" SG_ 534 WhlRotatFl_No_Cnt 1;
BA_ "U_CD4_MY14_Phev_Rx" SG_ 534 WhlRotatFl_No_Cnt 1;
BA_ "CrossOver_InfoCAN" SG_ 531 AccStopActv_B_ActlBrk 1;
BA_ "U_CD4_MY13_Diesel_Rx" SG_ 531 AccStopActv_B_ActlBrk 1;
BA_ "U_CD42_MY15_Diesel_Rx" SG_ 531 AccStopActv_B_ActlBrk 1;
BA_ "U_CD43_MY16_Gas_Rx" SG_ 531 AccStopActv_B_ActlBrk 1;
BA_ "U_CD4_MY14_Diesel_Rx" SG_ 531 AccStopActv_B_ActlBrk 1;
BA_ "U_CD4_MY14_Gas_Rx" SG_ 531 AccStopActv_B_ActlBrk 1;
BA_ "U_CD4_MY17_Diesel_Rx" SG_ 531 AccStopActv_B_ActlBrk 1;
BA_ "U_CD4_MY17_Gas_Rx" SG_ 531 AccStopActv_B_ActlBrk 1;
BA_ "U_CD42_MY16_Diesel_Rx" SG_ 531 AccStopActv_B_ActlBrk 1;
BA_ "U_CD43_MY17_Gas_Rx" SG_ 531 AccStopActv_B_ActlBrk 1;
BA_ "U_U55x_MY18_Gas_Rx" SG_ 531 AccStopActv_B_ActlBrk 1;
BA_ "CrossOver_InfoCAN" SG_ 531 TracCtlPtActv_B_Actl 1;
BA_ "U_CD4_MY13_Diesel_Rx" SG_ 531 TracCtlPtActv_B_Actl 1;
BA_ "U_CD4_MY13_Gas_Rx" SG_ 531 TracCtlPtActv_B_Actl 1;
BA_ "U_CD42_MY14_Diesel_Rx" SG_ 531 TracCtlPtActv_B_Actl 1;
BA_ "U_CD42_MY14_Gas_Rx" SG_ 531 TracCtlPtActv_B_Actl 1;
BA_ "U_P552_MY15_Gas_Rx" SG_ 531 TracCtlPtActv_B_Actl 1;
BA_ "U_C489_MY14_Gas_Rx" SG_ 531 TracCtlPtActv_B_Actl 1;
BA_ "U_U502_MY15_Gas_Rx" SG_ 531 TracCtlPtActv_B_Actl 1;
BA_ "U_UP375_MY15_Gas_Rx" SG_ 531 TracCtlPtActv_B_Actl 1;
BA_ "U_UP375_MY15_Diesel_Rx" SG_ 531 TracCtlPtActv_B_Actl 1;
BA_ "U_CD43_MY16_Gas_Rx" SG_ 531 TracCtlPtActv_B_Actl 1;
BA_ "U_CD4_MY14_Diesel_Rx" SG_ 531 TracCtlPtActv_B_Actl 1;
BA_ "U_CD4_MY14_Gas_Rx" SG_ 531 TracCtlPtActv_B_Actl 1;
BA_ "U_S550_MY15_Gas_Rx" SG_ 531 TracCtlPtActv_B_Actl 1;
BA_ "GenSigTimeoutTime_TCM" SG_ 531 TracCtlPtActv_B_Actl 60;
BA_ "CrossOver_InfoCAN" SG_ 531 StabCtlBrkActv_B_Actl 1;
BA_ "U_CD4_MY13_Diesel_Rx" SG_ 531 StabCtlBrkActv_B_Actl 1;
BA_ "U_CD4_MY13_Gas_Rx" SG_ 531 StabCtlBrkActv_B_Actl 1;
BA_ "U_CD4_MY13_Hev_Rx" SG_ 531 StabCtlBrkActv_B_Actl 1;
BA_ "U_CD4_MY13_Phev_Rx" SG_ 531 StabCtlBrkActv_B_Actl 1;
BA_ "U_CD42_MY14_Diesel_Rx" SG_ 531 StabCtlBrkActv_B_Actl 1;
BA_ "U_CD42_MY14_Gas_Rx" SG_ 531 StabCtlBrkActv_B_Actl 1;
BA_ "U_P552_MY15_Gas_Rx" SG_ 531 StabCtlBrkActv_B_Actl 1;
BA_ "U_S550_MY15_Gas_Rx" SG_ 531 StabCtlBrkActv_B_Actl 1;
BA_ "U_C489_MY14_Gas_Rx" SG_ 531 StabCtlBrkActv_B_Actl 1;
BA_ "U_U502_MY15_Gas_Rx" SG_ 531 StabCtlBrkActv_B_Actl 1;
BA_ "U_UP375_MY15_Gas_Rx" SG_ 531 StabCtlBrkActv_B_Actl 1;
BA_ "U_CD43_MY16_Gas_Rx" SG_ 531 StabCtlBrkActv_B_Actl 1;
BA_ "U_CD4_MY14_Gas_Rx" SG_ 531 StabCtlBrkActv_B_Actl 1;
BA_ "U_UP375_MY15_Diesel_Rx" SG_ 531 StabCtlBrkActv_B_Actl 1;
BA_ "U_CD4_MY14_Diesel_Rx" SG_ 531 StabCtlBrkActv_B_Actl 1;
BA_ "U_CD4_MY14_Hev_Rx" SG_ 531 StabCtlBrkActv_B_Actl 1;
BA_ "U_CD4_MY14_Phev_Rx" SG_ 531 StabCtlBrkActv_B_Actl 1;
BA_ "GenSigTimeoutTime_TCM" SG_ 531 StabCtlBrkActv_B_Actl 60;
BA_ "CrossOver_InfoCAN" SG_ 531 CmbbBrkPrchg_B_Actl 1;
BA_ "CrossOver_InfoCAN" SG_ 531 CmbbBrkDecel_B_Actl 1;
BA_ "CrossOver_InfoCAN" SG_ 531 CmbbBaSensInc_B_Actl 1;
BA_ "CrossOver_InfoCAN" SG_ 531 AccBrkWarm_B_Actl 1;
BA_ "CrossOver_InfoCAN" SG_ 531 AccBrkTotTqMn_B_Actl 1;
BA_ "CrossOver_InfoCAN" SG_ 531 AccBrkPrchgActv_B_Actl 1;
BA_ "CrossOver_InfoCAN" SG_ 531 AccBrkDis_B_Actl 1;
BA_ "CrossOver_InfoCAN" SG_ 531 AccBrkDeny_B_Actl 1;
BA_ "U_CD4_MY13_Gas_Rx" SG_ 531 AccBrkDeny_B_Actl 1;
BA_ "U_CD42_MY14_Gas_Rx" SG_ 531 AccBrkDeny_B_Actl 1;
BA_ "U_P552_MY15_Gas_Rx" SG_ 531 AccBrkDeny_B_Actl 1;
BA_ "U_S550_MY15_Gas_Rx" SG_ 531 AccBrkDeny_B_Actl 1;
BA_ "U_C489_MY14_Gas_Rx" SG_ 531 AccBrkDeny_B_Actl 1;
BA_ "U_U502_MY15_Gas_Rx" SG_ 531 AccBrkDeny_B_Actl 1;
BA_ "U_UP375_MY15_Gas_Rx" SG_ 531 AccBrkDeny_B_Actl 1;
BA_ "U_CD43_MY16_Gas_Rx" SG_ 531 AccBrkDeny_B_Actl 1;
BA_ "U_CD4_MY14_Gas_Rx" SG_ 531 AccBrkDeny_B_Actl 1;
BA_ "CrossOver_InfoCAN" SG_ 531 AccBrkActv_B_Actl 1;
BA_ "CrossOver_InfoCAN" SG_ 531 PrplDrgCtlActv_B_Actl 1;
BA_ "U_CD4_MY13_Gas_Rx" SG_ 531 PrplDrgCtlActv_B_Actl 1;
BA_ "U_CD42_MY14_Gas_Rx" SG_ 531 PrplDrgCtlActv_B_Actl 1;
BA_ "U_P552_MY15_Gas_Rx" SG_ 531 PrplDrgCtlActv_B_Actl 1;
BA_ "U_S550_MY15_Gas_Rx" SG_ 531 PrplDrgCtlActv_B_Actl 1;
BA_ "U_C489_MY14_Gas_Rx" SG_ 531 PrplDrgCtlActv_B_Actl 1;
BA_ "U_U502_MY15_Gas_Rx" SG_ 531 PrplDrgCtlActv_B_Actl 1;
BA_ "U_UP375_MY15_Gas_Rx" SG_ 531 PrplDrgCtlActv_B_Actl 1;
BA_ "U_CD43_MY16_Gas_Rx" SG_ 531 PrplDrgCtlActv_B_Actl 1;
BA_ "U_CD4_MY14_Gas_Rx" SG_ 531 PrplDrgCtlActv_B_Actl 1;
BA_ "GenSigTimeoutTime_TCM" SG_ 531 PrplDrgCtlActv_B_Actl 60;
BA_ "CrossOver_InfoCAN" SG_ 531 PrplWhlTot_Tq_RqMx 1;
BA_ "U_CD4_MY13_Gas_Rx" SG_ 531 PrplWhlTot_Tq_RqMx 1;
BA_ "U_CD42_MY14_Gas_Rx" SG_ 531 PrplWhlTot_Tq_RqMx 1;
BA_ "U_P552_MY15_Gas_Rx" SG_ 531 PrplWhlTot_Tq_RqMx 1;
BA_ "U_S550_MY15_Gas_Rx" SG_ 531 PrplWhlTot_Tq_RqMx 1;
BA_ "U_C489_MY14_Gas_Rx" SG_ 531 PrplWhlTot_Tq_RqMx 1;
BA_ "U_U502_MY15_Gas_Rx" SG_ 531 PrplWhlTot_Tq_RqMx 1;
BA_ "U_UP375_MY15_Gas_Rx" SG_ 531 PrplWhlTot_Tq_RqMx 1;
BA_ "U_CD43_MY16_Gas_Rx" SG_ 531 PrplWhlTot_Tq_RqMx 1;
BA_ "U_CD4_MY14_Gas_Rx" SG_ 531 PrplWhlTot_Tq_RqMx 1;
BA_ "CrossOver_InfoCAN" SG_ 531 AbsActv_B_Actl 1;
BA_ "U_CD4_MY13_Diesel_Rx" SG_ 531 AbsActv_B_Actl 1;
BA_ "U_CD4_MY13_Gas_Rx" SG_ 531 AbsActv_B_Actl 1;
BA_ "U_CD4_MY13_Hev_Rx" SG_ 531 AbsActv_B_Actl 1;
BA_ "U_CD4_MY13_Phev_Rx" SG_ 531 AbsActv_B_Actl 1;
BA_ "U_CD42_MY14_Diesel_Rx" SG_ 531 AbsActv_B_Actl 1;
BA_ "U_CD42_MY14_Gas_Rx" SG_ 531 AbsActv_B_Actl 1;
BA_ "U_P552_MY15_Gas_Rx" SG_ 531 AbsActv_B_Actl 1;
BA_ "U_S550_MY15_Gas_Rx" SG_ 531 AbsActv_B_Actl 1;
BA_ "U_C489_MY14_Gas_Rx" SG_ 531 AbsActv_B_Actl 1;
BA_ "U_U502_MY15_Gas_Rx" SG_ 531 AbsActv_B_Actl 1;
BA_ "U_UP375_MY15_Gas_Rx" SG_ 531 AbsActv_B_Actl 1;
BA_ "U_CD43_MY16_Gas_Rx" SG_ 531 AbsActv_B_Actl 1;
BA_ "U_CD4_MY14_Gas_Rx" SG_ 531 AbsActv_B_Actl 1;
BA_ "U_UP375_MY15_Diesel_Rx" SG_ 531 AbsActv_B_Actl 1;
BA_ "U_CD4_MY14_Diesel_Rx" SG_ 531 AbsActv_B_Actl 1;
BA_ "U_CD4_MY14_Hev_Rx" SG_ 531 AbsActv_B_Actl 1;
BA_ "U_CD4_MY14_Phev_Rx" SG_ 531 AbsActv_B_Actl 1;
BA_ "GenSigTimeoutTime_TCM" SG_ 531 AbsActv_B_Actl 60;
BA_ "CrossOver_InfoCAN" SG_ 531 CmbbBrkDis_B_Actl 1;
BA_ "U_CD4_MY13_Diesel_Rx" SG_ 531 CmbbDeny_B_ActlBrk 1;
BA_ "U_CD42_MY15_Diesel_Rx" SG_ 531 CmbbDeny_B_ActlBrk 1;
BA_ "U_UP375_MY15_Diesel_Rx" SG_ 531 CmbbDeny_B_ActlBrk 1;
BA_ "U_CD43_MY16_Gas_Rx" SG_ 531 CmbbDeny_B_ActlBrk 1;
BA_ "U_CD4_MY14_Diesel_Rx" SG_ 531 CmbbDeny_B_ActlBrk 1;
BA_ "U_CD4_MY17_Diesel_Rx" SG_ 531 CmbbDeny_B_ActlBrk 1;
BA_ "U_CD4_MY17_Gas_Rx" SG_ 531 CmbbDeny_B_ActlBrk 1;
BA_ "U_CD4_MY17_Hev_Rx" SG_ 531 CmbbDeny_B_ActlBrk 1;
BA_ "U_CD4_MY17_Phev_Rx" SG_ 531 CmbbDeny_B_ActlBrk 1;
BA_ "U_P558_MY17_Diesel_Rx" SG_ 531 CmbbDeny_B_ActlBrk 1;
BA_ "U_V36X_MY16_5_Diesel_Rx" SG_ 531 CmbbDeny_B_ActlBrk 1;
BA_ "U_CD42_MY16_Diesel_Rx" SG_ 531 CmbbDeny_B_ActlBrk 1;
BA_ "U_CD42_MY16_Gas_Rx" SG_ 531 CmbbDeny_B_ActlBrk 1;
BA_ "U_CD43_MY17_Gas_Rx" SG_ 531 CmbbDeny_B_ActlBrk 1;
BA_ "U_U55x_MY18_Gas_Rx" SG_ 531 CmbbDeny_B_ActlBrk 1;
BA_ "GenSigTimeoutTime_ECM" SG_ 531 CmbbDeny_B_ActlBrk 1000;
BA_ "GenSigTimeoutTime_PCM" SG_ 531 CmbbDeny_B_ActlBrk 1000;
BA_ "GenSigTimeoutTime_ECM_HEV" SG_ 531 CmbbDeny_B_ActlBrk 1000;
BA_ "CrossOver_InfoCAN" SG_ 531 CmbbDeny_B_ActlBrk 1;
BA_ "CrossOver_InfoCAN" SG_ 531 CcDis_B_Cmd 1;
BA_ "U_CD4_MY13_Gas_Rx" SG_ 531 CcDis_B_Cmd 1;
BA_ "U_CD42_MY14_Gas_Rx" SG_ 531 CcDis_B_Cmd 1;
BA_ "U_P552_MY15_Gas_Rx" SG_ 531 CcDis_B_Cmd 1;
BA_ "U_S550_MY15_Gas_Rx" SG_ 531 CcDis_B_Cmd 1;
BA_ "U_C489_MY14_Gas_Rx" SG_ 531 CcDis_B_Cmd 1;
BA_ "U_U502_MY15_Gas_Rx" SG_ 531 CcDis_B_Cmd 1;
BA_ "U_UP375_MY15_Gas_Rx" SG_ 531 CcDis_B_Cmd 1;
BA_ "U_CD43_MY16_Gas_Rx" SG_ 531 CcDis_B_Cmd 1;
BA_ "U_CD4_MY14_Gas_Rx" SG_ 531 CcDis_B_Cmd 1;
BA_ "CrossOver_InfoCAN" SG_ 531 VehLongOvrGnd_A_Est 1;
BA_ "GenSigStartValue" SG_ 531 VehLongOvrGnd_A_Est 511;
BA_ "GenSigStartValue" SG_ 531 PrkBrkStatus 7;
BA_ "CrossOver_InfoCAN" SG_ 531 PrkBrkStatus 1;
BA_ "U_CD4_MY13_Diesel_Rx" SG_ 531 PrkBrkStatus 1;
BA_ "U_CD4_MY13_Gas_Rx" SG_ 531 PrkBrkStatus 1;
BA_ "U_CD4_MY13_Hev_Rx" SG_ 531 PrkBrkStatus 1;
BA_ "U_CD4_MY13_Phev_Rx" SG_ 531 PrkBrkStatus 1;
BA_ "U_CD42_MY14_Diesel_Rx" SG_ 531 PrkBrkStatus 1;
BA_ "U_CD42_MY14_Gas_Rx" SG_ 531 PrkBrkStatus 1;
BA_ "U_P552_MY15_Gas_Rx" SG_ 531 PrkBrkStatus 1;
BA_ "U_C489_MY14_Gas_Rx" SG_ 531 PrkBrkStatus 1;
BA_ "U_U502_MY15_Gas_Rx" SG_ 531 PrkBrkStatus 1;
BA_ "U_CD43_MY16_Gas_Rx" SG_ 531 PrkBrkStatus 1;
BA_ "U_CD4_MY14_Gas_Rx" SG_ 531 PrkBrkStatus 1;
BA_ "U_S550_MY15_Gas_Rx" SG_ 531 PrkBrkStatus 1;
BA_ "U_UP375_MY15_Gas_Rx" SG_ 531 PrkBrkStatus 1;
BA_ "U_UP375_MY15_Diesel_Rx" SG_ 531 PrkBrkStatus 1;
BA_ "U_CD4_MY14_Diesel_Rx" SG_ 531 PrkBrkStatus 1;
BA_ "U_CD4_MY14_Hev_Rx" SG_ 531 PrkBrkStatus 1;
BA_ "U_CD4_MY14_Phev_Rx" SG_ 531 PrkBrkStatus 1;
BA_ "U_CD4_MY13_Diesel_Rx" SG_ 535 WhlRr_W_Meas 1;
BA_ "U_CD4_MY13_Gas_Rx" SG_ 535 WhlRr_W_Meas 1;
BA_ "U_CD4_MY13_Hev_Rx" SG_ 535 WhlRr_W_Meas 1;
BA_ "U_CD4_MY13_Phev_Rx" SG_ 535 WhlRr_W_Meas 1;
BA_ "U_CD42_MY14_Diesel_Rx" SG_ 535 WhlRr_W_Meas 1;
BA_ "U_CD42_MY14_Gas_Rx" SG_ 535 WhlRr_W_Meas 1;
BA_ "U_P552_MY15_Gas_Rx" SG_ 535 WhlRr_W_Meas 1;
BA_ "U_S550_MY15_Gas_Rx" SG_ 535 WhlRr_W_Meas 1;
BA_ "U_C489_MY14_Gas_Rx" SG_ 535 WhlRr_W_Meas 1;
BA_ "U_U502_MY15_Gas_Rx" SG_ 535 WhlRr_W_Meas 1;
BA_ "U_CD43_MY16_Gas_Rx" SG_ 535 WhlRr_W_Meas 1;
BA_ "U_CD4_MY14_Gas_Rx" SG_ 535 WhlRr_W_Meas 1;
BA_ "U_UP375_MY15_Gas_Rx" SG_ 535 WhlRr_W_Meas 1;
BA_ "U_UP375_MY15_Diesel_Rx" SG_ 535 WhlRr_W_Meas 1;
BA_ "U_CD4_MY14_Diesel_Rx" SG_ 535 WhlRr_W_Meas 1;
BA_ "U_CD4_MY14_Hev_Rx" SG_ 535 WhlRr_W_Meas 1;
BA_ "U_CD4_MY14_Phev_Rx" SG_ 535 WhlRr_W_Meas 1;
BA_ "GenSigTimeoutTime_TCM" SG_ 535 WhlRr_W_Meas 30;
BA_ "U_CD4_MY13_Diesel_Rx" SG_ 535 WhlRl_W_Meas 1;
BA_ "U_CD4_MY13_Gas_Rx" SG_ 535 WhlRl_W_Meas 1;
BA_ "U_CD4_MY13_Hev_Rx" SG_ 535 WhlRl_W_Meas 1;
BA_ "U_CD4_MY13_Phev_Rx" SG_ 535 WhlRl_W_Meas 1;
BA_ "U_CD42_MY14_Diesel_Rx" SG_ 535 WhlRl_W_Meas 1;
BA_ "U_CD42_MY14_Gas_Rx" SG_ 535 WhlRl_W_Meas 1;
BA_ "U_P552_MY15_Gas_Rx" SG_ 535 WhlRl_W_Meas 1;
BA_ "U_C489_MY14_Gas_Rx" SG_ 535 WhlRl_W_Meas 1;
BA_ "U_U502_MY15_Gas_Rx" SG_ 535 WhlRl_W_Meas 1;
BA_ "U_UP375_MY15_Gas_Rx" SG_ 535 WhlRl_W_Meas 1;
BA_ "U_CD43_MY16_Gas_Rx" SG_ 535 WhlRl_W_Meas 1;
BA_ "U_CD4_MY14_Gas_Rx" SG_ 535 WhlRl_W_Meas 1;
BA_ "U_UP375_MY15_Diesel_Rx" SG_ 535 WhlRl_W_Meas 1;
BA_ "U_CD4_MY14_Diesel_Rx" SG_ 535 WhlRl_W_Meas 1;
BA_ "U_CD4_MY14_Hev_Rx" SG_ 535 WhlRl_W_Meas 1;
BA_ "U_CD4_MY14_Phev_Rx" SG_ 535 WhlRl_W_Meas 1;
BA_ "GenSigTimeoutTime_TCM" SG_ 535 WhlRl_W_Meas 30;
BA_ "U_CD4_MY13_Diesel_Rx" SG_ 535 WhlFr_W_Meas 1;
BA_ "U_CD4_MY13_Gas_Rx" SG_ 535 WhlFr_W_Meas 1;
BA_ "U_CD4_MY13_Hev_Rx" SG_ 535 WhlFr_W_Meas 1;
BA_ "U_CD4_MY13_Phev_Rx" SG_ 535 WhlFr_W_Meas 1;
BA_ "U_CD42_MY14_Diesel_Rx" SG_ 535 WhlFr_W_Meas 1;
BA_ "U_CD42_MY14_Gas_Rx" SG_ 535 WhlFr_W_Meas 1;
BA_ "U_P552_MY15_Gas_Rx" SG_ 535 WhlFr_W_Meas 1;
BA_ "U_C489_MY14_Gas_Rx" SG_ 535 WhlFr_W_Meas 1;
BA_ "U_U502_MY15_Gas_Rx" SG_ 535 WhlFr_W_Meas 1;
BA_ "U_UP375_MY15_Gas_Rx" SG_ 535 WhlFr_W_Meas 1;
BA_ "U_CD43_MY16_Gas_Rx" SG_ 535 WhlFr_W_Meas 1;
BA_ "U_CD4_MY14_Gas_Rx" SG_ 535 WhlFr_W_Meas 1;
BA_ "U_UP375_MY15_Diesel_Rx" SG_ 535 WhlFr_W_Meas 1;
BA_ "U_CD4_MY14_Diesel_Rx" SG_ 535 WhlFr_W_Meas 1;
BA_ "U_CD4_MY14_Hev_Rx" SG_ 535 WhlFr_W_Meas 1;
BA_ "U_CD4_MY14_Phev_Rx" SG_ 535 WhlFr_W_Meas 1;
BA_ "GenSigTimeoutTime_TCM" SG_ 535 WhlFr_W_Meas 30;
BA_ "U_CD4_MY13_Diesel_Rx" SG_ 535 WhlFl_W_Meas 1;
BA_ "U_CD4_MY13_Gas_Rx" SG_ 535 WhlFl_W_Meas 1;
BA_ "U_CD4_MY13_Hev_Rx" SG_ 535 WhlFl_W_Meas 1;
BA_ "U_CD4_MY13_Phev_Rx" SG_ 535 WhlFl_W_Meas 1;
BA_ "U_CD42_MY14_Diesel_Rx" SG_ 535 WhlFl_W_Meas 1;
BA_ "U_CD42_MY14_Gas_Rx" SG_ 535 WhlFl_W_Meas 1;
BA_ "U_P552_MY15_Gas_Rx" SG_ 535 WhlFl_W_Meas 1;
BA_ "U_C489_MY14_Gas_Rx" SG_ 535 WhlFl_W_Meas 1;
BA_ "U_U502_MY15_Gas_Rx" SG_ 535 WhlFl_W_Meas 1;
BA_ "U_UP375_MY15_Gas_Rx" SG_ 535 WhlFl_W_Meas 1;
BA_ "U_CD43_MY16_Gas_Rx" SG_ 535 WhlFl_W_Meas 1;
BA_ "U_CD4_MY14_Gas_Rx" SG_ 535 WhlFl_W_Meas 1;
BA_ "U_UP375_MY15_Diesel_Rx" SG_ 535 WhlFl_W_Meas 1;
BA_ "U_CD4_MY14_Diesel_Rx" SG_ 535 WhlFl_W_Meas 1;
BA_ "U_CD4_MY14_Hev_Rx" SG_ 535 WhlFl_W_Meas 1;
BA_ "U_CD4_MY14_Phev_Rx" SG_ 535 WhlFl_W_Meas 1;
BA_ "GenSigTimeoutTime_TCM" SG_ 535 WhlFl_W_Meas 30;
BA_ "U_V36X_MY18_5_Hev_Tx" SG_ 1409 BCM_GWOnBoardTester 1;
BA_ "U_V36X_MY18_5_Gas_Tx" SG_ 1409 BCM_GWOnBoardTester 1;
BA_ "U_V363E_N_MY19_5_20_Diesel_Tx" SG_ 1409 BCM_GWOnBoardTester 1;
BA_ "U_V363E_N_MY19_5_20_Gas_Tx" SG_ 1409 BCM_GWOnBoardTester 1;
BA_ "U_V36X_MY19_5_Diesel_Tx" SG_ 1409 BCM_GWOnBoardTester 1;
BA_ "U_P552_MY18_5_Diesel_Tx" SG_ 1409 BCM_GWOnBoardTester 1;
BA_ "U_P552_MY18_5_Gas_Tx" SG_ 1409 BCM_GWOnBoardTester 1;
BA_ "U_V36X_MY18_5_Diesel_Tx" SG_ 1409 BCM_GWOnBoardTester 1;
BA_ "U_U55x_MY18_Gas_Tx" SG_ 1409 BCM_GWOnBoardTester 1;
BA_ "U_V408_MY18_Diesel_Rx" SG_ 1409 BCM_GWOnBoardTester 1;
BA_ "U_V408_MY18_Gas_Rx" SG_ 1409 BCM_GWOnBoardTester 1;
BA_ "U_U55x_MY18_Gas_Rx" SG_ 1409 BCM_GWOnBoardTester 1;
BA_ "U_P552_MY18_Gas_Rx" SG_ 1409 BCM_GWOnBoardTester 1;
BA_ "ContentDependant" SG_ 1409 BCM_GWOnBoardTester 1;
BA_ "GenSigStartValue" SG_ 1409 BCM_GWOnBoardTester 255;
BA_ "U_V36X_MY18_5_Hev_Tx" SG_ 1409 BCM_GWNMProxy 1;
BA_ "U_V36X_MY18_5_Gas_Tx" SG_ 1409 BCM_GWNMProxy 1;
BA_ "U_V363E_N_MY19_5_20_Diesel_Tx" SG_ 1409 BCM_GWNMProxy 1;
BA_ "U_V363E_N_MY19_5_20_Gas_Tx" SG_ 1409 BCM_GWNMProxy 1;
BA_ "U_V36X_MY19_5_Diesel_Tx" SG_ 1409 BCM_GWNMProxy 1;
BA_ "U_P552_MY18_5_Diesel_Tx" SG_ 1409 BCM_GWNMProxy 1;
BA_ "U_P552_MY18_5_Gas_Tx" SG_ 1409 BCM_GWNMProxy 1;
BA_ "U_V36X_MY18_5_Diesel_Tx" SG_ 1409 BCM_GWNMProxy 1;
BA_ "U_U55x_MY18_Gas_Tx" SG_ 1409 BCM_GWNMProxy 1;
BA_ "U_V408_MY18_Diesel_Rx" SG_ 1409 BCM_GWNMProxy 1;
BA_ "U_V408_MY18_Gas_Rx" SG_ 1409 BCM_GWNMProxy 1;
BA_ "U_U55x_MY18_Gas_Rx" SG_ 1409 BCM_GWNMProxy 1;
BA_ "U_P552_MY18_Gas_Rx" SG_ 1409 BCM_GWNMProxy 1;
BA_ "ContentDependant" SG_ 1409 BCM_GWNMProxy 1;
BA_ "GenSigStartValue" SG_ 1409 BCM_GWNMProxy 255;
BA_ "U_V36X_MY18_5_Hev_Tx" SG_ 1409 BCM_AutoSarNMReserved4 1;
BA_ "U_V36X_MY18_5_Gas_Tx" SG_ 1409 BCM_AutoSarNMReserved4 1;
BA_ "U_V363E_N_MY19_5_20_Diesel_Tx" SG_ 1409 BCM_AutoSarNMReserved4 1;
BA_ "U_V363E_N_MY19_5_20_Gas_Tx" SG_ 1409 BCM_AutoSarNMReserved4 1;
BA_ "U_V36X_MY19_5_Diesel_Tx" SG_ 1409 BCM_AutoSarNMReserved4 1;
BA_ "U_P552_MY18_5_Diesel_Tx" SG_ 1409 BCM_AutoSarNMReserved4 1;
BA_ "U_P552_MY18_5_Gas_Tx" SG_ 1409 BCM_AutoSarNMReserved4 1;
BA_ "U_V36X_MY18_5_Diesel_Tx" SG_ 1409 BCM_AutoSarNMReserved4 1;
BA_ "U_U55x_MY18_Gas_Tx" SG_ 1409 BCM_AutoSarNMReserved4 1;
BA_ "U_V408_MY18_Diesel_Rx" SG_ 1409 BCM_AutoSarNMReserved4 1;
BA_ "U_V408_MY18_Gas_Rx" SG_ 1409 BCM_AutoSarNMReserved4 1;
BA_ "U_U55x_MY18_Gas_Rx" SG_ 1409 BCM_AutoSarNMReserved4 1;
BA_ "U_P552_MY18_Gas_Rx" SG_ 1409 BCM_AutoSarNMReserved4 1;
BA_ "ContentDependant" SG_ 1409 BCM_AutoSarNMReserved4 1;
BA_ "GenSigStartValue" SG_ 1409 BCM_AutoSarNMReserved4 255;
BA_ "U_V36X_MY18_5_Hev_Tx" SG_ 1409 BCM_AutoSarNMReserved3 1;
BA_ "U_V36X_MY18_5_Gas_Tx" SG_ 1409 BCM_AutoSarNMReserved3 1;
BA_ "U_V363E_N_MY19_5_20_Diesel_Tx" SG_ 1409 BCM_AutoSarNMReserved3 1;
BA_ "U_V363E_N_MY19_5_20_Gas_Tx" SG_ 1409 BCM_AutoSarNMReserved3 1;
BA_ "U_V36X_MY19_5_Diesel_Tx" SG_ 1409 BCM_AutoSarNMReserved3 1;
BA_ "U_P552_MY18_5_Diesel_Tx" SG_ 1409 BCM_AutoSarNMReserved3 1;
BA_ "U_P552_MY18_5_Gas_Tx" SG_ 1409 BCM_AutoSarNMReserved3 1;
BA_ "U_V36X_MY18_5_Diesel_Tx" SG_ 1409 BCM_AutoSarNMReserved3 1;
BA_ "U_U55x_MY18_Gas_Tx" SG_ 1409 BCM_AutoSarNMReserved3 1;
BA_ "U_V408_MY18_Diesel_Rx" SG_ 1409 BCM_AutoSarNMReserved3 1;
BA_ "U_V408_MY18_Gas_Rx" SG_ 1409 BCM_AutoSarNMReserved3 1;
BA_ "U_U55x_MY18_Gas_Rx" SG_ 1409 BCM_AutoSarNMReserved3 1;
BA_ "U_P552_MY18_Gas_Rx" SG_ 1409 BCM_AutoSarNMReserved3 1;
BA_ "ContentDependant" SG_ 1409 BCM_AutoSarNMReserved3 1;
BA_ "GenSigStartValue" SG_ 1409 BCM_AutoSarNMReserved3 255;
BA_ "U_V36X_MY18_5_Hev_Tx" SG_ 1409 BCM_AutoSarNMReserved2 1;
BA_ "U_V36X_MY18_5_Gas_Tx" SG_ 1409 BCM_AutoSarNMReserved2 1;
BA_ "U_V363E_N_MY19_5_20_Diesel_Tx" SG_ 1409 BCM_AutoSarNMReserved2 1;
BA_ "U_V363E_N_MY19_5_20_Gas_Tx" SG_ 1409 BCM_AutoSarNMReserved2 1;
BA_ "U_V36X_MY19_5_Diesel_Tx" SG_ 1409 BCM_AutoSarNMReserved2 1;
BA_ "U_P552_MY18_5_Diesel_Tx" SG_ 1409 BCM_AutoSarNMReserved2 1;
BA_ "U_P552_MY18_5_Gas_Tx" SG_ 1409 BCM_AutoSarNMReserved2 1;
BA_ "U_V36X_MY18_5_Diesel_Tx" SG_ 1409 BCM_AutoSarNMReserved2 1;
BA_ "U_U55x_MY18_Gas_Tx" SG_ 1409 BCM_AutoSarNMReserved2 1;
BA_ "U_V408_MY18_Diesel_Rx" SG_ 1409 BCM_AutoSarNMReserved2 1;
BA_ "U_V408_MY18_Gas_Rx" SG_ 1409 BCM_AutoSarNMReserved2 1;
BA_ "U_U55x_MY18_Gas_Rx" SG_ 1409 BCM_AutoSarNMReserved2 1;
BA_ "U_P552_MY18_Gas_Rx" SG_ 1409 BCM_AutoSarNMReserved2 1;
BA_ "ContentDependant" SG_ 1409 BCM_AutoSarNMReserved2 1;
BA_ "GenSigStartValue" SG_ 1409 BCM_AutoSarNMReserved2 255;
BA_ "U_V36X_MY18_5_Hev_Tx" SG_ 1409 BCM_AutoSarNMReserved1 1;
BA_ "U_V36X_MY18_5_Gas_Tx" SG_ 1409 BCM_AutoSarNMReserved1 1;
BA_ "U_V363E_N_MY19_5_20_Diesel_Tx" SG_ 1409 BCM_AutoSarNMReserved1 1;
BA_ "U_V363E_N_MY19_5_20_Gas_Tx" SG_ 1409 BCM_AutoSarNMReserved1 1;
BA_ "U_V36X_MY19_5_Diesel_Tx" SG_ 1409 BCM_AutoSarNMReserved1 1;
BA_ "U_P552_MY18_5_Diesel_Tx" SG_ 1409 BCM_AutoSarNMReserved1 1;
BA_ "U_P552_MY18_5_Gas_Tx" SG_ 1409 BCM_AutoSarNMReserved1 1;
BA_ "U_V36X_MY18_5_Diesel_Tx" SG_ 1409 BCM_AutoSarNMReserved1 1;
BA_ "U_U55x_MY18_Gas_Tx" SG_ 1409 BCM_AutoSarNMReserved1 1;
BA_ "U_V408_MY18_Diesel_Rx" SG_ 1409 BCM_AutoSarNMReserved1 1;
BA_ "U_V408_MY18_Gas_Rx" SG_ 1409 BCM_AutoSarNMReserved1 1;
BA_ "U_U55x_MY18_Gas_Rx" SG_ 1409 BCM_AutoSarNMReserved1 1;
BA_ "U_P552_MY18_Gas_Rx" SG_ 1409 BCM_AutoSarNMReserved1 1;
BA_ "ContentDependant" SG_ 1409 BCM_AutoSarNMReserved1 1;
BA_ "GenSigStartValue" SG_ 1409 BCM_AutoSarNMReserved1 255;
BA_ "U_V36X_MY18_5_Hev_Tx" SG_ 1409 BCM_AutoSarNMNodeId 1;
BA_ "U_V36X_MY18_5_Gas_Tx" SG_ 1409 BCM_AutoSarNMNodeId 1;
BA_ "U_V363E_N_MY19_5_20_Diesel_Tx" SG_ 1409 BCM_AutoSarNMNodeId 1;
BA_ "U_V363E_N_MY19_5_20_Gas_Tx" SG_ 1409 BCM_AutoSarNMNodeId 1;
BA_ "U_V36X_MY19_5_Diesel_Tx" SG_ 1409 BCM_AutoSarNMNodeId 1;
BA_ "U_P552_MY18_5_Diesel_Tx" SG_ 1409 BCM_AutoSarNMNodeId 1;
BA_ "U_P552_MY18_5_Gas_Tx" SG_ 1409 BCM_AutoSarNMNodeId 1;
BA_ "U_V36X_MY18_5_Diesel_Tx" SG_ 1409 BCM_AutoSarNMNodeId 1;
BA_ "U_U55x_MY18_Gas_Tx" SG_ 1409 BCM_AutoSarNMNodeId 1;
BA_ "U_V408_MY18_Diesel_Rx" SG_ 1409 BCM_AutoSarNMNodeId 1;
BA_ "U_V408_MY18_Gas_Rx" SG_ 1409 BCM_AutoSarNMNodeId 1;
BA_ "U_U55x_MY18_Gas_Rx" SG_ 1409 BCM_AutoSarNMNodeId 1;
BA_ "U_P552_MY18_Gas_Rx" SG_ 1409 BCM_AutoSarNMNodeId 1;
BA_ "ContentDependant" SG_ 1409 BCM_AutoSarNMNodeId 1;
BA_ "GenSigStartValue" SG_ 1409 BCM_AutoSarNMNodeId 81;
BA_ "U_V36X_MY18_5_Hev_Tx" SG_ 1409 BCM_AutoSarNMControl 1;
BA_ "U_V36X_MY18_5_Gas_Tx" SG_ 1409 BCM_AutoSarNMControl 1;
BA_ "U_V363E_N_MY19_5_20_Diesel_Tx" SG_ 1409 BCM_AutoSarNMControl 1;
BA_ "U_V363E_N_MY19_5_20_Gas_Tx" SG_ 1409 BCM_AutoSarNMControl 1;
BA_ "U_V36X_MY19_5_Diesel_Tx" SG_ 1409 BCM_AutoSarNMControl 1;
BA_ "U_P552_MY18_5_Diesel_Tx" SG_ 1409 BCM_AutoSarNMControl 1;
BA_ "U_P552_MY18_5_Gas_Tx" SG_ 1409 BCM_AutoSarNMControl 1;
BA_ "U_V36X_MY18_5_Diesel_Tx" SG_ 1409 BCM_AutoSarNMControl 1;
BA_ "U_V408_MY18_Diesel_Tx" SG_ 1409 BCM_AutoSarNMControl 1;
BA_ "U_U55x_MY18_Gas_Tx" SG_ 1409 BCM_AutoSarNMControl 1;
BA_ "U_V408_MY18_Diesel_Rx" SG_ 1409 BCM_AutoSarNMControl 1;
BA_ "U_V408_MY18_Gas_Rx" SG_ 1409 BCM_AutoSarNMControl 1;
BA_ "U_U55x_MY18_Gas_Rx" SG_ 1409 BCM_AutoSarNMControl 1;
BA_ "U_P552_MY18_Gas_Rx" SG_ 1409 BCM_AutoSarNMControl 1;
BA_ "ContentDependant" SG_ 1409 BCM_AutoSarNMControl 1;
BA_ "GenSigSendType" SG_ 1846 TesterPhysicalReqPAM 3;
BA_ "U_CD4_MY13_Diesel_Rx" SG_ 1846 TesterPhysicalReqPAM 1;
BA_ "U_CD4_MY13_Gas_Rx" SG_ 1846 TesterPhysicalReqPAM 1;
BA_ "U_CD4_MY13_Hev_Rx" SG_ 1846 TesterPhysicalReqPAM 1;
BA_ "U_CD4_MY13_Phev_Rx" SG_ 1846 TesterPhysicalReqPAM 1;
BA_ "U_CD42_MY14_Diesel_Rx" SG_ 1846 TesterPhysicalReqPAM 1;
BA_ "U_CD42_MY14_Gas_Rx" SG_ 1846 TesterPhysicalReqPAM 1;
BA_ "U_P552_MY15_Gas_Rx" SG_ 1846 TesterPhysicalReqPAM 1;
BA_ "U_S550_MY15_Gas_Rx" SG_ 1846 TesterPhysicalReqPAM 1;
BA_ "U_C489_MY14_Gas_Rx" SG_ 1846 TesterPhysicalReqPAM 1;
BA_ "U_U502_MY15_Gas_Rx" SG_ 1846 TesterPhysicalReqPAM 1;
BA_ "U_UP375_MY15_Gas_Rx" SG_ 1846 TesterPhysicalReqPAM 1;
BA_ "U_UP375_MY15_Diesel_Rx" SG_ 1846 TesterPhysicalReqPAM 1;
BA_ "U_CD43_MY16_Gas_Rx" SG_ 1846 TesterPhysicalReqPAM 1;
BA_ "U_CD4_MY14_Diesel_Rx" SG_ 1846 TesterPhysicalReqPAM 1;
BA_ "U_CD4_MY14_Gas_Rx" SG_ 1846 TesterPhysicalReqPAM 1;
BA_ "U_CD4_MY14_Hev_Rx" SG_ 1846 TesterPhysicalReqPAM 1;
BA_ "U_CD4_MY14_Phev_Rx" SG_ 1846 TesterPhysicalReqPAM 1;
BA_ "U_CD4_MY13_Diesel_Tx" SG_ 1846 TesterPhysicalReqPAM 1;
BA_ "U_CD4_MY13_Gas_Tx" SG_ 1846 TesterPhysicalReqPAM 1;
BA_ "U_CD4_MY13_Hev_Tx" SG_ 1846 TesterPhysicalReqPAM 1;
BA_ "U_CD4_MY13_Phev_Tx" SG_ 1846 TesterPhysicalReqPAM 1;
BA_ "U_CD42_MY14_Diesel_Tx" SG_ 1846 TesterPhysicalReqPAM 1;
BA_ "U_CD42_MY14_Gas_Tx" SG_ 1846 TesterPhysicalReqPAM 1;
BA_ "U_P552_MY15_Gas_Tx" SG_ 1846 TesterPhysicalReqPAM 1;
BA_ "U_S550_MY15_Gas_Tx" SG_ 1846 TesterPhysicalReqPAM 1;
BA_ "U_C489_MY14_Gas_Tx" SG_ 1846 TesterPhysicalReqPAM 1;
BA_ "GenSigSendType" SG_ 1854 TesterPhysicalResPAM 3;
BA_ "U_CD4_MY13_Diesel_Rx" SG_ 1854 TesterPhysicalResPAM 1;
BA_ "U_CD4_MY13_Gas_Rx" SG_ 1854 TesterPhysicalResPAM 1;
BA_ "U_CD4_MY13_Hev_Rx" SG_ 1854 TesterPhysicalResPAM 1;
BA_ "U_CD4_MY13_Phev_Rx" SG_ 1854 TesterPhysicalResPAM 1;
BA_ "U_CD42_MY14_Diesel_Rx" SG_ 1854 TesterPhysicalResPAM 1;
BA_ "U_CD42_MY14_Gas_Rx" SG_ 1854 TesterPhysicalResPAM 1;
BA_ "U_P552_MY15_Gas_Rx" SG_ 1854 TesterPhysicalResPAM 1;
BA_ "U_S550_MY15_Gas_Rx" SG_ 1854 TesterPhysicalResPAM 1;
BA_ "U_C489_MY14_Gas_Rx" SG_ 1854 TesterPhysicalResPAM 1;
BA_ "U_CD4_MY13_Diesel_Tx" SG_ 1854 TesterPhysicalResPAM 1;
BA_ "U_CD4_MY13_Gas_Tx" SG_ 1854 TesterPhysicalResPAM 1;
BA_ "U_CD4_MY13_Hev_Tx" SG_ 1854 TesterPhysicalResPAM 1;
BA_ "U_CD4_MY13_Phev_Tx" SG_ 1854 TesterPhysicalResPAM 1;
BA_ "U_CD42_MY14_Diesel_Tx" SG_ 1854 TesterPhysicalResPAM 1;
BA_ "U_CD42_MY14_Gas_Tx" SG_ 1854 TesterPhysicalResPAM 1;
BA_ "U_P552_MY15_Gas_Tx" SG_ 1854 TesterPhysicalResPAM 1;
BA_ "U_S550_MY15_Gas_Tx" SG_ 1854 TesterPhysicalResPAM 1;
BA_ "U_C489_MY14_Gas_Tx" SG_ 1854 TesterPhysicalResPAM 1;
BA_ "U_U502_MY15_Gas_Tx" SG_ 1854 TesterPhysicalResPAM 1;
BA_ "U_UP375_MY15_Gas_Tx" SG_ 1854 TesterPhysicalResPAM 1;
BA_ "U_UP375_MY15_Diesel_Tx" SG_ 1854 TesterPhysicalResPAM 1;
BA_ "U_CD43_MY16_Gas_Tx" SG_ 1854 TesterPhysicalResPAM 1;
BA_ "U_CD4_MY14_Diesel_Tx" SG_ 1854 TesterPhysicalResPAM 1;
BA_ "U_CD4_MY14_Gas_Tx" SG_ 1854 TesterPhysicalResPAM 1;
BA_ "U_CD4_MY14_Hev_Tx" SG_ 1854 TesterPhysicalResPAM 1;
BA_ "U_CD4_MY14_Phev_Tx" SG_ 1854 TesterPhysicalResPAM 1;
BA_ "U_P558_MY17_Diesel_Rx" SG_ 611 AwdRnge_D_ActlIpc_UB 1;
BA_ "CrossOver_InfoCAN" SG_ 611 AwdRnge_D_ActlIpc 1;
BA_ "GenSigStartValue" SG_ 611 AwdRnge_D_ActlIpc 7;
BA_ "U_P558_MY17_Gas_Rx" SG_ 611 AwdRnge_D_ActlIpc 1;
BA_ "U_P558_MY17_Diesel_Rx" SG_ 611 AwdRnge_D_ActlIpc 1;
BA_ "U_UP375_MY15_Diesel_Rx" SG_ 611 AwdSrvcRqd_B_Rq_UB 1;
BA_ "U_CD42_MY16_Gas_Tx" SG_ 611 AwdSrvcRqd_B_Rq 1;
BA_ "U_CD42_MY16_Diesel_Tx" SG_ 611 AwdSrvcRqd_B_Rq 1;
BA_ "U_C489_MY16_Gas_Tx" SG_ 611 AwdSrvcRqd_B_Rq 1;
BA_ "U_P558_MY17_Gas_Tx" SG_ 611 AwdSrvcRqd_B_Rq 1;
BA_ "U_CD4_MY17_Gas_Tx" SG_ 611 AwdSrvcRqd_B_Rq 1;
BA_ "U_CD4_MY14_Gas_Tx" SG_ 611 AwdSrvcRqd_B_Rq 1;
BA_ "U_CD4_MY14_Diesel_Tx" SG_ 611 AwdSrvcRqd_B_Rq 1;
BA_ "U_CD43_MY16_Gas_Tx" SG_ 611 AwdSrvcRqd_B_Rq 1;
BA_ "U_U502_MY16_Gas_Tx" SG_ 611 AwdSrvcRqd_B_Rq 1;
BA_ "U_CD42_MY15_Diesel_Tx" SG_ 611 AwdSrvcRqd_B_Rq 1;
BA_ "U_CD4_MY13_Gas_Tx" SG_ 611 AwdSrvcRqd_B_Rq 1;
BA_ "U_CD4_MY13_Diesel_Tx" SG_ 611 AwdSrvcRqd_B_Rq 1;
BA_ "U_UP375_MY15_Diesel_Rx" SG_ 611 AwdSrvcRqd_B_Rq 1;
BA_ "U_UP375_MY15_Gas_Rx" SG_ 611 AwdSrvcRqd_B_Rq 1;
BA_ "ContentDependant" SG_ 611 AwdSrvcRqd_B_Rq 1;
BA_ "CrossOver_InfoCAN" SG_ 611 AwdSrvcRqd_B_Rq 1;
BA_ "GenSigSendType" SG_ 611 AwdSrvcRqd_B_Rq 3;
BA_ "U_P552_MY15_Gas_Rx" SG_ 611 RearDiffLck_Tq_Actl_UB 1;
BA_ "U_P552_MY15_Gas_Rx" SG_ 611 RearDiffLck_Tq_Actl 1;
BA_ "U_P552_MY15_Gas_Rx" SG_ 611 AwdSys_D_Stat 1;
BA_ "CrossOver_InfoCAN" SG_ 611 TrnAout_Tq_RqMx 1;
BA_ "U_P552_MY15_Gas_Rx" SG_ 611 TrnAout_Tq_RqMx 1;
BA_ "U_UP375_MY15_Gas_Rx" SG_ 611 TrnAout_Tq_RqMx 1;
BA_ "GenSigStartValue" SG_ 611 TrnAout_Tq_RqMx 8191;
BA_ "CrossOver_InfoCAN" SG_ 611 AwdRnge_D_Actl 1;
BA_ "U_P552_MY15_Gas_Rx" SG_ 611 AwdRnge_D_Actl 1;
BA_ "U_UP375_MY15_Gas_Rx" SG_ 611 AwdRnge_D_Actl 1;
BA_ "GenSigTimeoutTime_TCM" SG_ 611 AwdRnge_D_Actl 300;
BA_ "GenSigStartValue" SG_ 611 AwdRnge_D_Actl 7;
BA_ "U_P552_MY15_Gas_Rx" SG_ 611 AwdRnge_D_Actl_UB 1;
BA_ "U_UP375_MY15_Gas_Rx" SG_ 611 AwdRnge_D_Actl_UB 1;
BA_ "GenSigTimeoutTime_TCM" SG_ 611 AwdRnge_D_Actl_UB 300;
BA_ "GenSigSendType" SG_ 1109 eCallConfirmation 3;
BA_ "U_CD4_MY13_Phev_Rx" SG_ 1109 eCallConfirmation 1;
BA_ "U_CD42_MY14_Diesel_Rx" SG_ 1109 eCallConfirmation 1;
BA_ "U_CD42_MY14_Gas_Rx" SG_ 1109 eCallConfirmation 1;
BA_ "U_P552_MY15_Gas_Rx" SG_ 1109 eCallConfirmation 1;
BA_ "U_S550_MY15_Gas_Rx" SG_ 1109 eCallConfirmation 1;
BA_ "U_C489_MY14_Gas_Rx" SG_ 1109 eCallConfirmation 1;
BA_ "U_U502_MY15_Gas_Rx" SG_ 1109 eCallConfirmation 1;
BA_ "U_UP375_MY15_Gas_Rx" SG_ 1109 eCallConfirmation 1;
BA_ "U_UP375_MY15_Diesel_Rx" SG_ 1109 eCallConfirmation 1;
BA_ "U_CD43_MY16_Gas_Rx" SG_ 1109 eCallConfirmation 1;
BA_ "U_CD4_MY14_Diesel_Rx" SG_ 1109 eCallConfirmation 1;
BA_ "U_CD4_MY14_Gas_Rx" SG_ 1109 eCallConfirmation 1;
BA_ "U_CD4_MY14_Hev_Rx" SG_ 1109 eCallConfirmation 1;
BA_ "U_CD4_MY14_Phev_Rx" SG_ 1109 eCallConfirmation 1;
BA_ "U_CD4_MY13_Diesel_Tx" SG_ 1109 eCallConfirmation 1;
BA_ "U_CD4_MY13_Gas_Tx" SG_ 1109 eCallConfirmation 1;
BA_ "U_CD4_MY13_Hev_Tx" SG_ 1109 eCallConfirmation 1;
BA_ "U_CD4_MY13_Phev_Tx" SG_ 1109 eCallConfirmation 1;
BA_ "U_CD42_MY14_Diesel_Tx" SG_ 1109 eCallConfirmation 1;
BA_ "U_CD42_MY14_Gas_Tx" SG_ 1109 eCallConfirmation 1;
BA_ "U_P552_MY15_Gas_Tx" SG_ 1109 eCallConfirmation 1;
BA_ "U_S550_MY15_Gas_Tx" SG_ 1109 eCallConfirmation 1;
BA_ "U_C489_MY14_Gas_Tx" SG_ 1109 eCallConfirmation 1;
BA_ "U_U502_MY15_Gas_Tx" SG_ 1109 eCallConfirmation 1;
BA_ "U_CD43_MY16_Gas_Tx" SG_ 1109 eCallConfirmation 1;
BA_ "U_CD4_MY14_Diesel_Tx" SG_ 1109 eCallConfirmation 1;
BA_ "U_CD4_MY14_Gas_Tx" SG_ 1109 eCallConfirmation 1;
BA_ "U_CD4_MY14_Hev_Tx" SG_ 1109 eCallConfirmation 1;
BA_ "U_CD4_MY14_Phev_Tx" SG_ 1109 eCallConfirmation 1;
BA_ "CrossOver_InfoCAN" SG_ 359 ElPw_D_StatStrtStop 1;
BA_ "U_CD4_MY13_Gas_Tx" SG_ 359 ElPw_D_StatStrtStop 1;
BA_ "U_CD42_MY14_Gas_Tx" SG_ 359 ElPw_D_StatStrtStop 1;
BA_ "U_P552_MY15_Gas_Tx" SG_ 359 ElPw_D_StatStrtStop 1;
BA_ "U_U502_MY15_Gas_Tx" SG_ 359 ElPw_D_StatStrtStop 1;
BA_ "U_CD43_MY16_Gas_Tx" SG_ 359 ElPw_D_StatStrtStop 1;
BA_ "U_CD4_MY14_Gas_Tx" SG_ 359 ElPw_D_StatStrtStop 1;
BA_ "CrossOver_InfoCAN" SG_ 359 TrnAin_Tq_Actl 1;
BA_ "ContentDependant" SG_ 359 TrnAin_Tq_Actl 1;
BA_ "U_CD4_MY13_Gas_Tx" SG_ 359 TrnAin_Tq_Actl 1;
BA_ "U_CD42_MY14_Gas_Tx" SG_ 359 TrnAin_Tq_Actl 1;
BA_ "U_P552_MY15_Gas_Tx" SG_ 359 TrnAin_Tq_Actl 1;
BA_ "U_S550_MY15_Gas_Tx" SG_ 359 TrnAin_Tq_Actl 1;
BA_ "U_C489_MY14_Gas_Tx" SG_ 359 TrnAin_Tq_Actl 1;
BA_ "U_U502_MY15_Gas_Tx" SG_ 359 TrnAin_Tq_Actl 1;
BA_ "U_CD43_MY16_Gas_Tx" SG_ 359 TrnAin_Tq_Actl 1;
BA_ "U_CD4_MY14_Gas_Tx" SG_ 359 TrnAin_Tq_Actl 1;
BA_ "CrossOver_InfoCAN" SG_ 359 PrplWhlTot2_Tq_Actl 1;
BA_ "U_CD4_MY13_Gas_Tx" SG_ 359 PrplWhlTot2_Tq_Actl 1;
BA_ "U_CD42_MY14_Gas_Tx" SG_ 359 PrplWhlTot2_Tq_Actl 1;
BA_ "U_P552_MY15_Gas_Tx" SG_ 359 PrplWhlTot2_Tq_Actl 1;
BA_ "U_S550_MY15_Gas_Tx" SG_ 359 PrplWhlTot2_Tq_Actl 1;
BA_ "U_C489_MY14_Gas_Tx" SG_ 359 PrplWhlTot2_Tq_Actl 1;
BA_ "U_U502_MY15_Gas_Tx" SG_ 359 PrplWhlTot2_Tq_Actl 1;
BA_ "U_UP375_MY15_Gas_Tx" SG_ 359 PrplWhlTot2_Tq_Actl 1;
BA_ "U_CD43_MY16_Gas_Tx" SG_ 359 PrplWhlTot2_Tq_Actl 1;
BA_ "U_CD4_MY14_Gas_Tx" SG_ 359 PrplWhlTot2_Tq_Actl 1;
BA_ "CrossOver_InfoCAN" SG_ 359 PwPckTq_D_Stat 1;
BA_ "U_CD4_MY13_Diesel_Rx" SG_ 359 PwPckTq_D_Stat 1;
BA_ "U_CD4_MY13_Gas_Rx" SG_ 359 PwPckTq_D_Stat 1;
BA_ "U_CD4_MY13_Hev_Rx" SG_ 359 PwPckTq_D_Stat 1;
BA_ "U_CD4_MY13_Phev_Rx" SG_ 359 PwPckTq_D_Stat 1;
BA_ "U_CD42_MY14_Diesel_Rx" SG_ 359 PwPckTq_D_Stat 1;
BA_ "U_CD42_MY14_Gas_Rx" SG_ 359 PwPckTq_D_Stat 1;
BA_ "U_P552_MY15_Gas_Rx" SG_ 359 PwPckTq_D_Stat 1;
BA_ "U_S550_MY15_Gas_Rx" SG_ 359 PwPckTq_D_Stat 1;
BA_ "U_C489_MY14_Gas_Rx" SG_ 359 PwPckTq_D_Stat 1;
BA_ "U_U502_MY15_Gas_Rx" SG_ 359 PwPckTq_D_Stat 1;
BA_ "U_UP375_MY15_Gas_Rx" SG_ 359 PwPckTq_D_Stat 1;
BA_ "U_UP375_MY15_Diesel_Rx" SG_ 359 PwPckTq_D_Stat 1;
BA_ "U_CD43_MY16_Gas_Rx" SG_ 359 PwPckTq_D_Stat 1;
BA_ "U_CD4_MY14_Diesel_Rx" SG_ 359 PwPckTq_D_Stat 1;
BA_ "U_CD4_MY14_Gas_Rx" SG_ 359 PwPckTq_D_Stat 1;
BA_ "U_CD4_MY14_Hev_Rx" SG_ 359 PwPckTq_D_Stat 1;
BA_ "U_CD4_MY14_Phev_Rx" SG_ 359 PwPckTq_D_Stat 1;
BA_ "U_CD4_MY13_Gas_Tx" SG_ 359 PwPckTq_D_Stat 1;
BA_ "U_CD42_MY14_Gas_Tx" SG_ 359 PwPckTq_D_Stat 1;
BA_ "U_P552_MY15_Gas_Tx" SG_ 359 PwPckTq_D_Stat 1;
BA_ "U_S550_MY15_Gas_Tx" SG_ 359 PwPckTq_D_Stat 1;
BA_ "U_C489_MY14_Gas_Tx" SG_ 359 PwPckTq_D_Stat 1;
BA_ "U_U502_MY15_Gas_Tx" SG_ 359 PwPckTq_D_Stat 1;
BA_ "U_UP375_MY15_Gas_Tx" SG_ 359 PwPckTq_D_Stat 1;
BA_ "U_CD43_MY16_Gas_Tx" SG_ 359 PwPckTq_D_Stat 1;
BA_ "U_CD4_MY14_Gas_Tx" SG_ 359 PwPckTq_D_Stat 1;
BA_ "GenSigTimeoutTime_TCM" SG_ 359 PwPckTq_D_Stat 30;
BA_ "CrossOver_InfoCAN" SG_ 359 Eng_D_Stat 1;
BA_ "U_CD4_MY13_Diesel_Rx" SG_ 359 Eng_D_Stat 1;
BA_ "U_CD4_MY13_Gas_Rx" SG_ 359 Eng_D_Stat 1;
BA_ "U_CD42_MY14_Diesel_Rx" SG_ 359 Eng_D_Stat 1;
BA_ "U_CD42_MY14_Gas_Rx" SG_ 359 Eng_D_Stat 1;
BA_ "U_P552_MY15_Gas_Rx" SG_ 359 Eng_D_Stat 1;
BA_ "U_U502_MY15_Gas_Rx" SG_ 359 Eng_D_Stat 1;
BA_ "U_UP375_MY15_Gas_Rx" SG_ 359 Eng_D_Stat 1;
BA_ "U_UP375_MY15_Diesel_Rx" SG_ 359 Eng_D_Stat 1;
BA_ "U_CD43_MY16_Gas_Rx" SG_ 359 Eng_D_Stat 1;
BA_ "U_CD4_MY14_Diesel_Rx" SG_ 359 Eng_D_Stat 1;
BA_ "U_CD4_MY14_Gas_Rx" SG_ 359 Eng_D_Stat 1;
BA_ "U_CD4_MY14_Hev_Rx" SG_ 359 Eng_D_Stat 1;
BA_ "U_CD4_MY14_Phev_Rx" SG_ 359 Eng_D_Stat 1;
BA_ "U_CD4_MY13_Gas_Tx" SG_ 359 Eng_D_Stat 1;
BA_ "U_CD42_MY14_Gas_Tx" SG_ 359 Eng_D_Stat 1;
BA_ "U_P552_MY15_Gas_Tx" SG_ 359 Eng_D_Stat 1;
BA_ "U_S550_MY15_Gas_Tx" SG_ 359 Eng_D_Stat 1;
BA_ "U_C489_MY14_Gas_Tx" SG_ 359 Eng_D_Stat 1;
BA_ "U_U502_MY15_Gas_Tx" SG_ 359 Eng_D_Stat 1;
BA_ "U_UP375_MY15_Gas_Tx" SG_ 359 Eng_D_Stat 1;
BA_ "U_CD43_MY16_Gas_Tx" SG_ 359 Eng_D_Stat 1;
BA_ "U_CD4_MY14_Gas_Tx" SG_ 359 Eng_D_Stat 1;
BA_ "CrossOver_InfoCAN" SG_ 359 ElPw_D_Stat 1;
BA_ "U_CD4_MY13_Diesel_Rx" SG_ 359 ElPw_D_Stat 1;
BA_ "U_CD4_MY13_Gas_Rx" SG_ 359 ElPw_D_Stat 1;
BA_ "U_CD4_MY13_Hev_Rx" SG_ 359 ElPw_D_Stat 1;
BA_ "U_CD4_MY13_Phev_Rx" SG_ 359 ElPw_D_Stat 1;
BA_ "U_CD42_MY14_Diesel_Rx" SG_ 359 ElPw_D_Stat 1;
BA_ "U_CD42_MY14_Gas_Rx" SG_ 359 ElPw_D_Stat 1;
BA_ "U_P552_MY15_Gas_Rx" SG_ 359 ElPw_D_Stat 1;
BA_ "U_S550_MY15_Gas_Rx" SG_ 359 ElPw_D_Stat 1;
BA_ "U_C489_MY14_Gas_Rx" SG_ 359 ElPw_D_Stat 1;
BA_ "U_U502_MY15_Gas_Rx" SG_ 359 ElPw_D_Stat 1;
BA_ "U_UP375_MY15_Gas_Rx" SG_ 359 ElPw_D_Stat 1;
BA_ "U_UP375_MY15_Diesel_Rx" SG_ 359 ElPw_D_Stat 1;
BA_ "U_CD43_MY16_Gas_Rx" SG_ 359 ElPw_D_Stat 1;
BA_ "U_CD4_MY14_Diesel_Rx" SG_ 359 ElPw_D_Stat 1;
BA_ "U_CD4_MY14_Gas_Rx" SG_ 359 ElPw_D_Stat 1;
BA_ "U_CD4_MY14_Hev_Rx" SG_ 359 ElPw_D_Stat 1;
BA_ "U_CD4_MY14_Phev_Rx" SG_ 359 ElPw_D_Stat 1;
BA_ "U_CD4_MY13_Gas_Tx" SG_ 359 ElPw_D_Stat 1;
BA_ "U_CD42_MY14_Gas_Tx" SG_ 359 ElPw_D_Stat 1;
BA_ "U_P552_MY15_Gas_Tx" SG_ 359 ElPw_D_Stat 1;
BA_ "U_S550_MY15_Gas_Tx" SG_ 359 ElPw_D_Stat 1;
BA_ "U_C489_MY14_Gas_Tx" SG_ 359 ElPw_D_Stat 1;
BA_ "U_U502_MY15_Gas_Tx" SG_ 359 ElPw_D_Stat 1;
BA_ "U_UP375_MY15_Gas_Tx" SG_ 359 ElPw_D_Stat 1;
BA_ "U_CD43_MY16_Gas_Tx" SG_ 359 ElPw_D_Stat 1;
BA_ "U_CD4_MY14_Gas_Tx" SG_ 359 ElPw_D_Stat 1;
BA_ "GenSigTimeoutTime_TCM" SG_ 359 ElPw_D_Stat 30;
BA_ "CrossOver_InfoCAN" SG_ 359 TrnAinTq_D_Qf 1;
BA_ "ContentDependant" SG_ 359 TrnAinTq_D_Qf 1;
BA_ "U_CD4_MY13_Gas_Tx" SG_ 359 TrnAinTq_D_Qf 1;
BA_ "U_CD42_MY14_Gas_Tx" SG_ 359 TrnAinTq_D_Qf 1;
BA_ "U_P552_MY15_Gas_Tx" SG_ 359 TrnAinTq_D_Qf 1;
BA_ "U_S550_MY15_Gas_Tx" SG_ 359 TrnAinTq_D_Qf 1;
BA_ "U_C489_MY14_Gas_Tx" SG_ 359 TrnAinTq_D_Qf 1;
BA_ "U_U502_MY15_Gas_Tx" SG_ 359 TrnAinTq_D_Qf 1;
BA_ "U_CD43_MY16_Gas_Tx" SG_ 359 TrnAinTq_D_Qf 1;
BA_ "U_CD4_MY14_Gas_Tx" SG_ 359 TrnAinTq_D_Qf 1;
BA_ "CrossOver_InfoCAN" SG_ 358 StopStrtStdby_D_Indic 1;
BA_ "GenSigStartValue" SG_ 358 StopStrtStdby_D_Indic 5;
BA_ "U_CD4_MY13_Gas_Tx" SG_ 358 StopStrtStdby_D_Indic 1;
BA_ "U_CD42_MY14_Gas_Tx" SG_ 358 StopStrtStdby_D_Indic 1;
BA_ "U_P552_MY15_Gas_Tx" SG_ 358 StopStrtStdby_D_Indic 1;
BA_ "U_U502_MY15_Gas_Tx" SG_ 358 StopStrtStdby_D_Indic 1;
BA_ "U_CD43_MY16_Gas_Tx" SG_ 358 StopStrtStdby_D_Indic 1;
BA_ "U_CD4_MY14_Gas_Tx" SG_ 358 StopStrtStdby_D_Indic 1;
BA_ "CrossOver_InfoCAN" SG_ 358 StopStrtIODTxt_D_Rq 1;
BA_ "U_CD4_MY13_Gas_Tx" SG_ 358 StopStrtIODTxt_D_Rq 1;
BA_ "U_CD42_MY14_Gas_Tx" SG_ 358 StopStrtIODTxt_D_Rq 1;
BA_ "U_P552_MY15_Gas_Tx" SG_ 358 StopStrtIODTxt_D_Rq 1;
BA_ "U_U502_MY15_Gas_Tx" SG_ 358 StopStrtIODTxt_D_Rq 1;
BA_ "U_CD43_MY16_Gas_Tx" SG_ 358 StopStrtIODTxt_D_Rq 1;
BA_ "U_CD4_MY14_Gas_Tx" SG_ 358 StopStrtIODTxt_D_Rq 1;
BA_ "CrossOver_InfoCAN" SG_ 358 StopStrtDrvMde_D_Indic 1;
BA_ "U_CD4_MY13_Gas_Tx" SG_ 358 StopStrtDrvMde_D_Indic 1;
BA_ "U_CD42_MY14_Gas_Tx" SG_ 358 StopStrtDrvMde_D_Indic 1;
BA_ "U_P552_MY15_Gas_Tx" SG_ 358 StopStrtDrvMde_D_Indic 1;
BA_ "U_U502_MY15_Gas_Tx" SG_ 358 StopStrtDrvMde_D_Indic 1;
BA_ "U_CD43_MY16_Gas_Tx" SG_ 358 StopStrtDrvMde_D_Indic 1;
BA_ "U_CD4_MY14_Gas_Tx" SG_ 358 StopStrtDrvMde_D_Indic 1;
BA_ "CrossOver_InfoCAN" SG_ 358 StopStrtMsgTxt_D_Rq 1;
BA_ "U_CD4_MY13_Gas_Tx" SG_ 358 StopStrtMsgTxt_D_Rq 1;
BA_ "U_CD42_MY14_Gas_Tx" SG_ 358 StopStrtMsgTxt_D_Rq 1;
BA_ "U_P552_MY15_Gas_Tx" SG_ 358 StopStrtMsgTxt_D_Rq 1;
BA_ "U_U502_MY15_Gas_Tx" SG_ 358 StopStrtMsgTxt_D_Rq 1;
BA_ "U_CD43_MY16_Gas_Tx" SG_ 358 StopStrtMsgTxt_D_Rq 1;
BA_ "U_CD4_MY14_Gas_Tx" SG_ 358 StopStrtMsgTxt_D_Rq 1;
BA_ "CrossOver_InfoCAN" SG_ 358 OdoTripVerify_L_Actl 1;
BA_ "U_CD4_MY13_Gas_Tx" SG_ 358 OdoTripVerify_L_Actl 1;
BA_ "U_CD42_MY14_Gas_Tx" SG_ 358 OdoTripVerify_L_Actl 1;
BA_ "U_P552_MY15_Gas_Tx" SG_ 358 OdoTripVerify_L_Actl 1;
BA_ "U_S550_MY15_Gas_Tx" SG_ 358 OdoTripVerify_L_Actl 1;
BA_ "U_C489_MY14_Gas_Tx" SG_ 358 OdoTripVerify_L_Actl 1;
BA_ "U_U502_MY15_Gas_Tx" SG_ 358 OdoTripVerify_L_Actl 1;
BA_ "U_UP375_MY15_Gas_Tx" SG_ 358 OdoTripVerify_L_Actl 1;
BA_ "U_CD43_MY16_Gas_Tx" SG_ 358 OdoTripVerify_L_Actl 1;
BA_ "U_CD4_MY14_Gas_Tx" SG_ 358 OdoTripVerify_L_Actl 1;
BA_ "CrossOver_InfoCAN" SG_ 358 HiElPwInhbt_B_Stat 1;
BA_ "ContentDependant" SG_ 358 HiElPwInhbt_B_Stat 1;
BA_ "U_CD4_MY13_Gas_Tx" SG_ 358 HiElPwInhbt_B_Stat 1;
BA_ "U_CD42_MY14_Gas_Tx" SG_ 358 HiElPwInhbt_B_Stat 1;
BA_ "U_P552_MY15_Gas_Tx" SG_ 358 HiElPwInhbt_B_Stat 1;
BA_ "U_U502_MY15_Gas_Tx" SG_ 358 HiElPwInhbt_B_Stat 1;
BA_ "U_CD43_MY16_Gas_Tx" SG_ 358 HiElPwInhbt_B_Stat 1;
BA_ "U_CD4_MY14_Gas_Tx" SG_ 358 HiElPwInhbt_B_Stat 1;
BA_ "CrossOver_InfoCAN" SG_ 358 AutoStopPtDelta_I_Est 1;
BA_ "GenSigStartValue" SG_ 358 AutoStopPtDelta_I_Est 127;
BA_ "ContentDependant" SG_ 358 AutoStopPtDelta_I_Est 1;
BA_ "U_CD4_MY13_Diesel_Rx" SG_ 358 AutoStopPtDelta_I_Est 1;
BA_ "U_CD4_MY13_Gas_Rx" SG_ 358 AutoStopPtDelta_I_Est 1;
BA_ "U_CD4_MY13_Hev_Rx" SG_ 358 AutoStopPtDelta_I_Est 1;
BA_ "U_CD4_MY13_Phev_Rx" SG_ 358 AutoStopPtDelta_I_Est 1;
BA_ "U_CD42_MY14_Diesel_Rx" SG_ 358 AutoStopPtDelta_I_Est 1;
BA_ "U_CD42_MY14_Gas_Rx" SG_ 358 AutoStopPtDelta_I_Est 1;
BA_ "U_P552_MY15_Gas_Rx" SG_ 358 AutoStopPtDelta_I_Est 1;
BA_ "U_S550_MY15_Gas_Rx" SG_ 358 AutoStopPtDelta_I_Est 1;
BA_ "U_C489_MY14_Gas_Rx" SG_ 358 AutoStopPtDelta_I_Est 1;
BA_ "U_U502_MY15_Gas_Rx" SG_ 358 AutoStopPtDelta_I_Est 1;
BA_ "U_UP375_MY15_Gas_Rx" SG_ 358 AutoStopPtDelta_I_Est 1;
BA_ "U_UP375_MY15_Diesel_Rx" SG_ 358 AutoStopPtDelta_I_Est 1;
BA_ "U_CD43_MY16_Gas_Rx" SG_ 358 AutoStopPtDelta_I_Est 1;
BA_ "U_CD4_MY14_Diesel_Rx" SG_ 358 AutoStopPtDelta_I_Est 1;
BA_ "U_CD4_MY14_Gas_Rx" SG_ 358 AutoStopPtDelta_I_Est 1;
BA_ "U_CD4_MY14_Hev_Rx" SG_ 358 AutoStopPtDelta_I_Est 1;
BA_ "U_CD4_MY14_Phev_Rx" SG_ 358 AutoStopPtDelta_I_Est 1;
BA_ "U_CD4_MY13_Gas_Tx" SG_ 358 AutoStopPtDelta_I_Est 1;
BA_ "U_CD42_MY14_Gas_Tx" SG_ 358 AutoStopPtDelta_I_Est 1;
BA_ "U_P552_MY15_Gas_Tx" SG_ 358 AutoStopPtDelta_I_Est 1;
BA_ "U_U502_MY15_Gas_Tx" SG_ 358 AutoStopPtDelta_I_Est 1;
BA_ "U_CD43_MY16_Gas_Tx" SG_ 358 AutoStopPtDelta_I_Est 1;
BA_ "U_CD4_MY14_Gas_Tx" SG_ 358 AutoStopPtDelta_I_Est 1;
BA_ "U_CD4_MY13_Gas_Rx" SG_ 1078 UStabLvl2OvrTe_B_Stat 1;
BA_ "U_CD42_MY14_Gas_Rx" SG_ 1078 UStabLvl2OvrTe_B_Stat 1;
BA_ "U_P552_MY15_Gas_Rx" SG_ 1078 UStabLvl2OvrTe_B_Stat 1;
BA_ "U_CD43_MY16_Gas_Rx" SG_ 1078 UStabLvl2OvrTe_B_Stat 1;
BA_ "U_CD4_MY14_Gas_Rx" SG_ 1078 UStabLvl2OvrTe_B_Stat 1;
BA_ "U_CD4_MY13_Diesel_Tx" SG_ 1078 UStabLvl2OvrTe_B_Stat 1;
BA_ "U_CD4_MY13_Gas_Tx" SG_ 1078 UStabLvl2OvrTe_B_Stat 1;
BA_ "U_CD42_MY14_Diesel_Tx" SG_ 1078 UStabLvl2OvrTe_B_Stat 1;
BA_ "U_CD42_MY14_Gas_Tx" SG_ 1078 UStabLvl2OvrTe_B_Stat 1;
BA_ "U_P552_MY15_Gas_Tx" SG_ 1078 UStabLvl2OvrTe_B_Stat 1;
BA_ "U_UP375_MY15_Diesel_Tx" SG_ 1078 UStabLvl2OvrTe_B_Stat 1;
BA_ "U_CD43_MY16_Gas_Tx" SG_ 1078 UStabLvl2OvrTe_B_Stat 1;
BA_ "U_CD4_MY14_Diesel_Tx" SG_ 1078 UStabLvl2OvrTe_B_Stat 1;
BA_ "U_CD4_MY14_Gas_Tx" SG_ 1078 UStabLvl2OvrTe_B_Stat 1;
BA_ "U_CD4_MY13_Gas_Rx" SG_ 1078 UStabLvl2Ovrld_B_Stat 1;
BA_ "U_CD42_MY14_Gas_Rx" SG_ 1078 UStabLvl2Ovrld_B_Stat 1;
BA_ "U_P552_MY15_Gas_Rx" SG_ 1078 UStabLvl2Ovrld_B_Stat 1;
BA_ "U_CD43_MY16_Gas_Rx" SG_ 1078 UStabLvl2Ovrld_B_Stat 1;
BA_ "U_CD4_MY14_Gas_Rx" SG_ 1078 UStabLvl2Ovrld_B_Stat 1;
BA_ "U_CD4_MY13_Diesel_Tx" SG_ 1078 UStabLvl2Ovrld_B_Stat 1;
BA_ "U_CD4_MY13_Gas_Tx" SG_ 1078 UStabLvl2Ovrld_B_Stat 1;
BA_ "U_CD42_MY14_Diesel_Tx" SG_ 1078 UStabLvl2Ovrld_B_Stat 1;
BA_ "U_CD42_MY14_Gas_Tx" SG_ 1078 UStabLvl2Ovrld_B_Stat 1;
BA_ "U_P552_MY15_Gas_Tx" SG_ 1078 UStabLvl2Ovrld_B_Stat 1;
BA_ "U_UP375_MY15_Diesel_Tx" SG_ 1078 UStabLvl2Ovrld_B_Stat 1;
BA_ "U_CD43_MY16_Gas_Tx" SG_ 1078 UStabLvl2Ovrld_B_Stat 1;
BA_ "U_CD4_MY14_Diesel_Tx" SG_ 1078 UStabLvl2Ovrld_B_Stat 1;
BA_ "U_CD4_MY14_Gas_Tx" SG_ 1078 UStabLvl2Ovrld_B_Stat 1;
BA_ "U_CD4_MY13_Gas_Rx" SG_ 1078 UStabLvl2_D_Stat 1;
BA_ "U_CD42_MY14_Gas_Rx" SG_ 1078 UStabLvl2_D_Stat 1;
BA_ "U_P552_MY15_Gas_Rx" SG_ 1078 UStabLvl2_D_Stat 1;
BA_ "U_CD43_MY16_Gas_Rx" SG_ 1078 UStabLvl2_D_Stat 1;
BA_ "U_CD4_MY14_Gas_Rx" SG_ 1078 UStabLvl2_D_Stat 1;
BA_ "U_CD4_MY13_Diesel_Tx" SG_ 1078 UStabLvl2_D_Stat 1;
BA_ "U_CD4_MY13_Gas_Tx" SG_ 1078 UStabLvl2_D_Stat 1;
BA_ "U_CD42_MY14_Diesel_Tx" SG_ 1078 UStabLvl2_D_Stat 1;
BA_ "U_CD42_MY14_Gas_Tx" SG_ 1078 UStabLvl2_D_Stat 1;
BA_ "U_P552_MY15_Gas_Tx" SG_ 1078 UStabLvl2_D_Stat 1;
BA_ "U_UP375_MY15_Diesel_Tx" SG_ 1078 UStabLvl2_D_Stat 1;
BA_ "U_CD43_MY16_Gas_Tx" SG_ 1078 UStabLvl2_D_Stat 1;
BA_ "U_CD4_MY14_Diesel_Tx" SG_ 1078 UStabLvl2_D_Stat 1;
BA_ "U_CD4_MY14_Gas_Tx" SG_ 1078 UStabLvl2_D_Stat 1;
BA_ "GenSigStartValue" SG_ 1084 BattULoChrg_URate_RqMx 5;
BA_ "U_CD4_MY13_Gas_Rx" SG_ 1084 BattULoChrg_URate_RqMx 1;
BA_ "U_CD42_MY14_Gas_Rx" SG_ 1084 BattULoChrg_URate_RqMx 1;
BA_ "U_P552_MY15_Gas_Rx" SG_ 1084 BattULoChrg_URate_RqMx 1;
BA_ "U_S550_MY15_Gas_Rx" SG_ 1084 BattULoChrg_URate_RqMx 1;
BA_ "U_C489_MY14_Gas_Rx" SG_ 1084 BattULoChrg_URate_RqMx 1;
BA_ "U_U502_MY15_Gas_Rx" SG_ 1084 BattULoChrg_URate_RqMx 1;
BA_ "U_CD43_MY16_Gas_Rx" SG_ 1084 BattULoChrg_URate_RqMx 1;
BA_ "U_CD4_MY14_Gas_Rx" SG_ 1084 BattULoChrg_URate_RqMx 1;
BA_ "U_CD4_MY13_Diesel_Tx" SG_ 1084 BattULoChrg_URate_RqMx 1;
BA_ "U_CD4_MY13_Gas_Tx" SG_ 1084 BattULoChrg_URate_RqMx 1;
BA_ "U_CD4_MY13_Hev_Tx" SG_ 1084 BattULoChrg_URate_RqMx 1;
BA_ "U_CD4_MY13_Phev_Tx" SG_ 1084 BattULoChrg_URate_RqMx 1;
BA_ "U_CD42_MY14_Diesel_Tx" SG_ 1084 BattULoChrg_URate_RqMx 1;
BA_ "U_CD42_MY14_Gas_Tx" SG_ 1084 BattULoChrg_URate_RqMx 1;
BA_ "U_P552_MY15_Gas_Tx" SG_ 1084 BattULoChrg_URate_RqMx 1;
BA_ "U_S550_MY15_Gas_Tx" SG_ 1084 BattULoChrg_URate_RqMx 1;
BA_ "U_C489_MY14_Gas_Tx" SG_ 1084 BattULoChrg_URate_RqMx 1;
BA_ "U_U502_MY15_Gas_Tx" SG_ 1084 BattULoChrg_URate_RqMx 1;
BA_ "U_UP375_MY15_Gas_Tx" SG_ 1084 BattULoChrg_URate_RqMx 1;
BA_ "U_UP375_MY15_Diesel_Tx" SG_ 1084 BattULoChrg_URate_RqMx 1;
BA_ "U_CD43_MY16_Gas_Tx" SG_ 1084 BattULoChrg_URate_RqMx 1;
BA_ "U_CD4_MY14_Diesel_Tx" SG_ 1084 BattULoChrg_URate_RqMx 1;
BA_ "U_CD4_MY14_Gas_Tx" SG_ 1084 BattULoChrg_URate_RqMx 1;
BA_ "U_CD4_MY14_Hev_Tx" SG_ 1084 BattULoChrg_URate_RqMx 1;
BA_ "U_CD4_MY14_Phev_Tx" SG_ 1084 BattULoChrg_URate_RqMx 1;
BA_ "GenSigStartValue" SG_ 1084 BattULoChrg_U_RqMx 34;
BA_ "U_CD4_MY13_Gas_Rx" SG_ 1084 BattULoChrg_U_RqMx 1;
BA_ "U_CD42_MY14_Gas_Rx" SG_ 1084 BattULoChrg_U_RqMx 1;
BA_ "U_P552_MY15_Gas_Rx" SG_ 1084 BattULoChrg_U_RqMx 1;
BA_ "U_S550_MY15_Gas_Rx" SG_ 1084 BattULoChrg_U_RqMx 1;
BA_ "U_C489_MY14_Gas_Rx" SG_ 1084 BattULoChrg_U_RqMx 1;
BA_ "U_U502_MY15_Gas_Rx" SG_ 1084 BattULoChrg_U_RqMx 1;
BA_ "U_CD43_MY16_Gas_Rx" SG_ 1084 BattULoChrg_U_RqMx 1;
BA_ "U_CD4_MY14_Gas_Rx" SG_ 1084 BattULoChrg_U_RqMx 1;
BA_ "U_CD4_MY13_Diesel_Tx" SG_ 1084 BattULoChrg_U_RqMx 1;
BA_ "U_CD4_MY13_Gas_Tx" SG_ 1084 BattULoChrg_U_RqMx 1;
BA_ "U_CD4_MY13_Hev_Tx" SG_ 1084 BattULoChrg_U_RqMx 1;
BA_ "U_CD4_MY13_Phev_Tx" SG_ 1084 BattULoChrg_U_RqMx 1;
BA_ "U_CD42_MY14_Diesel_Tx" SG_ 1084 BattULoChrg_U_RqMx 1;
BA_ "U_CD42_MY14_Gas_Tx" SG_ 1084 BattULoChrg_U_RqMx 1;
BA_ "U_P552_MY15_Gas_Tx" SG_ 1084 BattULoChrg_U_RqMx 1;
BA_ "U_S550_MY15_Gas_Tx" SG_ 1084 BattULoChrg_U_RqMx 1;
BA_ "U_C489_MY14_Gas_Tx" SG_ 1084 BattULoChrg_U_RqMx 1;
BA_ "U_U502_MY15_Gas_Tx" SG_ 1084 BattULoChrg_U_RqMx 1;
BA_ "U_UP375_MY15_Gas_Tx" SG_ 1084 BattULoChrg_U_RqMx 1;
BA_ "U_UP375_MY15_Diesel_Tx" SG_ 1084 BattULoChrg_U_RqMx 1;
BA_ "U_CD43_MY16_Gas_Tx" SG_ 1084 BattULoChrg_U_RqMx 1;
BA_ "U_CD4_MY14_Diesel_Tx" SG_ 1084 BattULoChrg_U_RqMx 1;
BA_ "U_CD4_MY14_Gas_Tx" SG_ 1084 BattULoChrg_U_RqMx 1;
BA_ "U_CD4_MY14_Hev_Tx" SG_ 1084 BattULoChrg_U_RqMx 1;
BA_ "U_CD4_MY14_Phev_Tx" SG_ 1084 BattULoChrg_U_RqMx 1;
BA_ "U_CD4_MY13_Gas_Rx" SG_ 1084 BattULoChrg_U_RqMn 1;
BA_ "U_CD42_MY14_Gas_Rx" SG_ 1084 BattULoChrg_U_RqMn 1;
BA_ "U_P552_MY15_Gas_Rx" SG_ 1084 BattULoChrg_U_RqMn 1;
BA_ "U_S550_MY15_Gas_Rx" SG_ 1084 BattULoChrg_U_RqMn 1;
BA_ "U_C489_MY14_Gas_Rx" SG_ 1084 BattULoChrg_U_RqMn 1;
BA_ "U_U502_MY15_Gas_Rx" SG_ 1084 BattULoChrg_U_RqMn 1;
BA_ "U_CD43_MY16_Gas_Rx" SG_ 1084 BattULoChrg_U_RqMn 1;
BA_ "U_CD4_MY14_Gas_Rx" SG_ 1084 BattULoChrg_U_RqMn 1;
BA_ "U_CD4_MY13_Diesel_Tx" SG_ 1084 BattULoChrg_U_RqMn 1;
BA_ "U_CD4_MY13_Gas_Tx" SG_ 1084 BattULoChrg_U_RqMn 1;
BA_ "U_CD4_MY13_Hev_Tx" SG_ 1084 BattULoChrg_U_RqMn 1;
BA_ "U_CD4_MY13_Phev_Tx" SG_ 1084 BattULoChrg_U_RqMn 1;
BA_ "U_CD42_MY14_Diesel_Tx" SG_ 1084 BattULoChrg_U_RqMn 1;
BA_ "U_CD42_MY14_Gas_Tx" SG_ 1084 BattULoChrg_U_RqMn 1;
BA_ "U_P552_MY15_Gas_Tx" SG_ 1084 BattULoChrg_U_RqMn 1;
BA_ "U_S550_MY15_Gas_Tx" SG_ 1084 BattULoChrg_U_RqMn 1;
BA_ "U_C489_MY14_Gas_Tx" SG_ 1084 BattULoChrg_U_RqMn 1;
BA_ "U_U502_MY15_Gas_Tx" SG_ 1084 BattULoChrg_U_RqMn 1;
BA_ "U_UP375_MY15_Gas_Tx" SG_ 1084 BattULoChrg_U_RqMn 1;
BA_ "U_UP375_MY15_Diesel_Tx" SG_ 1084 BattULoChrg_U_RqMn 1;
BA_ "U_CD43_MY16_Gas_Tx" SG_ 1084 BattULoChrg_U_RqMn 1;
BA_ "U_CD4_MY14_Diesel_Tx" SG_ 1084 BattULoChrg_U_RqMn 1;
BA_ "U_CD4_MY14_Gas_Tx" SG_ 1084 BattULoChrg_U_RqMn 1;
BA_ "U_CD4_MY14_Hev_Tx" SG_ 1084 BattULoChrg_U_RqMn 1;
BA_ "U_CD4_MY14_Phev_Tx" SG_ 1084 BattULoChrg_U_RqMn 1;
BA_ "U_CD42_MY14_Gas_Rx" SG_ 1084 BattULoState_D_Qlty 1;
BA_ "U_P552_MY15_Gas_Rx" SG_ 1084 BattULoState_D_Qlty 1;
BA_ "U_S550_MY15_Gas_Rx" SG_ 1084 BattULoState_D_Qlty 1;
BA_ "U_C489_MY14_Gas_Rx" SG_ 1084 BattULoState_D_Qlty 1;
BA_ "U_U502_MY15_Gas_Rx" SG_ 1084 BattULoState_D_Qlty 1;
BA_ "U_CD43_MY16_Gas_Rx" SG_ 1084 BattULoState_D_Qlty 1;
BA_ "U_CD4_MY14_Gas_Rx" SG_ 1084 BattULoState_D_Qlty 1;
BA_ "U_CD4_MY13_Diesel_Tx" SG_ 1084 BattULoState_D_Qlty 1;
BA_ "U_CD4_MY13_Gas_Tx" SG_ 1084 BattULoState_D_Qlty 1;
BA_ "U_CD4_MY13_Hev_Tx" SG_ 1084 BattULoState_D_Qlty 1;
BA_ "U_CD4_MY13_Phev_Tx" SG_ 1084 BattULoState_D_Qlty 1;
BA_ "U_CD42_MY14_Diesel_Tx" SG_ 1084 BattULoState_D_Qlty 1;
BA_ "U_CD42_MY14_Gas_Tx" SG_ 1084 BattULoState_D_Qlty 1;
BA_ "U_P552_MY15_Gas_Tx" SG_ 1084 BattULoState_D_Qlty 1;
BA_ "U_S550_MY15_Gas_Tx" SG_ 1084 BattULoState_D_Qlty 1;
BA_ "U_C489_MY14_Gas_Tx" SG_ 1084 BattULoState_D_Qlty 1;
BA_ "U_U502_MY15_Gas_Tx" SG_ 1084 BattULoState_D_Qlty 1;
BA_ "U_UP375_MY15_Gas_Tx" SG_ 1084 BattULoState_D_Qlty 1;
BA_ "U_UP375_MY15_Diesel_Tx" SG_ 1084 BattULoState_D_Qlty 1;
BA_ "U_CD43_MY16_Gas_Tx" SG_ 1084 BattULoState_D_Qlty 1;
BA_ "U_CD4_MY14_Diesel_Tx" SG_ 1084 BattULoState_D_Qlty 1;
BA_ "U_CD4_MY14_Gas_Tx" SG_ 1084 BattULoState_D_Qlty 1;
BA_ "U_CD4_MY14_Hev_Tx" SG_ 1084 BattULoState_D_Qlty 1;
BA_ "U_CD4_MY14_Phev_Tx" SG_ 1084 BattULoState_D_Qlty 1;
BA_ "U_CD4_MY13_Gas_Rx" SG_ 1084 BSFault 1;
BA_ "U_CD42_MY14_Gas_Rx" SG_ 1084 BSFault 1;
BA_ "U_P552_MY15_Gas_Rx" SG_ 1084 BSFault 1;
BA_ "U_S550_MY15_Gas_Rx" SG_ 1084 BSFault 1;
BA_ "U_C489_MY14_Gas_Rx" SG_ 1084 BSFault 1;
BA_ "U_U502_MY15_Gas_Rx" SG_ 1084 BSFault 1;
BA_ "U_CD43_MY16_Gas_Rx" SG_ 1084 BSFault 1;
BA_ "U_CD4_MY14_Gas_Rx" SG_ 1084 BSFault 1;
BA_ "U_CD4_MY13_Diesel_Tx" SG_ 1084 BSFault 1;
BA_ "U_CD4_MY13_Gas_Tx" SG_ 1084 BSFault 1;
BA_ "U_CD4_MY13_Hev_Tx" SG_ 1084 BSFault 1;
BA_ "U_CD4_MY13_Phev_Tx" SG_ 1084 BSFault 1;
BA_ "U_CD42_MY14_Diesel_Tx" SG_ 1084 BSFault 1;
BA_ "U_CD42_MY14_Gas_Tx" SG_ 1084 BSFault 1;
BA_ "U_P552_MY15_Gas_Tx" SG_ 1084 BSFault 1;
BA_ "U_S550_MY15_Gas_Tx" SG_ 1084 BSFault 1;
BA_ "U_C489_MY14_Gas_Tx" SG_ 1084 BSFault 1;
BA_ "U_U502_MY15_Gas_Tx" SG_ 1084 BSFault 1;
BA_ "U_UP375_MY15_Gas_Tx" SG_ 1084 BSFault 1;
BA_ "U_UP375_MY15_Diesel_Tx" SG_ 1084 BSFault 1;
BA_ "U_CD43_MY16_Gas_Tx" SG_ 1084 BSFault 1;
BA_ "U_CD4_MY14_Diesel_Tx" SG_ 1084 BSFault 1;
BA_ "U_CD4_MY14_Gas_Tx" SG_ 1084 BSFault 1;
BA_ "U_CD4_MY14_Hev_Tx" SG_ 1084 BSFault 1;
BA_ "U_CD4_MY14_Phev_Tx" SG_ 1084 BSFault 1;
BA_ "GenSigStartValue" SG_ 1084 BattULo2_Te_Actl 127;
BA_ "U_CD4_MY13_Gas_Rx" SG_ 1084 BattULo2_Te_Actl 1;
BA_ "U_CD42_MY14_Gas_Rx" SG_ 1084 BattULo2_Te_Actl 1;
BA_ "U_P552_MY15_Gas_Rx" SG_ 1084 BattULo2_Te_Actl 1;
BA_ "U_S550_MY15_Gas_Rx" SG_ 1084 BattULo2_Te_Actl 1;
BA_ "U_C489_MY14_Gas_Rx" SG_ 1084 BattULo2_Te_Actl 1;
BA_ "U_U502_MY15_Gas_Rx" SG_ 1084 BattULo2_Te_Actl 1;
BA_ "U_CD43_MY16_Gas_Rx" SG_ 1084 BattULo2_Te_Actl 1;
BA_ "U_CD4_MY14_Gas_Rx" SG_ 1084 BattULo2_Te_Actl 1;
BA_ "U_CD4_MY13_Diesel_Tx" SG_ 1084 BattULo2_Te_Actl 1;
BA_ "U_CD4_MY13_Gas_Tx" SG_ 1084 BattULo2_Te_Actl 1;
BA_ "U_CD4_MY13_Hev_Tx" SG_ 1084 BattULo2_Te_Actl 1;
BA_ "U_CD4_MY13_Phev_Tx" SG_ 1084 BattULo2_Te_Actl 1;
BA_ "U_CD42_MY14_Diesel_Tx" SG_ 1084 BattULo2_Te_Actl 1;
BA_ "U_CD42_MY14_Gas_Tx" SG_ 1084 BattULo2_Te_Actl 1;
BA_ "U_P552_MY15_Gas_Tx" SG_ 1084 BattULo2_Te_Actl 1;
BA_ "U_S550_MY15_Gas_Tx" SG_ 1084 BattULo2_Te_Actl 1;
BA_ "U_C489_MY14_Gas_Tx" SG_ 1084 BattULo2_Te_Actl 1;
BA_ "U_U502_MY15_Gas_Tx" SG_ 1084 BattULo2_Te_Actl 1;
BA_ "U_UP375_MY15_Gas_Tx" SG_ 1084 BattULo2_Te_Actl 1;
BA_ "U_UP375_MY15_Diesel_Tx" SG_ 1084 BattULo2_Te_Actl 1;
BA_ "U_CD43_MY16_Gas_Tx" SG_ 1084 BattULo2_Te_Actl 1;
BA_ "U_CD4_MY14_Diesel_Tx" SG_ 1084 BattULo2_Te_Actl 1;
BA_ "U_CD4_MY14_Gas_Tx" SG_ 1084 BattULo2_Te_Actl 1;
BA_ "U_CD4_MY14_Hev_Tx" SG_ 1084 BattULo2_Te_Actl 1;
BA_ "U_CD4_MY14_Phev_Tx" SG_ 1084 BattULo2_Te_Actl 1;
BA_ "U_CD42_MY14_Gas_Rx" SG_ 1084 BSBattSOC 1;
BA_ "U_P552_MY15_Gas_Rx" SG_ 1084 BSBattSOC 1;
BA_ "U_S550_MY15_Gas_Rx" SG_ 1084 BSBattSOC 1;
BA_ "U_C489_MY14_Gas_Rx" SG_ 1084 BSBattSOC 1;
BA_ "U_U502_MY15_Gas_Rx" SG_ 1084 BSBattSOC 1;
BA_ "U_CD43_MY16_Gas_Rx" SG_ 1084 BSBattSOC 1;
BA_ "U_CD4_MY14_Gas_Rx" SG_ 1084 BSBattSOC 1;
BA_ "U_CD4_MY13_Diesel_Tx" SG_ 1084 BSBattSOC 1;
BA_ "U_CD4_MY13_Gas_Tx" SG_ 1084 BSBattSOC 1;
BA_ "U_CD4_MY13_Hev_Tx" SG_ 1084 BSBattSOC 1;
BA_ "U_CD4_MY13_Phev_Tx" SG_ 1084 BSBattSOC 1;
BA_ "U_CD42_MY14_Diesel_Tx" SG_ 1084 BSBattSOC 1;
BA_ "U_CD42_MY14_Gas_Tx" SG_ 1084 BSBattSOC 1;
BA_ "U_P552_MY15_Gas_Tx" SG_ 1084 BSBattSOC 1;
BA_ "U_S550_MY15_Gas_Tx" SG_ 1084 BSBattSOC 1;
BA_ "U_C489_MY14_Gas_Tx" SG_ 1084 BSBattSOC 1;
BA_ "U_U502_MY15_Gas_Tx" SG_ 1084 BSBattSOC 1;
BA_ "U_UP375_MY15_Gas_Tx" SG_ 1084 BSBattSOC 1;
BA_ "U_UP375_MY15_Diesel_Tx" SG_ 1084 BSBattSOC 1;
BA_ "U_CD43_MY16_Gas_Tx" SG_ 1084 BSBattSOC 1;
BA_ "U_CD4_MY14_Diesel_Tx" SG_ 1084 BSBattSOC 1;
BA_ "U_CD4_MY14_Gas_Tx" SG_ 1084 BSBattSOC 1;
BA_ "U_CD4_MY14_Hev_Tx" SG_ 1084 BSBattSOC 1;
BA_ "U_CD4_MY14_Phev_Tx" SG_ 1084 BSBattSOC 1;
BA_ "GenSigStartValue" SG_ 1084 BSBattQDeltaRideAh 12800;
BA_ "U_CD4_MY13_Gas_Rx" SG_ 1084 BSBattQDeltaRideAh 1;
BA_ "U_CD42_MY14_Gas_Rx" SG_ 1084 BSBattQDeltaRideAh 1;
BA_ "U_P552_MY15_Gas_Rx" SG_ 1084 BSBattQDeltaRideAh 1;
BA_ "U_S550_MY15_Gas_Rx" SG_ 1084 BSBattQDeltaRideAh 1;
BA_ "U_C489_MY14_Gas_Rx" SG_ 1084 BSBattQDeltaRideAh 1;
BA_ "U_U502_MY15_Gas_Rx" SG_ 1084 BSBattQDeltaRideAh 1;
BA_ "U_CD43_MY16_Gas_Rx" SG_ 1084 BSBattQDeltaRideAh 1;
BA_ "U_CD4_MY14_Gas_Rx" SG_ 1084 BSBattQDeltaRideAh 1;
BA_ "U_CD4_MY13_Diesel_Tx" SG_ 1084 BSBattQDeltaRideAh 1;
BA_ "U_CD4_MY13_Gas_Tx" SG_ 1084 BSBattQDeltaRideAh 1;
BA_ "U_CD4_MY13_Hev_Tx" SG_ 1084 BSBattQDeltaRideAh 1;
BA_ "U_CD4_MY13_Phev_Tx" SG_ 1084 BSBattQDeltaRideAh 1;
BA_ "U_CD42_MY14_Diesel_Tx" SG_ 1084 BSBattQDeltaRideAh 1;
BA_ "U_CD42_MY14_Gas_Tx" SG_ 1084 BSBattQDeltaRideAh 1;
BA_ "U_P552_MY15_Gas_Tx" SG_ 1084 BSBattQDeltaRideAh 1;
BA_ "U_S550_MY15_Gas_Tx" SG_ 1084 BSBattQDeltaRideAh 1;
BA_ "U_C489_MY14_Gas_Tx" SG_ 1084 BSBattQDeltaRideAh 1;
BA_ "U_U502_MY15_Gas_Tx" SG_ 1084 BSBattQDeltaRideAh 1;
BA_ "U_UP375_MY15_Gas_Tx" SG_ 1084 BSBattQDeltaRideAh 1;
BA_ "U_UP375_MY15_Diesel_Tx" SG_ 1084 BSBattQDeltaRideAh 1;
BA_ "U_CD43_MY16_Gas_Tx" SG_ 1084 BSBattQDeltaRideAh 1;
BA_ "U_CD4_MY14_Diesel_Tx" SG_ 1084 BSBattQDeltaRideAh 1;
BA_ "U_CD4_MY14_Gas_Tx" SG_ 1084 BSBattQDeltaRideAh 1;
BA_ "U_CD4_MY14_Hev_Tx" SG_ 1084 BSBattQDeltaRideAh 1;
BA_ "U_CD4_MY14_Phev_Tx" SG_ 1084 BSBattQDeltaRideAh 1;
BA_ "U_CD4_MY13_Gas_Rx" SG_ 1084 BSBattQCapAh 1;
BA_ "U_CD42_MY14_Gas_Rx" SG_ 1084 BSBattQCapAh 1;
BA_ "U_P552_MY15_Gas_Rx" SG_ 1084 BSBattQCapAh 1;
BA_ "U_S550_MY15_Gas_Rx" SG_ 1084 BSBattQCapAh 1;
BA_ "U_C489_MY14_Gas_Rx" SG_ 1084 BSBattQCapAh 1;
BA_ "U_U502_MY15_Gas_Rx" SG_ 1084 BSBattQCapAh 1;
BA_ "U_CD43_MY16_Gas_Rx" SG_ 1084 BSBattQCapAh 1;
BA_ "U_CD4_MY14_Gas_Rx" SG_ 1084 BSBattQCapAh 1;
BA_ "U_CD4_MY13_Diesel_Tx" SG_ 1084 BSBattQCapAh 1;
BA_ "U_CD4_MY13_Gas_Tx" SG_ 1084 BSBattQCapAh 1;
BA_ "U_CD4_MY13_Hev_Tx" SG_ 1084 BSBattQCapAh 1;
BA_ "U_CD4_MY13_Phev_Tx" SG_ 1084 BSBattQCapAh 1;
BA_ "U_CD42_MY14_Diesel_Tx" SG_ 1084 BSBattQCapAh 1;
BA_ "U_CD42_MY14_Gas_Tx" SG_ 1084 BSBattQCapAh 1;
BA_ "U_P552_MY15_Gas_Tx" SG_ 1084 BSBattQCapAh 1;
BA_ "U_S550_MY15_Gas_Tx" SG_ 1084 BSBattQCapAh 1;
BA_ "U_C489_MY14_Gas_Tx" SG_ 1084 BSBattQCapAh 1;
BA_ "U_U502_MY15_Gas_Tx" SG_ 1084 BSBattQCapAh 1;
BA_ "U_UP375_MY15_Gas_Tx" SG_ 1084 BSBattQCapAh 1;
BA_ "U_UP375_MY15_Diesel_Tx" SG_ 1084 BSBattQCapAh 1;
BA_ "U_CD43_MY16_Gas_Tx" SG_ 1084 BSBattQCapAh 1;
BA_ "U_CD4_MY14_Diesel_Tx" SG_ 1084 BSBattQCapAh 1;
BA_ "U_CD4_MY14_Gas_Tx" SG_ 1084 BSBattQCapAh 1;
BA_ "U_CD4_MY14_Hev_Tx" SG_ 1084 BSBattQCapAh 1;
BA_ "U_CD4_MY14_Phev_Tx" SG_ 1084 BSBattQCapAh 1;
BA_ "ContentDependant" SG_ 1086 EngOil_P_Actl 1;
BA_ "U_S550_MY15_Gas_Tx" SG_ 1086 EngOil_P_Actl 1;
BA_ "U_S550_MY15_Gas_Rx" SG_ 1086 EngOil_P_Actl 1;
BA_ "ContentDependant" SG_ 1086 EngIpcDsplyCht_Te_Actl 1;
BA_ "U_S550_MY15_Gas_Tx" SG_ 1086 EngIpcDsplyCht_Te_Actl 1;
BA_ "GenSigStartValue" SG_ 1086 EngIpcDsplyCht_Te_Actl 75;
BA_ "ContentDependant" SG_ 1086 EngIpcDsplyAfr_Rt_Actl 1;
BA_ "U_S550_MY15_Gas_Tx" SG_ 1086 EngIpcDsplyAfr_Rt_Actl 1;
BA_ "U_S550_MY15_Gas_Tx" SG_ 1086 EngMnfld_P_Actl 1;
BA_ "U_S550_MY15_Gas_Rx" SG_ 1086 EngMnfld_P_Actl 1;
BA_ "GenSigStartValue" SG_ 1086 EngMnfld_P_Actl 2068;
BA_ "U_CD4_MY13_Diesel_Rx" SG_ 1086 FuelPumpPwr_B_Rq 1;
BA_ "U_CD4_MY13_Gas_Rx" SG_ 1086 FuelPumpPwr_B_Rq 1;
BA_ "U_CD4_MY13_Hev_Rx" SG_ 1086 FuelPumpPwr_B_Rq 1;
BA_ "U_CD4_MY13_Phev_Rx" SG_ 1086 FuelPumpPwr_B_Rq 1;
BA_ "U_CD42_MY14_Diesel_Rx" SG_ 1086 FuelPumpPwr_B_Rq 1;
BA_ "U_CD42_MY14_Gas_Rx" SG_ 1086 FuelPumpPwr_B_Rq 1;
BA_ "U_P552_MY15_Gas_Rx" SG_ 1086 FuelPumpPwr_B_Rq 1;
BA_ "U_S550_MY15_Gas_Rx" SG_ 1086 FuelPumpPwr_B_Rq 1;
BA_ "U_C489_MY14_Gas_Rx" SG_ 1086 FuelPumpPwr_B_Rq 1;
BA_ "U_U502_MY15_Gas_Rx" SG_ 1086 FuelPumpPwr_B_Rq 1;
BA_ "U_UP375_MY15_Gas_Rx" SG_ 1086 FuelPumpPwr_B_Rq 1;
BA_ "U_UP375_MY15_Diesel_Rx" SG_ 1086 FuelPumpPwr_B_Rq 1;
BA_ "U_CD43_MY16_Gas_Rx" SG_ 1086 FuelPumpPwr_B_Rq 1;
BA_ "U_CD4_MY14_Diesel_Rx" SG_ 1086 FuelPumpPwr_B_Rq 1;
BA_ "U_CD4_MY14_Gas_Rx" SG_ 1086 FuelPumpPwr_B_Rq 1;
BA_ "U_CD4_MY14_Hev_Rx" SG_ 1086 FuelPumpPwr_B_Rq 1;
BA_ "U_CD4_MY14_Phev_Rx" SG_ 1086 FuelPumpPwr_B_Rq 1;
BA_ "U_CD4_MY13_Gas_Tx" SG_ 1086 FuelPumpPwr_B_Rq 1;
BA_ "U_CD42_MY14_Gas_Tx" SG_ 1086 FuelPumpPwr_B_Rq 1;
BA_ "U_P552_MY15_Gas_Tx" SG_ 1086 FuelPumpPwr_B_Rq 1;
BA_ "U_S550_MY15_Gas_Tx" SG_ 1086 FuelPumpPwr_B_Rq 1;
BA_ "U_C489_MY14_Gas_Tx" SG_ 1086 FuelPumpPwr_B_Rq 1;
BA_ "U_U502_MY15_Gas_Tx" SG_ 1086 FuelPumpPwr_B_Rq 1;
BA_ "U_UP375_MY15_Gas_Tx" SG_ 1086 FuelPumpPwr_B_Rq 1;
BA_ "U_CD43_MY16_Gas_Tx" SG_ 1086 FuelPumpPwr_B_Rq 1;
BA_ "U_CD4_MY14_Gas_Tx" SG_ 1086 FuelPumpPwr_B_Rq 1;
BA_ "U_CD4_MY13_Diesel_Rx" SG_ 1086 BattULoChrg_U_Cmd 1;
BA_ "U_CD4_MY13_Gas_Rx" SG_ 1086 BattULoChrg_U_Cmd 1;
BA_ "U_CD4_MY13_Hev_Rx" SG_ 1086 BattULoChrg_U_Cmd 1;
BA_ "U_CD4_MY13_Phev_Rx" SG_ 1086 BattULoChrg_U_Cmd 1;
BA_ "U_CD42_MY14_Diesel_Rx" SG_ 1086 BattULoChrg_U_Cmd 1;
BA_ "U_CD42_MY14_Gas_Rx" SG_ 1086 BattULoChrg_U_Cmd 1;
BA_ "U_P552_MY15_Gas_Rx" SG_ 1086 BattULoChrg_U_Cmd 1;
BA_ "U_S550_MY15_Gas_Rx" SG_ 1086 BattULoChrg_U_Cmd 1;
BA_ "U_C489_MY14_Gas_Rx" SG_ 1086 BattULoChrg_U_Cmd 1;
BA_ "U_U502_MY15_Gas_Rx" SG_ 1086 BattULoChrg_U_Cmd 1;
BA_ "U_UP375_MY15_Gas_Rx" SG_ 1086 BattULoChrg_U_Cmd 1;
BA_ "U_UP375_MY15_Diesel_Rx" SG_ 1086 BattULoChrg_U_Cmd 1;
BA_ "U_CD43_MY16_Gas_Rx" SG_ 1086 BattULoChrg_U_Cmd 1;
BA_ "U_CD4_MY14_Diesel_Rx" SG_ 1086 BattULoChrg_U_Cmd 1;
BA_ "U_CD4_MY14_Gas_Rx" SG_ 1086 BattULoChrg_U_Cmd 1;
BA_ "U_CD4_MY14_Hev_Rx" SG_ 1086 BattULoChrg_U_Cmd 1;
BA_ "U_CD4_MY14_Phev_Rx" SG_ 1086 BattULoChrg_U_Cmd 1;
BA_ "U_CD4_MY13_Gas_Tx" SG_ 1086 BattULoChrg_U_Cmd 1;
BA_ "U_CD42_MY14_Gas_Tx" SG_ 1086 BattULoChrg_U_Cmd 1;
BA_ "U_P552_MY15_Gas_Tx" SG_ 1086 BattULoChrg_U_Cmd 1;
BA_ "U_S550_MY15_Gas_Tx" SG_ 1086 BattULoChrg_U_Cmd 1;
BA_ "U_C489_MY14_Gas_Tx" SG_ 1086 BattULoChrg_U_Cmd 1;
BA_ "U_U502_MY15_Gas_Tx" SG_ 1086 BattULoChrg_U_Cmd 1;
BA_ "U_UP375_MY15_Gas_Tx" SG_ 1086 BattULoChrg_U_Cmd 1;
BA_ "U_CD43_MY16_Gas_Tx" SG_ 1086 BattULoChrg_U_Cmd 1;
BA_ "U_CD4_MY14_Gas_Tx" SG_ 1086 BattULoChrg_U_Cmd 1;
BA_ "ContentDependant" SG_ 1086 ElLoadCtl_D_Rq 1;
BA_ "U_CD4_MY13_Diesel_Rx" SG_ 1086 ElLoadCtl_D_Rq 1;
BA_ "U_CD4_MY13_Gas_Rx" SG_ 1086 ElLoadCtl_D_Rq 1;
BA_ "U_CD4_MY13_Hev_Rx" SG_ 1086 ElLoadCtl_D_Rq 1;
BA_ "U_CD4_MY13_Phev_Rx" SG_ 1086 ElLoadCtl_D_Rq 1;
BA_ "U_CD42_MY14_Diesel_Rx" SG_ 1086 ElLoadCtl_D_Rq 1;
BA_ "U_CD42_MY14_Gas_Rx" SG_ 1086 ElLoadCtl_D_Rq 1;
BA_ "U_P552_MY15_Gas_Rx" SG_ 1086 ElLoadCtl_D_Rq 1;
BA_ "U_S550_MY15_Gas_Rx" SG_ 1086 ElLoadCtl_D_Rq 1;
BA_ "U_C489_MY14_Gas_Rx" SG_ 1086 ElLoadCtl_D_Rq 1;
BA_ "U_U502_MY15_Gas_Rx" SG_ 1086 ElLoadCtl_D_Rq 1;
BA_ "U_UP375_MY15_Gas_Rx" SG_ 1086 ElLoadCtl_D_Rq 1;
BA_ "U_UP375_MY15_Diesel_Rx" SG_ 1086 ElLoadCtl_D_Rq 1;
BA_ "U_CD43_MY16_Gas_Rx" SG_ 1086 ElLoadCtl_D_Rq 1;
BA_ "U_CD4_MY14_Diesel_Rx" SG_ 1086 ElLoadCtl_D_Rq 1;
BA_ "U_CD4_MY14_Gas_Rx" SG_ 1086 ElLoadCtl_D_Rq 1;
BA_ "U_CD4_MY14_Hev_Rx" SG_ 1086 ElLoadCtl_D_Rq 1;
BA_ "U_CD4_MY14_Phev_Rx" SG_ 1086 ElLoadCtl_D_Rq 1;
BA_ "U_CD4_MY13_Gas_Tx" SG_ 1086 ElLoadCtl_D_Rq 1;
BA_ "U_CD42_MY14_Gas_Tx" SG_ 1086 ElLoadCtl_D_Rq 1;
BA_ "U_P552_MY15_Gas_Tx" SG_ 1086 ElLoadCtl_D_Rq 1;
BA_ "U_S550_MY15_Gas_Tx" SG_ 1086 ElLoadCtl_D_Rq 1;
BA_ "U_C489_MY14_Gas_Tx" SG_ 1086 ElLoadCtl_D_Rq 1;
BA_ "U_U502_MY15_Gas_Tx" SG_ 1086 ElLoadCtl_D_Rq 1;
BA_ "U_UP375_MY15_Gas_Tx" SG_ 1086 ElLoadCtl_D_Rq 1;
BA_ "U_CD43_MY16_Gas_Tx" SG_ 1086 ElLoadCtl_D_Rq 1;
BA_ "U_CD4_MY14_Gas_Tx" SG_ 1086 ElLoadCtl_D_Rq 1;
VAL_ 753 Em_D_Stat_UB 1 "Fresh_data" 0 "Unchanged_data" ;
VAL_ 753 Em_D_Stat 3 "NotSupported" 2 "ProfilesOff" 1 "ProfilesOn" 0 "Null" ;
VAL_ 753 TrlrAidEnbl_D_Stat_UB 1 "Fresh_data" 0 "Unchanged_data" ;
VAL_ 753 TrlrAidEnbl_D_Stat 7 "Faulty" 6 "NoDataExists" 5 "TbaRecalibrate" 4 "TbaTadMonitor" 3 "TbaNotAvailable" 2 "TbaStandby" 1 "TbaActive" 0 "Null" ;
VAL_ 753 SeatOccDrv_B_Stat_UB 1 "Fresh_data" 0 "Unchanged_data" ;
VAL_ 753 SeatOccDrv_B_Stat 1 "Active" 0 "Inactive" ;
VAL_ 753 TrlrAidSetup_D_Rq_UB 1 "Fresh_data" 0 "Unchanged_data" ;
VAL_ 753 TrlrAidSetup_D_Rq 3 "NotUsed" 2 "EndSetup" 1 "BeginSetup" 0 "Inactive" ;
VAL_ 753 TurnLampRrOut_B_Stat_UB 1 "Fresh_data" 0 "Unchanged_data" ;
VAL_ 753 TurnLampRrOut_B_Stat 1 "Out" 0 "Null" ;
VAL_ 753 TurnLampRlOut_B_Stat_UB 1 "Fresh_data" 0 "Unchanged_data" ;
VAL_ 753 TurnLampRlOut_B_Stat 1 "Out" 0 "Null" ;
VAL_ 753 CnvtTopPos_Up_Stat_UB 1 "Fresh_data" 0 "Unchanged_data" ;
VAL_ 753 IsaOffst_D_Rq_UB 1 "Fresh_data" 0 "Unchanged_data" ;
VAL_ 753 GlvBoxRleas_No_Actl_UB 1 "Fresh_data" 0 "Unchanged_data" ;
VAL_ 753 ValetMode_D_Stat_UB 1 "Fresh_data" 0 "Unchanged_data" ;
VAL_ 753 RollCodeValet_UB 1 "Fresh_data" 0 "Unchanged_data" ;
VAL_ 753 ApaMdeStat_D_RqDrv_UB 1 "Fresh_data" 0 "Unchanged_data" ;
VAL_ 753 SlMde_D_Rq 3 "NotUsed" 2 "Manual_Mode" 1 "Auto_Mode" 0 "Null" ;
VAL_ 753 IsaOffst_D_Rq 15 "Faulty" 14 "Null" 13 "Thirteen" 12 "Twelve" 11 "Eleven" 10 "Ten" 9 "Nine" 8 "Eight" 7 "Seven" 6 "Six" 5 "Five" 4 "Four" 3 "Three" 2 "Two" 1 "One" 0 "Zero" ;
VAL_ 753 ApaMdeStat_D_RqDrv 7 "Faulty" 6 "Off" 5 "NotUsed2" 4 "NotUsed1" 3 "POA" 2 "PPA" 1 "SAPP" 0 "Inactive" ;
VAL_ 753 ValetMode_D_Stat 3 "Not used_3" 2 "On" 1 "Off" 0 "Null" ;
VAL_ 753 CnvtTopPos_Up_Stat 1 "Up" 0 "Not_Up" ;
VAL_ 753 CnvtTopPos_Dn_Stat_UB 1 "Fresh_data" 0 "Unchanged_data" ;
VAL_ 753 CnvtTopPos_Dn_Stat 1 "Down" 0 "Not_Down" ;
VAL_ 818 KeyCylSwDrvDr_D_Stat 3 "Not Used" 2 "Unlock" 1 "Lock" 0 "Null" ;
VAL_ 818 Driver_Lock_Sw_Stat 3 "Invalid" 2 "Unlock" 1 "Lock" 0 "Null" ;
VAL_ 818 ChildLckPw_D_Rq 1 "Active" 0 "Null" ;
VAL_ 818 ChildLckFdbckRd_B_Stat 1 "Locked" 0 "Unlock" ;
VAL_ 817 ChildLckMde_B_Stat 1 "Enable" 0 "Disable" ;
VAL_ 817 VehLckInd_D_Rq 3 "NotUsed" 2 "On_Day" 1 "On_Night" 0 "Off" ;
VAL_ 817 DrTgateOpen_B_Rq 1 "Open" 0 "Null" ;
VAL_ 817 DrTgateExtSwMde_B_Stat 1 "Enable" 0 "Disable" ;
VAL_ 817 Remote_Device_Feedback 7 "Unused3" 6 "Unused2" 5 "Unused1" 4 "Shutdown" 3 "Running" 2 "Starting" 1 "Acknowledge" 0 "Null" ;
VAL_ 817 Veh_Lock_Requestor 31 "Unused8" 30 "Unused7" 29 "Unused6" 28 "Unused5" 27 "Unused4" 26 "Unused3" 25 "Unused2" 24 "Unused1" 23 "Diagnostics" 22 "Console_Lock" 21 "Child_Lock" 20 "Double_Lock" 19 "Passive_Pasenger" 18 "Passive_Driver" 17 "Slam_Lock_Protect" 16 "SYNC" 15 "Passport" 14 "Passive_Smart_Unlock" 13 "Autorelock" 12 "RemoteStart" 0 "Null" 1 "Autolock" 11 "Smart_Unlock" 10 "Sliding_Door" 9 "Passive" 8 "Remote" 7 "Programming" 6 "Powerslide" 5 "Keypad" 4 "Key_Cylinder" 3 "Interior" 2 "Auto_Unlock" ;
VAL_ 817 R_Pwr_Sliding_Dr_Rqst 1 "Active" 0 "Null" ;
VAL_ 817 Power_Liftgate_Rqst 1 "Active" 0 "Null" ;
VAL_ 817 Power_Decklid_Rqst 1 "Active" 0 "Null" ;
VAL_ 817 L_Pwr_Sliding_Dr_Rqst 1 "Active" 0 "Null" ;
VAL_ 817 Veh_Lock_Sub_Id 15 "Unused7" 14 "Unused6" 13 "Unused5" 12 "Unused4" 11 "Unused3" 10 "Unused2" 9 "Unused1" 8 "Customer_8" 7 "Customer_7" 6 "Customer_6" 5 "Customer_5" 4 "Customer_4" 3 "Customer_3" 2 "Customer_2" 1 "Customer_1" 0 "Null" ;
VAL_ 817 Veh_Lock_Status 3 "UNLOCK_DRV" 2 "UNLOCK_ALL" 1 "LOCK_ALL" 0 "LOCK_DBL" ;
VAL_ 817 ChildLck_D_Dsply 3 "NOT_SUPPORTED" 2 "ERROR" 1 "CHILD_UNLOCK" 0 "CHILD_LOCK" ;
VAL_ 817 WindowLockout_B_Stat 1 "Locked" 0 "Unlock" ;
VAL_ 817 Lockmsgtxt_D_Rq 7 "MSG7" 6 "MSG6" 5 "MSG5" 4 "MSG4" 3 "MSG3" 2 "MSG2" 1 "MSG1" 0 "NO_WARNING" ;
VAL_ 817 FobComm_D_Stat 3 "NotUsed" 2 "RemEngStartOK" 1 "RemEngStartFail" 0 "Null" ;
VAL_ 817 LockInhibit 1 "Inhibit" 0 "No_Inhibit" ;
VAL_ 1002 CntrStk_D_RqRecall 7 "Unused_2" 6 "Unused_1" 5 "Vehicle" 4 "PERS_4" 3 "PERS_3" 2 "PERS_2" 1 "PERS_1" 0 "Null" ;
VAL_ 1002 CntrStk_D_RqAssoc 7 "Unused_2" 6 "Unused_1" 5 "Set_Keycode" 4 "RKE" 3 "Null" 2 "Key" 1 "Erase_KeyCode" 0 "Check_KeyCode" ;
VAL_ 1002 PersIndexApim_D_Actl 7 "Unused_3" 6 "Unused_2" 5 "Unused_1" 4 "Vehicle" 3 "PERS_4" 2 "PERS_3" 1 "PERS_2" 0 "PERS_1" ;
VAL_ 390 AccStopStat_B_Rq 1 "Yes" 0 "No" ;
VAL_ 390 AccResumEnbl_B_Rq 1 "Yes" 0 "No" ;
VAL_ 390 AccBrkPrkEl_B_Rq 1 "Yes" 0 "No" ;
VAL_ 390 Cmbb_B_Enbl 1 "Yes" 0 "No" ;
VAL_ 390 CmbbOvrrd_B_RqDrv 1 "Yes" 0 "No" ;
VAL_ 390 CmbbDeny_B_Actl 1 "Yes" 0 "No" ;
VAL_ 390 CmbbEngTqMn_B_Rq 1 "Yes" 0 "No" ;
VAL_ 390 AccDeny_B_Rq 1 "Yes" 0 "No" ;
VAL_ 390 AccCancl_B_Rq 1 "Yes" 0 "No" ;
VAL_ 390 AccBrkPrchg_B_Rq 1 "Yes" 0 "No" ;
VAL_ 390 AccBrkDecel_B_Rq 1 "Active" 0 "Inactive" ;
VAL_ 1046 HdcMde_D_Actl 7 "Fault" 6 "Temporarily_Unavailable" 5 "NotEnabled_WrongGearSel" 4 "NotEnabled_SpdLimitExceed" 3 "Active_Braking" 2 "Not_Active_Braking" 1 "Off" 0 "Undefined" ;
VAL_ 1046 StabCtlBrk_B_Avail 1 "Yes" 0 "No" ;
VAL_ 1046 BrkBstrVac_B_Rq 1 "Yes" 0 "No" ;
VAL_ 1046 DrvSlipCtlMde_D_Ind 3 "App_Specific_Off_Mode_3" 2 "App_Specific_Off_Mode_2" 1 "App_Specific_Off_Mode_1" 0 "Default_Mode" ;
VAL_ 1046 DrvAntiLckLamp_D_Rq 3 "Fast_Flash" 2 "Slow_Flash" 1 "On" 0 "Off" ;
VAL_ 1046 DrvHdcLampInfo_D_Rq 3 "Fast_Flash" 2 "Slow_Flash" 1 "On" 0 "Off" ;
VAL_ 1046 ChimeBrk_B_Rq 1 "Yes" 0 "No" ;
VAL_ 1046 BrkLamp_B_Rq 1 "Yes" 0 "No" ;
VAL_ 1046 HILL_DESC_MC 7 "Fault_Detected" 6 "Cooling_Down" 5 "Abort_Apply_Brakes" 4 "Active" 3 "Disabled" 2 "Enabled" 1 "Off_Road" 0 "Normal" ;
VAL_ 1046 TCMode 1 "Active" 0 "Inactive" ;
VAL_ 1046 DrvSlipCtlLamp_D_Rq 3 "Fast_Flash" 2 "Slow_Flash" 1 "On" 0 "Off" ;
VAL_ 1046 Abs_B_Falt 1 "Yes" 0 "No" ;
VAL_ 1046 BpedMove_D_Actl 3 "Unknown" 2 "DriverApplyingBrakePedal" 1 "NoAutonomousBrkPdlMovement" 0 "AutonomousBrkPedalMove" ;
VAL_ 125 VehRolComp_W_Actl 4094 "NoDataExists" 4095 "Fault" ;
VAL_ 125 VehVertComp_A_Actl 1022 "NoDataExists" 1023 "Fault" ;
VAL_ 125 BrkTot_Tq_RqArb 8191 "Fault" 8190 "Unknown" ;
VAL_ 125 BrkTot_Tq_Actl 8191 "Fault" 8190 "Unknown" ;
VAL_ 125 HsaStat_D_Actl 7 "Undefined" 6 "Failed" 5 "SlowRelease" 4 "FastRelease" 3 "ActiveBrakePedalReleased" 2 "ActiveBrakePedalPressed" 1 "FindingGradient" 0 "Inactive" ;
VAL_ 119 VehLongComp_A_Actl 1023 "Fault" 1022 "NoDataExists" ;
VAL_ 119 VehLatComp_A_Actl 1023 "Fault" 1022 "NoDataExists" ;
VAL_ 119 VehYawComp_W_Actl 4095 "Fault" 4094 "NoDataExists" ;
VAL_ 119 VehOverGnd_V_Est 65535 "Invalid" 65534 "Unknown" ;
VAL_ 1045 VehYawLin_W_Rq 4095 "Fault" 4094 "Unknown" ;
VAL_ 1045 VehYawNonLin_W_Rq 4095 "Fault" 4094 "Unknown" ;
VAL_ 1045 VehVActlBrk_D_Qf 3 "OK" 2 "Not_Within_Specifications" 1 "No_Data_Exists" 0 "Faulty" ;
VAL_ 534 WhlDirRr_D_Actl 3 "Failed" 2 "Unknown" 1 "Backward" 0 "Forward" ;
VAL_ 534 WhlDirRl_D_Actl 3 "Failed" 2 "Unknown" 1 "Backward" 0 "Forward" ;
VAL_ 534 WhlDirFr_D_Actl 3 "Failed" 2 "Unknown" 1 "Backward" 0 "Forward" ;
VAL_ 534 WhlDirFl_D_Actl 3 "Failed" 2 "Unknown" 1 "Backward" 0 "Forward" ;
VAL_ 531 AccStopActv_B_ActlBrk 1 "Yes" 0 "No" ;
VAL_ 531 TracCtlPtActv_B_Actl 1 "Active" 0 "Inactive" ;
VAL_ 531 StabCtlBrkActv_B_Actl 1 "Yes" 0 "No" ;
VAL_ 531 CmbbBrkPrchg_B_Actl 1 "Yes" 0 "No" ;
VAL_ 531 CmbbBrkDecel_B_Actl 1 "Yes" 0 "No" ;
VAL_ 531 CmbbBaSensInc_B_Actl 1 "Yes" 0 "No" ;
VAL_ 531 AccBrkWarm_B_Actl 1 "Yes" 0 "No" ;
VAL_ 531 AccBrkTotTqMn_B_Actl 1 "Yes" 0 "No" ;
VAL_ 531 AccBrkPrchgActv_B_Actl 1 "Yes" 0 "No" ;
VAL_ 531 AccBrkDis_B_Actl 1 "Yes" 0 "No" ;
VAL_ 531 AccBrkDeny_B_Actl 1 "Yes" 0 "No" ;
VAL_ 531 AccBrkActv_B_Actl 1 "Yes" 0 "No" ;
VAL_ 531 PrplDrgCtlActv_B_Actl 1 "Active" 0 "Inactive" ;
VAL_ 531 AbsActv_B_Actl 1 "Yes" 0 "No" ;
VAL_ 531 CmbbBrkDis_B_Actl 1 "Yes" 0 "No" ;
VAL_ 531 CmbbDeny_B_ActlBrk 1 "Yes" 0 "No" ;
VAL_ 531 CcDis_B_Cmd 1 "Yes" 0 "No" ;
VAL_ 531 VehLongOvrGnd_A_Est 1023 "Fault" 1022 "Unknown" ;
VAL_ 531 PrkBrkStatus 7 "GeneralFault_MaintenceMode" 6 "ECD_by_Brake_ECU_Active" 5 "EPB_Limphome_Active" 4 "Rear_Caliper_Open" 3 "RWU_By_EPB_Active" 2 "Rear_Caliper_Transition" 1 "Rear_Caliper_Closed" 0 "Not_Supported" ;
VAL_ 535 WhlRr_W_Meas 32767 "Fault" 32766 "Unknown" ;
VAL_ 535 WhlRl_W_Meas 32767 "Fault" 32766 "Unknown" ;
VAL_ 535 WhlFr_W_Meas 32767 "Fault" 32766 "Unknown" ;
VAL_ 535 WhlFl_W_Meas 32767 "Fault" 32766 "Unknown" ;
VAL_ 611 AwdRnge_D_ActlIpc_UB 1 "Fresh_data" 0 "Unchanged_data" ;
VAL_ 611 AwdRnge_D_ActlIpc 7 "Unknown" 6 "High_Range_2wd" 5 "High_Range_Auto" 4 "High_Range_Locked" 3 "Neutral" 2 "Low_Range_2wd" 1 "Low_Range_Auto" 0 "Low_Range_Locked" ;
VAL_ 611 AwdSrvcRqd_B_Rq_UB 1 "Fresh_data" 0 "Unchanged_data" ;
VAL_ 611 AwdSrvcRqd_B_Rq 1 "On" 0 "Off" ;
VAL_ 611 RearDiffLck_Tq_Actl_UB 1 "Fresh_data" 0 "Unchanged_data" ;
VAL_ 611 RearDiffLck_Tq_Actl 4095 "Fault" 4094 "Unknown" ;
VAL_ 611 AwdSys_D_Stat_UB 1 "Fresh_data" 0 "Unchanged_data" ;
VAL_ 611 AwdSys_D_Stat 3 "Faulty" 2 "NotUsed" 1 "_4x4_L_H_Active" 0 "_4x4_L_H_Inactive" ;
VAL_ 611 AwdRnge_D_Actl 7 "Unknown" 6 "High_Range_2wd" 5 "High_Range_Auto" 4 "High_Range_Locked" 3 "Neutral" 2 "Low_Range_2wd" 1 "Low_Range_Auto" 0 "Low_Range_Locked" ;
VAL_ 611 TrnAout_Tq_RqMx_UB 1 "Fresh_data" 0 "Unchanged_data" ;
VAL_ 611 AwdRnge_D_Actl_UB 1 "Fresh_data" 0 "Unchanged_data" ;
VAL_ 1109 eCallConfirmation 7 "Unused_2" 6 "CallComplete_DTMF_Timeout" 5 "eCall_Configured_Off" 4 "Call_Unsuccessful" 3 "Call_Cancelled" 2 "Call_Completed" 1 "Call_In_Progress" 0 "Normal" ;
VAL_ 359 ElPw_D_StatStrtStop 15 "NotUsed6" 14 "NotUsed5" 13 "NotUsed4" 12 "NotUsed3" 11 "NotUsed2" 10 "NotUsed1" 9 "Supported_Level_4" 8 "Supported_Level_3" 7 "Supported_Level_2" 6 "Supported_Level_1" 5 "Limited_Support" 4 "Fault_Limited" 3 "LV_Event_in_Progress" 2 "Not_Supported_Imminent" 1 "Supported_All" 0 "Not_Supported" ;
VAL_ 359 PrplWhlTot2_Tq_Actl 65535 "Fault" 65534 "NoDataExists" ;
VAL_ 359 PwPckTq_D_Stat 3 "PwPckOn_TqAvailable" 2 "StartInPrgrss_TqNotAvail" 1 "PwPckOn_TqNotAvailable" 0 "PwPckOff_TqNotAvailable" ;
VAL_ 359 Eng_D_Stat 3 "NotUsed" 2 "EngAutoStopped" 1 "EngOn" 0 "EngOff" ;
VAL_ 359 ElPw_D_Stat 7 "NotUsed_3" 6 "NotUsed_2" 5 "NotUsed_1" 4 "Fault_Limited" 3 "LV_Event_In_Progress" 2 "Not_Supported_Imminent" 1 "Supported" 0 "Not_Supported" ;
VAL_ 359 TrnAinTq_D_Qf 3 "OK" 2 "Not_Within_Specifications" 1 "No_Data_Exists" 0 "Faulty" ;
VAL_ 358 StopStrtStdby_D_Indic 6 "NotUsed2" 5 "Telltale_Struck_Out" 4 "Telltale_Flashing_Amber" 3 "Telltale_On_Amber" 2 "Telltale_Flashing_Green" 1 "Telltale_On_Green" 0 "Telltale_Off" 7 "NotUsed3" ;
VAL_ 358 StopStrtIODTxt_D_Rq 31 "Message31" 30 "Message30" 29 "Message29" 28 "Message28" 27 "Message27" 26 "Message26" 25 "Message25" 24 "Message24" 23 "Message23" 22 "Message22" 21 "Message21" 20 "Message20" 19 "Message19" 18 "Message18" 17 "Message17" 16 "Message16" 15 "Message15" 14 "Message14" 13 "Message13" 12 "Message12" 11 "Message11" 10 "Message10" 9 "Message9" 8 "Message8" 7 "Message7" 6 "Message6" 5 "Message5" 4 "Message4" 3 "Message3" 2 "Message2" 1 "Message1" 0 "NoMessage" ;
VAL_ 358 StopStrtDrvMde_D_Indic 3 "NotUsed" 2 "StartStop_IndirectDeselect" 1 "StopStart_Deselected" 0 "StopStart_Selected" ;
VAL_ 358 StopStrtMsgTxt_D_Rq 15 "Message_15" 14 "Message_14" 13 "Message_13" 12 "Message_12" 11 "Message_11" 10 "Message_10" 9 "Message_9" 8 "Message_8" 7 "Message_7" 6 "Message_6" 5 "Message_5" 4 "Message_4" 3 "Message_3" 2 "Message_2" 1 "Message_1" 0 "NoMessage" ;
VAL_ 358 OdoTripVerify_L_Actl 16777215 "Fault" ;
VAL_ 358 HiElPwInhbt_B_Stat 1 "Inhibit" 0 "No_Inibit" ;
VAL_ 358 AutoStopPtDelta_I_Est 255 "Fault" ;
VAL_ 1078 UStabLvl2OvrTe_B_Stat 1 "Yes" 0 "No" ;
VAL_ 1078 UStabLvl2Ovrld_B_Stat 1 "Yes" 0 "No" ;
VAL_ 1078 UStabLvl2_D_Stat 3 "Fault" 2 "Active" 1 "Ready" 0 "Not_Ready" ;
VAL_ 1084 BattULoState_D_Qlty 3 "OK" 2 "Not_Within_Specifications" 1 "Eval_In_Progress" 0 "Fault" ;
VAL_ 1084 BSFault 1 "Fault" 0 "No_Fault" ;
VAL_ 1084 BattULo2_Te_Actl 127 "Fault" ;
VAL_ 1086 FuelPumpPwr_B_Rq 1 "On" 0 "Off" ;
VAL_ 1086 ElLoadCtl_D_Rq 7 "Unused3" 6 "Unused2" 5 "Unused1" 4 "HoldAllDrvrInvisibleLoads" 3 "StdDriverInvisibleLoadsOn" 2 "AllDriverInvisibleLoadsOn" 1 "All_Possible_Loads_Off" 0 "No_Request" ;
